VERSION ""

NS_ :

BS_:

BU_: BCM BMS_12V CMS_D CMS_P DSMU ECDO METER MID PBD PSB_D PSB_P PSCU RSCU2R RSCU3R SCCM SRVM VSP

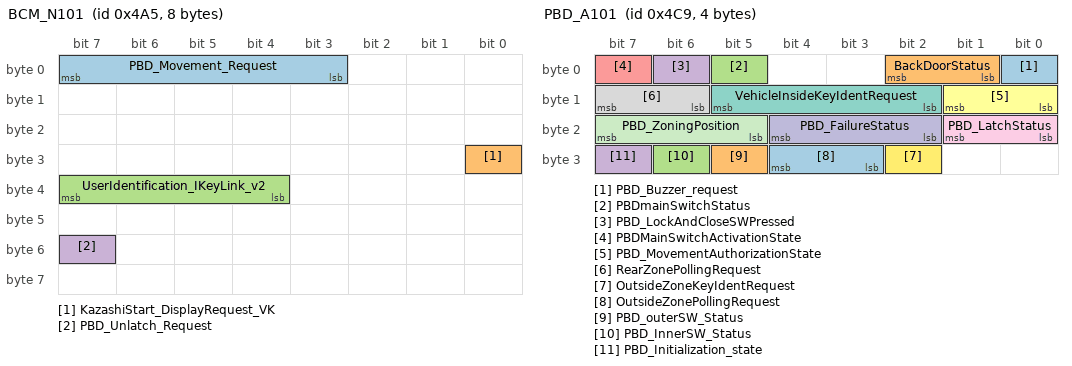
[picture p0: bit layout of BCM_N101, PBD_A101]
BO_ 1189 BCM_N101: 8 BCM
  SG_ PBD_Movement_Request : 7|5@0+ (1,0) [0|0] "" PBD
  SG_ KazashiStart_DisplayRequest_VK : 24|1@0+ (1,0) [0|0] "" METER
  SG_ UserIdentification_IKeyLink_v2 : 39|4@0+ (1,0) [0|0] "" CMS_D,CMS_P,DSMU,METER
  SG_ PBD_Unlatch_Request : 55|1@0+ (1,0) [0|0] "" PBD

BO_ 1191 VADA_R1: 1 BCM
  SG_ VADA_FailureDisplayRequest : 5|1@0+ (1,0) [0|0] "" METER

BO_ 1202 AVM_A102: 6 BCM
  SG_ APA_CancelReasonRER : 26|1@0+ (1,0) [0|0] "" METER
  SG_ APA_CancelReason : 28|2@0+ (1,0) [0|0] "" METER

BO_ 1203 FRCAMERA_A110: 5 BCM
  SG_ OSPSpeedLimit_Display : 7|8@0+ (1,5) [5|200] "Kmh/Mph" METER
  SG_ CruiseControlOSPDisplayRequest : 28|2@0+ (1,0) [0|0] "" METER
  SG_ OSPSpeedLimitZone2_Display : 39|8@0+ (1,5) [5|200] "s" METER

BO_ 1208 AirSUSP_A102: 4 BCM
  SG_ CRC_AirSUSP_A102 : 7|8@0+ (1,0) [0|255] "" METER
  SG_ AirSusp_CurrentHeightDisplay : 11|3@0+ (1,0) [0|0] "" METER
  SG_ Clock_AirSUSP_A102 : 15|4@0+ (1,0) [0|15] "" METER
  SG_ AirSusp_OperationStatusDisplay : 23|2@0+ (1,0) [0|0] "" METER

BO_ 1221 BSWL_A6: 2 BCM
  SG_ BSWrad_ActivationStateSlave : 15|1@0+ (1,0) [0|0] "" METER

BO_ 1225 PBD_A101: 4 PBD
  SG_ PBD_Buzzer_request : 0|1@0+ (1,0) [0|0] "" BCM
  SG_ BackDoorStatus : 2|2@0+ (1,0) [0|0] "" BCM
  SG_ PBDmainSwitchStatus : 5|1@0+ (1,0) [0|0] "" BCM
  SG_ PBD_LockAndCloseSWPressed : 6|1@0+ (1,0) [0|0] "" BCM
  SG_ PBDMainSwitchActivationState : 7|1@0+ (1,0) [0|0] "" METER
  SG_ PBD_MovementAuthorizationState : 9|2@0+ (1,0) [0|0] "" BCM
  SG_ VehicleInsideKeyIdentRequest : 13|4@0+ (1,0) [0|0] "" BCM
  SG_ RearZonePollingRequest : 15|2@0+ (1,0) [0|0] "" BCM
  SG_ PBD_LatchStatus : 17|2@0+ (1,0) [0|0] "" BCM
  SG_ PBD_FailureStatus : 20|3@0+ (1,0) [0|0] "" BCM
  SG_ PBD_ZoningPosition : 23|3@0+ (1,0) [0|0] "" BCM
  SG_ OutsideZoneKeyIdentRequest : 26|1@0+ (1,0) [0|0] "" BCM
  SG_ OutsideZonePollingRequest : 28|2@0+ (1,0) [0|0] "" BCM
  SG_ PBD_outerSW_Status : 29|1@0+ (1,0) [0|0] "" BCM
  SG_ PBD_InnerSW_Status : 30|1@0+ (1,0) [0|0] "" BCM
  SG_ PBD_Initialization_state : 31|1@0+ (1,0) [0|0] "" BCM

BO_ 1227 BCM_A124: 2 BCM
  SG_ AmbiLightADLINKTypeStatus : 0|2@0+ (1,0) [0|0] "" METER
  SG_ AmbiLightADColorStatus : 7|7@0+ (1,0) [0|0] "" METER

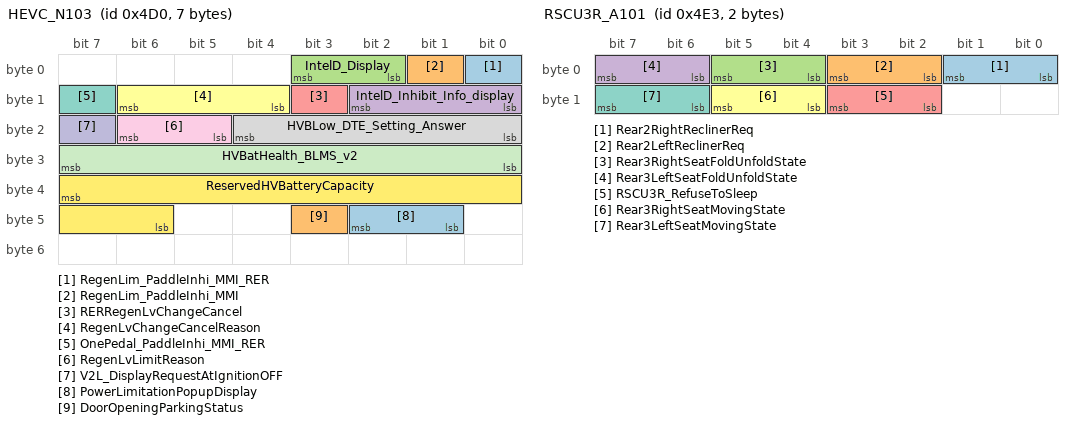
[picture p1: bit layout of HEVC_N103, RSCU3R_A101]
BO_ 1232 HEVC_N103: 7 BCM
  SG_ RegenLim_PaddleInhi_MMI_RER : 0|1@0+ (1,0) [0|0] "" METER
  SG_ RegenLim_PaddleInhi_MMI : 1|1@0+ (1,0) [0|0] "" METER
  SG_ IntelD_Display : 3|2@0+ (1,0) [0|0] "" METER
  SG_ IntelD_Inhibit_Info_display : 10|3@0+ (1,0) [0|0] "" METER
  SG_ RERRegenLvChangeCancel : 11|1@0+ (1,0) [0|0] "" METER
  SG_ RegenLvChangeCancelReason : 14|3@0+ (1,0) [0|0] "" METER
  SG_ OnePedal_PaddleInhi_MMI_RER : 15|1@0+ (1,0) [0|0] "" METER
  SG_ HVBLow_DTE_Setting_Answer : 20|5@0+ (1,0) [0|0] "" METER
  SG_ RegenLvLimitReason : 22|2@0+ (1,0) [0|0] "" METER
  SG_ V2L_DisplayRequestAtIgnitionOFF : 23|1@0+ (1,0) [0|0] "" METER
  SG_ HVBatHealth_BLMS_v2 : 31|8@0+ (0.4,0) [0|100] "%" METER
  SG_ ReservedHVBatteryCapacity : 39|10@0+ (0.1,0) [0|100] "kWh" METER
  SG_ PowerLimitationPopupDisplay : 42|2@0+ (1,0) [0|0] "" METER
  SG_ DoorOpeningParkingStatus : 43|1@0+ (1,0) [0|0] "" METER

BO_ 1237 METER_N102: 4 METER
  SG_ MIDLuminosity : 7|8@0+ (0.4,0) [0|100] "%" MID
  SG_ CIDLuminosity : 15|8@0+ (0.4,0) [0|100] "%" MID

BO_ 1239 ECM_R103: 7 BCM
  SG_ LPGFuelLevelPercentage_MMI : 39|8@0+ (0.5,0) [0|100] "%" METER

BO_ 1241 HFM_A9: 1 BCM
  SG_ CustomerIdentType : 7|1@0+ (1,0) [0|0] "" METER

BO_ 1251 RSCU3R_A101: 2 RSCU3R
  SG_ Rear2RightReclinerReq : 1|2@0+ (1,0) [0|0] "" RSCU2R
  SG_ Rear2LeftReclinerReq : 3|2@0+ (1,0) [0|0] "" RSCU2R
  SG_ Rear3RightSeatFoldUnfoldState : 5|2@0+ (1,0) [0|0] "" BCM
  SG_ Rear3LeftSeatFoldUnfoldState : 7|2@0+ (1,0) [0|0] "" BCM
  SG_ RSCU3R_RefuseToSleep : 11|2@0+ (1,0) [0|0] "" BCM
  SG_ Rear3RightSeatMovingState : 13|2@0+ (1,0) [0|0] "" BCM
  SG_ Rear3LeftSeatMovingState : 15|2@0+ (1,0) [0|0] "" BCM

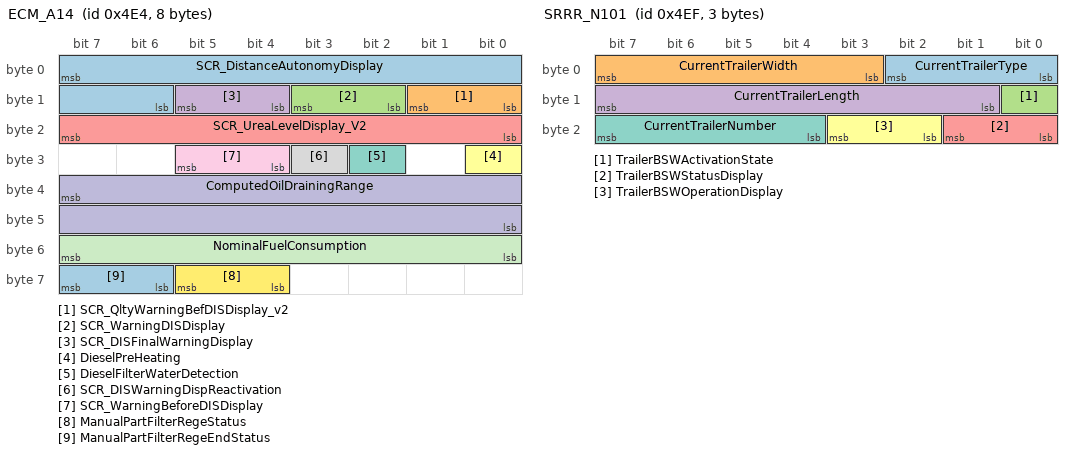
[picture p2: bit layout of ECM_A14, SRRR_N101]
BO_ 1252 ECM_A14: 8 BCM
  SG_ SCR_DistanceAutonomyDisplay : 7|10@0+ (1,0) [0|1022] "km" METER
  SG_ SCR_QltyWarningBefDISDisplay_v2 : 9|2@0+ (1,0) [0|0] "" METER
  SG_ SCR_WarningDISDisplay : 11|2@0+ (1,0) [0|0] "" METER
  SG_ SCR_DISFinalWarningDisplay : 13|2@0+ (1,0) [0|0] "" METER
  SG_ SCR_UreaLevelDisplay_V2 : 23|8@0+ (0.5,0) [0|100] "%" METER
  SG_ DieselPreHeating : 24|1@0+ (1,0) [0|0] "" METER
  SG_ DieselFilterWaterDetection : 26|1@0+ (1,0) [0|0] "" METER
  SG_ SCR_DISWarningDispReactivation : 27|1@0+ (1,0) [0|0] "" METER
  SG_ SCR_WarningBeforeDISDisplay : 29|2@0+ (1,0) [0|0] "" METER
  SG_ ComputedOilDrainingRange : 39|16@0+ (1,0) [0|65534] "km" METER
  SG_ NominalFuelConsumption : 55|8@0+ (80,0) [0|20400] "mm3" METER
  SG_ ManualPartFilterRegeStatus : 61|2@0+ (1,0) [0|0] "" METER
  SG_ ManualPartFilterRegeEndStatus : 63|2@0+ (1,0) [0|0] "" METER

BO_ 1263 SRRR_N101: 3 BCM
  SG_ CurrentTrailerType : 2|3@0+ (1,0) [0|0] "" METER
  SG_ CurrentTrailerWidth : 7|5@0+ (0.25,0) [0.25|7.25] "m" METER
  SG_ TrailerBSWActivationState : 8|1@0+ (1,0) [0|0] "" METER
  SG_ CurrentTrailerLength : 15|7@0+ (0.25,0) [0.25|31.25] "m" METER
  SG_ TrailerBSWStatusDisplay : 17|2@0+ (1,0) [0|0] "" METER
  SG_ TrailerBSWOperationDisplay : 19|2@0+ (1,0) [0|0] "" METER
  SG_ CurrentTrailerNumber : 23|4@0+ (1,0) [0|0] "" METER

BO_ 1271 HEVC_R134: 4 BCM
  SG_ H2_Consumption_kg100km : 7|10@0+ (0.01,0) [0|10] "Kg/100Km" METER
  SG_ CumulatedAutonomyDisplay : 13|11@0+ (1,0) [0|2047] "KM" METER
  SG_ H2AutonomyZEVdisplay : 18|10@0+ (1,0) [0|1022] "-" METER

BO_ 1273 PSD_A103: 1 BCM
  SG_ PSD_Right_BuzzerActivationStatus : 7|1@0+ (1,0) [0|0] "" METER

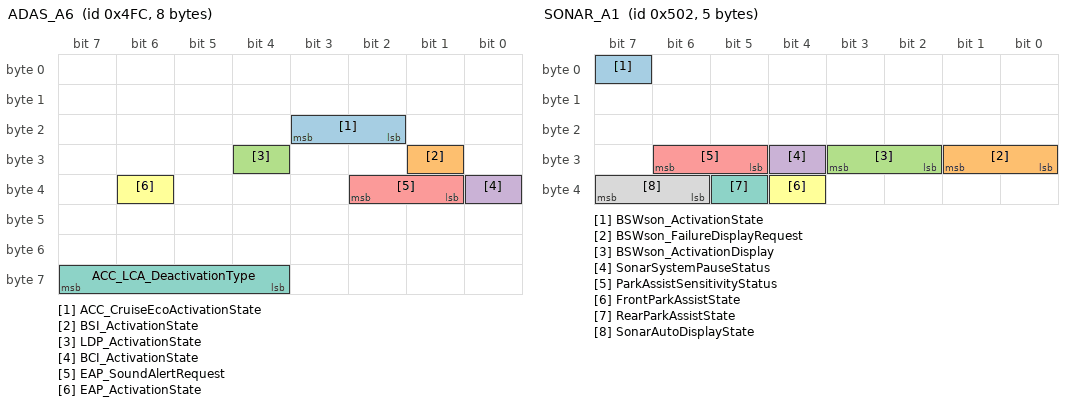
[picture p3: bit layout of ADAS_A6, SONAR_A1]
BO_ 1276 ADAS_A6: 8 BCM
  SG_ ACC_CruiseEcoActivationState : 19|2@0+ (1,0) [0|0] "" METER
  SG_ BSI_ActivationState : 25|1@0+ (1,0) [0|0] "" METER
  SG_ LDP_ActivationState : 28|1@0+ (1,0) [0|0] "" METER
  SG_ BCI_ActivationState : 32|1@0+ (1,0) [0|0] "" METER
  SG_ EAP_SoundAlertRequest : 34|2@0+ (1,0) [0|0] "" METER
  SG_ EAP_ActivationState : 38|1@0+ (1,0) [0|0] "" METER
  SG_ ACC_LCA_DeactivationType : 63|4@0+ (1,0) [0|0] "" METER

BO_ 1278 FrCamADAS_R101: 5 BCM
  SG_ ELKA_ChoiceState : 0|1@0+ (1,0) [0|0] "" METER
  SG_ BSWson_ChoiceState : 2|1@0+ (1,0) [0|0] "" METER
  SG_ BSWrad_ChoiceState : 3|1@0+ (1,0) [0|0] "" METER
  SG_ SpeedLimitNotification : 5|1@0+ (1,0) [0|0] "" METER
  SG_ OverSpeedWarningSoundRER : 6|1@0+ (1,0) [0|0] "" METER
  SG_ OSPOverSpeedDisplayRequestRER : 7|1@0+ (1,0) [0|0] "" METER
  SG_ ADASCarousel_Content : 10|3@0+ (1,0) [0|0] "" METER
  SG_ OverspeedAlertChoiceState : 11|1@0+ (1,0) [0|0] "" METER
  SG_ LDWLKA_ChoiceState : 12|1@0+ (1,0) [0|0] "" METER
  SG_ CustomShield_TransitionStateDisp : 15|3@0+ (1,0) [0|0] "" METER
  SG_ Distraction_ChoiceState : 17|1@0+ (1,0) [0|0] "" METER
  SG_ Fatigue_ChoiceState : 18|1@0+ (1,0) [0|0] "" METER
  SG_ WDA_ChoiceState : 19|1@0+ (1,0) [0|0] "" METER
  SG_ ADASCarousel_SelectedADAS : 22|3@0+ (1,0) [0|0] "" METER
  SG_ ADASCarousel_Display : 23|1@0+ (1,0) [0|0] "" METER
  SG_ LCA_WarningStatus : 26|3@0+ (1,0) [0|0] "" METER
  SG_ V2XEvent_Type : 31|5@0+ (1,0) [0|0] "" METER
  SG_ V2XUnitDistance : 34|2@0+ (1,0) [0|0] "" METER
  SG_ CASP_DisplayContextAdditional : 39|5@0+ (1,0) [0|0] "" METER

BO_ 1279 IVI_A132: 8 BCM
  SG_ DriverTiltMovingReq : 1|2@0+ (1,0) [0|0] "" DSMU
  SG_ DriverLifterMovingReq : 3|2@0+ (1,0) [0|0] "" DSMU
  SG_ DriverReclinerMovingReq : 5|2@0+ (1,0) [0|0] "" DSMU
  SG_ DriverSlideMovingReq : 7|2@0+ (1,0) [0|0] "" DSMU
  SG_ PsSlideMovingReq : 9|2@0+ (1,0) [0|0] "" PSCU
  SG_ DriverBacksidebolsterMovingReq : 11|2@0+ (1,0) [0|0] "" DSMU
  SG_ DriverLumbarMovingReq_Z_Axis : 13|2@0+ (1,0) [0|0] "" DSMU
  SG_ DriverLumbarMovingReq_X_Axis : 15|2@0+ (1,0) [0|0] "" DSMU
  SG_ PsLumbarMovingReq_X_Axis : 17|2@0+ (1,0) [0|0] "" PSCU
  SG_ PsTiltMovingReq : 19|2@0+ (1,0) [0|0] "" PSCU
  SG_ PsLifterMovingReq : 21|2@0+ (1,0) [0|0] "" PSCU
  SG_ PsReclinerMovingReq : 23|2@0+ (1,0) [0|0] "" PSCU
  SG_ Rear2RightSeatFoldUnfoldReq : 25|2@0+ (1,0) [0|0] "" RSCU2R,RSCU3R
  SG_ Rear2LeftSeatFoldUnfoldReq : 27|2@0+ (1,0) [0|0] "" PSCU,RSCU2R,RSCU3R
  SG_ PsBacksidebolsterMovingReq : 29|2@0+ (1,0) [0|0] "" PSCU
  SG_ PsLumbarMovingReq_Z_Axis : 31|2@0+ (1,0) [0|0] "" PSCU
  SG_ Rear2RightSeatWalkinReq : 33|2@0+ (1,0) [0|0] "" RSCU2R
  SG_ Rear2LeftSeatWalkinReq : 35|2@0+ (1,0) [0|0] "" RSCU2R
  SG_ Rear3RightSeatFoldUnfoldReq : 37|2@0+ (1,0) [0|0] "" RSCU2R,RSCU3R
  SG_ Rear3LeftSeatFoldUnfoldReq : 39|2@0+ (1,0) [0|0] "" RSCU2R,RSCU3R

BO_ 1282 SONAR_A1: 5 BCM
  SG_ BSWson_ActivationState : 7|1@0+ (1,0) [0|0] "" METER
  SG_ BSWson_FailureDisplayRequest : 25|2@0+ (1,0) [0|0] "" METER
  SG_ BSWson_ActivationDisplay : 27|2@0+ (1,0) [0|0] "" METER
  SG_ SonarSystemPauseStatus : 28|1@0+ (1,0) [0|0] "" METER
  SG_ ParkAssistSensitivityStatus : 30|2@0+ (1,0) [0|0] "" METER
  SG_ FrontParkAssistState : 36|1@0+ (1,0) [0|0] "" METER
  SG_ RearParkAssistState : 37|1@0+ (1,0) [0|0] "" METER
  SG_ SonarAutoDisplayState : 39|2@0+ (1,0) [0|0] "" METER

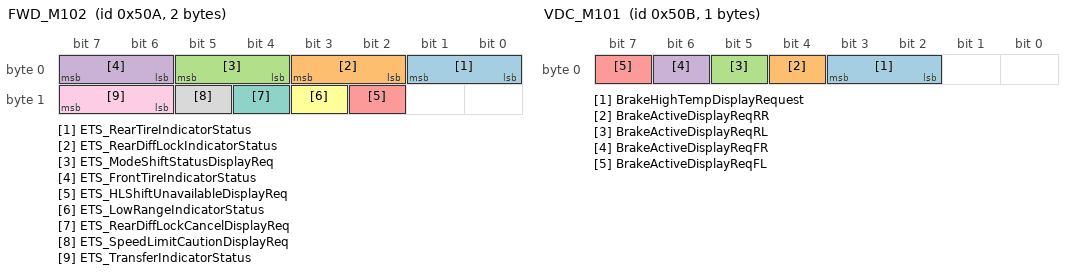
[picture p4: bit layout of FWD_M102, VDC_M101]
BO_ 1290 FWD_M102: 2 BCM
  SG_ ETS_RearTireIndicatorStatus : 1|2@0+ (1,0) [0|0] "" METER
  SG_ ETS_RearDiffLockIndicatorStatus : 3|2@0+ (1,0) [0|0] "" METER
  SG_ ETS_ModeShiftStatusDisplayReq : 5|2@0+ (1,0) [0|0] "" METER
  SG_ ETS_FrontTireIndicatorStatus : 7|2@0+ (1,0) [0|0] "" METER
  SG_ ETS_HLShiftUnavailableDisplayReq : 10|1@0+ (1,0) [0|0] "" METER
  SG_ ETS_LowRangeIndicatorStatus : 11|1@0+ (1,0) [0|0] "" METER
  SG_ ETS_RearDiffLockCancelDisplayReq : 12|1@0+ (1,0) [0|0] "" METER
  SG_ ETS_SpeedLimitCautionDisplayReq : 13|1@0+ (1,0) [0|0] "" METER
  SG_ ETS_TransferIndicatorStatus : 15|2@0+ (1,0) [0|0] "" METER

BO_ 1291 VDC_M101: 1 BCM
  SG_ BrakeHighTempDisplayRequest : 3|2@0+ (1,0) [0|0] "" METER
  SG_ BrakeActiveDisplayReqRR : 4|1@0+ (1,0) [0|0] "" METER
  SG_ BrakeActiveDisplayReqRL : 5|1@0+ (1,0) [0|0] "" METER
  SG_ BrakeActiveDisplayReqFR : 6|1@0+ (1,0) [0|0] "" METER
  SG_ BrakeActiveDisplayReqFL : 7|1@0+ (1,0) [0|0] "" METER

BO_ 1292 IVI_R106: 2 BCM
  SG_ MultimediaSWupdateDisplay : 3|3@0+ (1,0) [0|0] "" METER
  SG_ SafeScore_AdviceMessage : 15|4@0+ (1,0) [0|0] "" METER

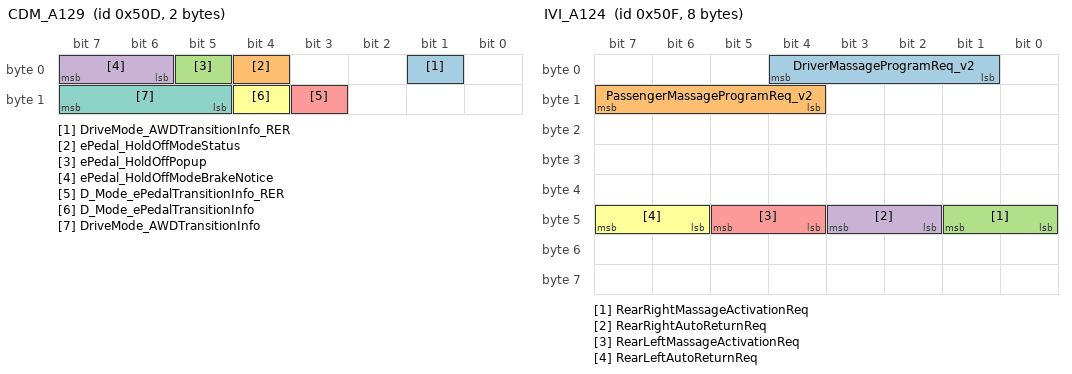
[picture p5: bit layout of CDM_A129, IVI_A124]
BO_ 1293 CDM_A129: 2 BCM
  SG_ DriveMode_AWDTransitionInfo_RER : 1|1@0+ (1,0) [0|0] "" METER
  SG_ ePedal_HoldOffModeStatus : 4|1@0+ (1,0) [0|0] "" METER
  SG_ ePedal_HoldOffPopup : 5|1@0+ (1,0) [0|0] "" METER
  SG_ ePedal_HoldOffModeBrakeNotice : 7|2@0+ (1,0) [0|0] "" METER
  SG_ D_Mode_ePedalTransitionInfo_RER : 11|1@0+ (1,0) [0|0] "" METER
  SG_ D_Mode_ePedalTransitionInfo : 12|1@0+ (1,0) [0|0] "" METER
  SG_ DriveMode_AWDTransitionInfo : 15|3@0+ (1,0) [0|0] "" METER

BO_ 1294 BLM_A102: 1 BCM
  SG_ PersonalDevice_LowBatteryDisplay : 5|1@0+ (1,0) [0|0] "" METER
  SG_ VirtualKeyMenuState : 7|2@0+ (1,0) [0|0] "" METER

BO_ 1295 IVI_A124: 8 BCM
  SG_ DriverMassageProgramReq_v2 : 4|4@0+ (1,0) [0|0] "" DSMU
  SG_ PassengerMassageProgramReq_v2 : 15|4@0+ (1,0) [0|0] "" PSCU
  SG_ RearRightMassageActivationReq : 41|2@0+ (1,0) [0|0] "" RSCU2R
  SG_ RearRightAutoReturnReq : 43|2@0+ (1,0) [0|0] "" RSCU2R
  SG_ RearLeftMassageActivationReq : 45|2@0+ (1,0) [0|0] "" RSCU2R
  SG_ RearLeftAutoReturnReq : 47|2@0+ (1,0) [0|0] "" RSCU2R

BO_ 1296 TCU_A103: 8 BCM
  SG_ Privacy_Display_Request : 43|3@0+ (1,0) [0|0] "" METER
  SG_ Privacy_Mode_State : 46|3@0+ (1,0) [0|0] "" METER

BO_ 1299 SONAR_A3: 5 BCM
  SG_ FKP_ObstacleZone_RF : 1|2@0+ (1,0) [0|0] "" METER
  SG_ FKP_ObstacleZone_LRC : 3|2@0+ (1,0) [0|0] "" METER
  SG_ FKP_ObstacleZone_LFC : 5|2@0+ (1,0) [0|0] "" METER
  SG_ FKP_ObstacleZone_LF : 7|2@0+ (1,0) [0|0] "" METER
  SG_ FKP_ObstacleZone_RRC : 9|2@0+ (1,0) [0|0] "" METER
  SG_ FKP_ObstacleZone_RR : 11|2@0+ (1,0) [0|0] "" METER
  SG_ FKP_ObstacleZone_RL : 13|2@0+ (1,0) [0|0] "" METER
  SG_ FKP_ObstacleZone_RFC : 15|2@0+ (1,0) [0|0] "" METER
  SG_ FKP_FrontMiddleL_Scan : 16|1@0+ (1,0) [0|0] "" METER
  SG_ FKP_FrontFrontR_Scan : 19|1@0+ (1,0) [0|0] "" METER
  SG_ FKP_FrontFrontL_Scan : 21|1@0+ (1,0) [0|0] "" METER
  SG_ FKP_ImageDisplayRequest : 22|1@0+ (1,0) [0|0] "" METER
  SG_ FKP_FrontMiddleR_Scan : 23|1@0+ (1,0) [0|0] "" METER
  SG_ FKP_RearRearR_Scan : 24|1@0+ (1,0) [0|0] "" METER
  SG_ FKP_RearRearL_Scan : 26|1@0+ (1,0) [0|0] "" METER
  SG_ FKP_RearMiddleR_Scan : 28|1@0+ (1,0) [0|0] "" METER
  SG_ FKP_RearMiddleL_Scan : 30|1@0+ (1,0) [0|0] "" METER
  SG_ FKP_ActivationStatus : 39|1@0+ (1,0) [0|0] "" METER

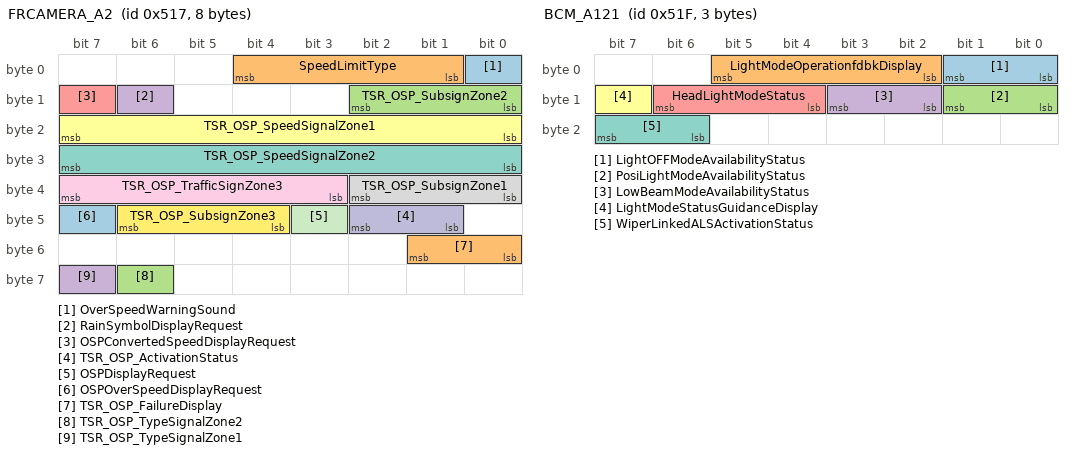
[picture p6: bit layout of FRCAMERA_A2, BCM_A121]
BO_ 1303 FRCAMERA_A2: 8 BCM
  SG_ OverSpeedWarningSound : 0|1@0+ (1,0) [0|0] "" METER
  SG_ SpeedLimitType : 4|4@0+ (1,0) [0|0] "" METER
  SG_ TSR_OSP_SubsignZone2 : 10|3@0+ (1,0) [0|0] "" METER
  SG_ RainSymbolDisplayRequest : 14|1@0+ (1,0) [0|0] "" METER
  SG_ OSPConvertedSpeedDisplayRequest : 15|1@0+ (1,0) [0|0] "" METER
  SG_ TSR_OSP_SpeedSignalZone1 : 23|8@0+ (1,0) [0|200] "wu" METER
  SG_ TSR_OSP_SpeedSignalZone2 : 31|8@0+ (1,0) [0|200] "wu" METER
  SG_ TSR_OSP_SubsignZone1 : 34|3@0+ (1,0) [0|0] "" METER
  SG_ TSR_OSP_TrafficSignZone3 : 39|5@0+ (1,0) [0|0] "" METER
  SG_ TSR_OSP_ActivationStatus : 42|2@0+ (1,0) [0|0] "" METER
  SG_ OSPDisplayRequest : 43|1@0+ (1,0) [0|0] "" METER
  SG_ TSR_OSP_SubsignZone3 : 46|3@0+ (1,0) [0|0] "" METER
  SG_ OSPOverSpeedDisplayRequest : 47|1@0+ (1,0) [0|0] "" METER
  SG_ TSR_OSP_FailureDisplay : 49|2@0+ (1,0) [0|0] "" METER
  SG_ TSR_OSP_TypeSignalZone2 : 62|1@0+ (1,0) [0|0] "" METER
  SG_ TSR_OSP_TypeSignalZone1 : 63|1@0+ (1,0) [0|0] "" METER

BO_ 1307 PBD_A1: 1 PBD
  SG_ PBD_RefuseToSleep : 7|2@0+ (1,0) [0|0] "" BCM

BO_ 1311 BCM_A121: 3 BCM
  SG_ LightOFFModeAvailabilityStatus : 1|2@0+ (1,0) [0|0] "" METER
  SG_ LightModeOperationfdbkDisplay : 5|4@0+ (1,0) [0|0] "" METER
  SG_ PosiLightModeAvailabilityStatus : 9|2@0+ (1,0) [0|0] "" METER
  SG_ LowBeamModeAvailabilityStatus : 11|2@0+ (1,0) [0|0] "" METER
  SG_ HeadLightModeStatus : 14|3@0+ (1,0) [0|0] "" METER
  SG_ LightModeStatusGuidanceDisplay : 15|1@0+ (1,0) [0|0] "" METER
  SG_ WiperLinkedALSActivationStatus : 23|2@0+ (1,0) [0|0] "" METER

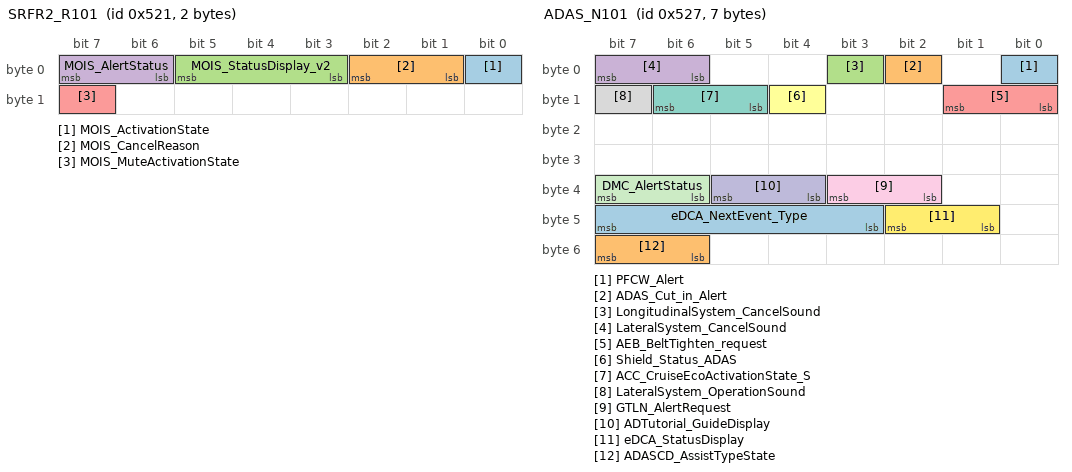
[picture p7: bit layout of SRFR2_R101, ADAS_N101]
BO_ 1313 SRFR2_R101: 2 BCM
  SG_ MOIS_ActivationState : 0|1@0+ (1,0) [0|0] "" METER
  SG_ MOIS_CancelReason : 2|2@0+ (1,0) [0|0] "" METER
  SG_ MOIS_StatusDisplay_v2 : 5|3@0+ (1,0) [0|0] "" METER
  SG_ MOIS_AlertStatus : 7|2@0+ (1,0) [0|0] "" METER
  SG_ MOIS_MuteActivationState : 15|1@0+ (1,0) [0|0] "" METER

BO_ 1315 BCM_A8: 3 BCM
  SG_ AbsoluteTimeSince1rstIgnition : 7|24@0+ (1,0) [0|1.677E7] "min" METER

BO_ 1318 IVI_A3: 6 BCM
  SG_ TripComputer_ResetRequest : 9|1@0+ (1,0) [0|0] "" METER
  SG_ LDW_SoundLevelState_v2 : 12|3@0+ (1,0) [0|0] "" METER

BO_ 1319 ADAS_N101: 7 BCM
  SG_ PFCW_Alert : 0|1@0+ (1,0) [0|0] "" METER
  SG_ ADAS_Cut_in_Alert : 2|1@0+ (1,0) [0|0] "" METER
  SG_ LongitudinalSystem_CancelSound : 3|1@0+ (1,0) [0|0] "" METER
  SG_ LateralSystem_CancelSound : 7|2@0+ (1,0) [0|0] "" METER
  SG_ AEB_BeltTighten_request : 9|2@0+ (1,0) [0|0] "" PSB_D,PSB_P
  SG_ Shield_Status_ADAS : 12|1@0+ (1,0) [0|0] "" METER
  SG_ ACC_CruiseEcoActivationState_S : 14|2@0+ (1,0) [0|0] "" METER
  SG_ LateralSystem_OperationSound : 15|1@0+ (1,0) [0|0] "" METER
  SG_ GTLN_AlertRequest : 35|2@0+ (1,0) [0|0] "" METER
  SG_ ADTutorial_GuideDisplay : 37|2@0+ (1,0) [0|0] "" METER
  SG_ DMC_AlertStatus : 39|2@0+ (1,0) [0|0] "" METER
  SG_ eDCA_StatusDisplay : 42|2@0+ (1,0) [0|0] "" METER
  SG_ eDCA_NextEvent_Type : 47|5@0+ (1,0) [0|0] "" METER
  SG_ ADASCD_AssistTypeState : 55|2@0+ (1,0) [0|0] "" METER

BO_ 1326 ACU_A103: 1 BCM
  SG_ SecondRowCtrRightPresenceState : 2|2@0+ (1,0) [0|0] "" METER
  SG_ SecondRowCtrRightSafetyBeltState : 4|2@0+ (1,0) [0|0] "" METER

BO_ 1328 HEVC_A167: 8 BCM
  SG_ VhMinAutonomyZEVdisplay : 33|10@0+ (1,0) [0|1022] "wu" METER

BO_ 1332 ACU_A101: 8 BCM
  SG_ CRC_ACU_A101 : 7|8@0+ (1,0) [0|255] "" METER
  SG_ AIRBAGMalfunction : 8|1@0+ (1,0) [0|0] "" METER
  SG_ ActiveHoodWarningLampCheck : 9|1@0+ (1,0) [0|0] "" METER
  SG_ ActiveHoodMalfunction : 11|2@0+ (1,0) [0|0] "" METER
  SG_ Clock_ACU_A101 : 15|4@0+ (1,0) [0|15] "" METER
  SG_ PassengerAlertState : 17|2@0+ (1,0) [0|0] "" METER
  SG_ CrashDetectionOutOfOrder_v2 : 20|2@0+ (1,0) [0|0] "" DSMU
  SG_ CrashDetected_v2 : 22|2@0+ (1,0) [0|0] "" BMS_12V,DSMU,PSCU
  SG_ AirbagWarningLampCheck : 23|1@0+ (1,0) [0|0] "" METER
  SG_ SecondRowCenterPresenceState : 26|2@0+ (1,0) [0|0] "" METER
  SG_ RolloverDetectionMalfunction : 27|1@0+ (1,0) [0|0] "" PSB_D,PSB_P
  SG_ PassengerSafetyBeltBuckleState : 29|2@0+ (1,0) [0|0] "" METER
  SG_ PassengerPresenceState : 31|2@0+ (1,0) [0|0] "" METER
  SG_ SecondRowRightPresenceState : 33|2@0+ (1,0) [0|0] "" METER
  SG_ SecondRowLeftSafetyBeltState : 35|2@0+ (1,0) [0|0] "" METER
  SG_ SecondRowLeftPresenceState : 37|2@0+ (1,0) [0|0] "" METER
  SG_ SecondRowCenterSafetyBeltState : 39|2@0+ (1,0) [0|0] "" METER
  SG_ ThirdRowLeftPresenceState : 41|2@0+ (1,0) [0|0] "" METER
  SG_ ThirdRowCenterSafetyBeltState : 43|2@0+ (1,0) [0|0] "" METER
  SG_ ThirdRowCenterPresenceState : 45|2@0+ (1,0) [0|0] "" METER
  SG_ SecondRowRightSafetyBeltState : 47|2@0+ (1,0) [0|0] "" METER
  SG_ FirstRowCenterPresenceState : 49|2@0+ (1,0) [0|0] "" METER
  SG_ ThirdRowRightSafetyBeltState : 51|2@0+ (1,0) [0|0] "" METER
  SG_ ThirdRowRightPresenceState : 53|2@0+ (1,0) [0|0] "" METER
  SG_ ThirdRowLeftSafetyBeltState : 55|2@0+ (1,0) [0|0] "" METER
  SG_ PassengerAIRBAG_Status_Display : 59|2@0+ (1,0) [0|0] "" METER
  SG_ FirstRowCenterSafetyBeltState : 63|2@0+ (1,0) [0|0] "" METER

BO_ 1341 SONAR_A4: 8 BCM
  SG_ UPA_SoundRecurrenceType : 0|1@0+ (1,0) [0|0] "" METER
  SG_ UPA_SoundRecurrencePeriod : 7|7@0+ (0.1,0) [0|12.6] "Hz" METER
  SG_ UPA_SystemState : 9|2@0+ (1,0) [0|0] "" METER
  SG_ UPA_Obstacle_Zone_Front_Right : 12|3@0+ (1,0) [0|0] "" METER
  SG_ UPA_Obstacle_Zone_Front_Left : 15|3@0+ (1,0) [0|0] "" METER
  SG_ UPA_Image_DisplayRequest : 17|2@0+ (1,0) [0|0] "" METER
  SG_ UPA_Obstacle_Zone_Rear_Right : 20|3@0+ (1,0) [0|0] "" METER
  SG_ UPA_Obstacle_Zone_Rear_Left : 23|3@0+ (1,0) [0|0] "" METER
  SG_ UPA_SoundActivationBeep : 24|1@0+ (1,0) [0|0] "" METER
  SG_ UPA_SoundErrorBeep : 25|1@0+ (1,0) [0|0] "" METER
  SG_ UPA_Obstacle_Zone_Rear_Center : 28|3@0+ (1,0) [0|0] "" METER
  SG_ UPA_Obstacle_Zone_Front_Center : 31|3@0+ (1,0) [0|0] "" METER
  SG_ SensorAvailabilityFrontLeft : 32|1@0+ (1,0) [0|0] "" METER
  SG_ SensorAvailabilityFrontCenter : 33|1@0+ (1,0) [0|0] "" METER
  SG_ UPA_SoundObstacleZone : 36|3@0+ (1,0) [0|0] "" METER
  SG_ UPAStatusDisplayRequest : 39|3@0+ (1,0) [0|0] "" METER
  SG_ SensorAvailabilityFrontRight : 40|1@0+ (1,0) [0|0] "" METER
  SG_ SonarObstacleDistanceDisplay : 44|4@0+ (1,0) [0|0] "" METER
  SG_ ParkAssistVolumeState : 47|3@0+ (1,0) [0|0] "" METER
  SG_ SensorAvailabilityRearRight : 53|1@0+ (1,0) [0|0] "" METER
  SG_ SensorAvailabilityRearLeft : 54|1@0+ (1,0) [0|0] "" METER
  SG_ SensorAvailabilityRearCenter : 55|1@0+ (1,0) [0|0] "" METER
  SG_ UPA_ClosingAuthorization : 58|1@0+ (1,0) [0|0] "" METER
  SG_ BSWson_FunctionnalStatus : 60|2@0+ (1,0) [0|0] "" METER

BO_ 1343 HEVC_A110: 4 BCM
  SG_ V2L_InstantPower : 23|7@0+ (0.1,0) [0|12] "kW" METER

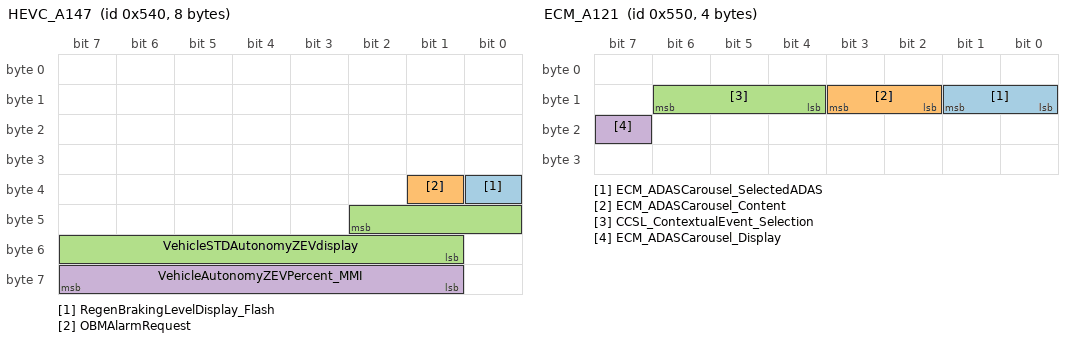
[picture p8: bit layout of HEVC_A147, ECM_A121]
BO_ 1344 HEVC_A147: 8 BCM
  SG_ RegenBrakingLevelDisplay_Flash : 32|1@0+ (1,0) [0|0] "" METER
  SG_ OBMAlarmRequest : 33|1@0+ (1,0) [0|0] "" METER
  SG_ VehicleSTDAutonomyZEVdisplay : 42|10@0+ (1,0) [0|1022] "wu" METER
  SG_ VehicleAutonomyZEVPercent_MMI : 63|7@0+ (1,0) [0|120] "%" METER

BO_ 1346 VSP_A102: 1 VSP
  SG_ VSPfailureDisplay : 7|1@0+ (1,0) [0|0] "" METER

BO_ 1347 ATCU_A113: 3 BCM
  SG_ CRC_ATCU_A113 : 7|8@0+ (1,0) [0|255] "" METER
  SG_ DynamicGridDisplayRequest : 11|1@0+ (1,0) [0|0] "" METER
  SG_ Clock_ATCU_A113 : 15|4@0+ (1,0) [0|15] "" METER
  SG_ ATCVT_RangeIndicationForDisplay : 23|6@0+ (1,0) [0|0] "" METER

BO_ 1355 RSCU2R_A101: 7 RSCU2R
  SG_ RearRightMassageProgramState : 3|4@0+ (1,0) [0|0] "" BCM
  SG_ RearRightMassageActivationState : 4|1@0+ (1,0) [0|0] "" BCM
  SG_ RearLeftMassageActivationState : 5|1@0+ (1,0) [0|0] "" BCM
  SG_ RearRightAutoReturnState : 6|1@0+ (1,0) [0|0] "" BCM
  SG_ RearLeftAutoReturnState : 7|1@0+ (1,0) [0|0] "" BCM
  SG_ Rear2RightSeatWalkinAlert : 9|2@0+ (1,0) [0|0] "" METER
  SG_ RearLeftMassageVelocityState : 12|3@0+ (1,0) [0|0] "" BCM
  SG_ RearRightMassageIntensityState : 15|3@0+ (1,0) [0|0] "" BCM
  SG_ Rear2LeftReclinerPosition : 16|1@0+ (1,0) [0|0] "" RSCU3R
  SG_ RearLeftMassageProgramState : 20|4@0+ (1,0) [0|0] "" BCM
  SG_ RearRightMassageVelocityState : 23|3@0+ (1,0) [0|0] "" BCM
  SG_ Rear2RightReclinerPosition : 24|1@0+ (1,0) [0|0] "" RSCU3R
  SG_ Rear2LeftSeatFoldUnfoldState : 26|2@0+ (1,0) [0|0] "" BCM
  SG_ Rear2RightSeatFoldUnfoldState : 28|2@0+ (1,0) [0|0] "" BCM
  SG_ RearLeftMassageIntensityState : 31|3@0+ (1,0) [0|0] "" BCM
  SG_ DriverReclinerRequest : 33|2@0+ (1,0) [0|0] "" DSMU
  SG_ PassengerReclinerRequest : 35|2@0+ (1,0) [0|0] "" PSCU
  SG_ Rear2LeftSeatWalkinState : 37|2@0+ (1,0) [0|0] "" BCM
  SG_ Rear2RightSeatWalkinState : 39|2@0+ (1,0) [0|0] "" BCM
  SG_ RSCU2R_RefuseToSleep : 41|2@0+ (1,0) [0|0] "" BCM
  SG_ Rear2RightSeatMovingState : 44|3@0+ (1,0) [0|0] "" BCM,PSCU,RSCU3R
  SG_ Rear2LeftSeatMovingState : 47|3@0+ (1,0) [0|0] "" BCM,DSMU,RSCU3R
  SG_ Rear2RightSeatBuzzerRequest : 51|2@0+ (1,0) [0|0] "" RSCU3R
  SG_ Rear2LeftSeatBuzzerRequest : 53|2@0+ (1,0) [0|0] "" RSCU3R
  SG_ Rear2LeftSeatWalkinAlert : 55|2@0+ (1,0) [0|0] "" METER

BO_ 1360 ECM_A121: 4 BCM
  SG_ ECM_ADASCarousel_SelectedADAS : 9|2@0+ (1,0) [0|0] "" METER
  SG_ ECM_ADASCarousel_Content : 11|2@0+ (1,0) [0|0] "" METER
  SG_ CCSL_ContextualEvent_Selection : 14|3@0+ (1,0) [0|0] "" METER
  SG_ ECM_ADASCarousel_Display : 23|1@0+ (1,0) [0|0] "" METER

BO_ 1361 ADAS_A162: 8 BCM
  SG_ CASP_Extended_Speed : 7|8@0+ (1,5) [5|200] "ClusterUnit" METER
  SG_ CASP_Extended_ConvertedSpeed : 15|8@0+ (1,5) [5|200] "ClusterUnit" METER
  SG_ PredictivSpeedLimitConverted : 23|8@0+ (1,0) [0|200] "wu" METER
  SG_ LCDN_ActivationState : 24|2@0+ (1,0) [0|0] "" METER
  SG_ SRad_AlertStatusForCMS : 27|3@0+ (1,0) [0|0] "" CMS_D,CMS_P
  SG_ ACC_TargetDistanceAlert_v2 : 30|3@0+ (1,0) [0|0] "" METER
  SG_ PredicSpeedConvertDisplayRequest : 31|1@0+ (1,0) [0|0] "" METER
  SG_ SET_OffsetValueLocal_State : 34|5@0+ (1,0) [0|0] "" METER
  SG_ LCDN_SensibilityState : 36|2@0+ (1,0) [0|0] "" METER
  SG_ LCDN_AlertRequest : 38|2@0+ (1,0) [0|0] "" METER
  SG_ AntiUndertake_TargetStatus : 43|4@0+ (1,0) [0|0] "" METER
  SG_ AntiUndertake_ActivationStatus : 45|2@0+ (1,0) [0|0] "" METER
  SG_ WDA_WarningDriverAttention_v2 : 51|2@0+ (1,0) [0|0] "" METER
  SG_ ELKA_OTOC_ActivationState : 52|1@0+ (1,0) [0|0] "" METER
  SG_ LKA_DL_ActivationState : 53|1@0+ (1,0) [0|0] "" METER
  SG_ ELKS_ActivationState : 54|1@0+ (1,0) [0|0] "" METER
  SG_ AntiUndertakeDisplayRequest : 55|1@0+ (1,0) [0|0] "" METER
  SG_ DMS_CancelReason : 63|4@0+ (1,0) [0|0] "" METER

BO_ 1364 HVAC_A112: 7 BCM
  SG_ ClimElecConsumptionLimitDisplay : 1|2@0+ (1,0) [0|0] "" METER

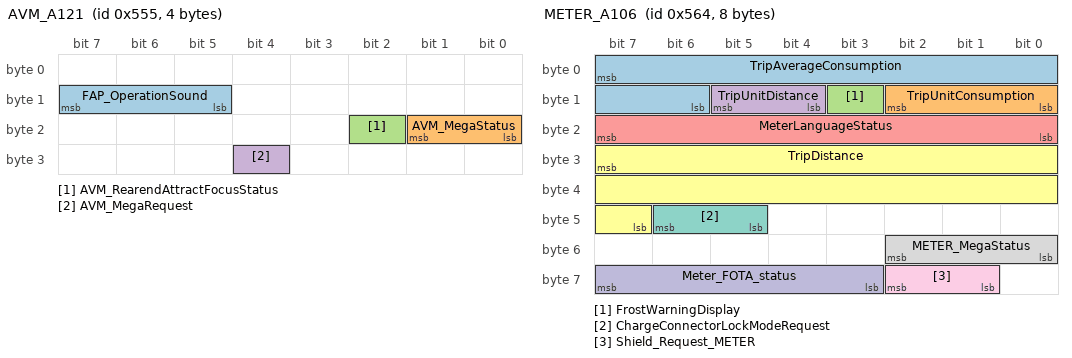
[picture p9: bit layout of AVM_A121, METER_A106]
BO_ 1365 AVM_A121: 4 BCM
  SG_ FAP_OperationSound : 15|3@0+ (1,0) [0|0] "" METER
  SG_ AVM_MegaStatus : 17|2@0+ (1,0) [0|0] "" METER
  SG_ AVM_RearendAttractFocusStatus : 18|1@0+ (1,0) [0|0] "" METER
  SG_ AVM_MegaRequest : 28|1@0+ (1,0) [0|0] "" METER

BO_ 1367 TCU_N105: 6 BCM
  SG_ V2X_ID8_CLW_ActivationState : 0|1@0+ (1,0) [0|0] "" METER
  SG_ V2X_Warning_VehicleType : 3|3@0+ (1,0) [0|0] "" METER
  SG_ V2X_LTA_WarningState : 4|1@0+ (1,0) [0|0] "" METER
  SG_ V2X_ICW_WarningState : 5|1@0+ (1,0) [0|0] "" METER
  SG_ V2X_CLW_WarningState : 6|1@0+ (1,0) [0|0] "" METER
  SG_ V2X_FCW_WarningState : 7|1@0+ (1,0) [0|0] "" METER
  SG_ V2X_ID12_VRUCW_ActivationState : 8|1@0+ (1,0) [0|0] "" METER
  SG_ V2X_ID11_RLVW_ActivationState : 9|1@0+ (1,0) [0|0] "" METER
  SG_ V2X_CLW_ControlLossType : 12|3@0+ (1,0) [0|0] "" METER
  SG_ V2X_RLVW_WarningState : 13|1@0+ (1,0) [0|0] "" METER
  SG_ V2X_VRUCW_WarningState : 14|1@0+ (1,0) [0|0] "" METER
  SG_ V2X_AVW_WarningState : 15|1@0+ (1,0) [0|0] "" METER
  SG_ V2X_MalfunctionState : 16|1@0+ (1,0) [0|0] "" METER
  SG_ V2X_ID16_GLOSA_ActivationState : 17|1@0+ (1,0) [0|0] "" METER
  SG_ V2X_ID7_AVW_ActivationState : 18|1@0+ (1,0) [0|0] "" METER
  SG_ V2X_ID3_LTA_ActivationState : 19|1@0+ (1,0) [0|0] "" METER
  SG_ V2X_ID2_ICW_ActivationState : 20|1@0+ (1,0) [0|0] "" METER
  SG_ V2X_ID1_FCW_ActivationState : 21|1@0+ (1,0) [0|0] "" METER
  SG_ V2X_VRUCW_UserType : 23|2@0+ (1,0) [0|0] "" METER
  SG_ V2X_SubFunctionSwitchState : 31|8@0+ (1,0) [0|0] "" METER
  SG_ V2X_GLOSA_LeftTurnLightColor : 39|3@0+ (1,0) [0|0] "" METER
  SG_ V2X_GLOSA_RightTurnLightColor : 42|3@0+ (1,0) [0|0] "" METER
  SG_ V2X_MainFunctionSwitchState : 43|1@0+ (1,0) [0|0] "" METER

BO_ 1369 ADAS_A125: 8 BCM
  SG_ NextEvent_DisplayRequest : 1|2@0+ (1,0) [0|0] "" METER
  SG_ LCA_TransitionStateDisplay : 4|3@0+ (1,0) [0|0] "" METER
  SG_ Contextual_ModeStatus : 7|3@0+ (1,0) [0|0] "" METER
  SG_ NextEvent_Speed : 15|8@0+ (1,0) [0|200] "wu" METER
  SG_ OSE_RearRightDoorAlert : 17|2@0+ (1,0) [0|0] "" METER
  SG_ OSE_RearLeftDoorAlert : 19|2@0+ (1,0) [0|0] "" METER
  SG_ OSE_FrontLeftDoorAlert : 21|2@0+ (1,0) [0|0] "" METER
  SG_ OSE_FronRightDoorAlert : 23|2@0+ (1,0) [0|0] "" METER
  SG_ ELKA_AlertLeftRequest : 24|3@0+ (1,0) [0|0] "" METER
  SG_ RoadEvent_Alert : 26|2@0+ (1,0) [0|0] "" METER
  SG_ NextEvent_Type : 31|5@0+ (1,0) [0|0] "" METER
  SG_ ContextualEvent_Selection : 34|3@0+ (1,0) [0|0] "" METER
  SG_ ELKA_AlertRightRequest : 37|3@0+ (1,0) [0|0] "" METER
  SG_ OSE_DoorAlertReminder : 49|2@0+ (1,0) [0|0] "" METER
  SG_ OSE_ActivationState : 50|1@0+ (1,0) [0|0] "" METER
  SG_ ELKA_ActivationState : 51|1@0+ (1,0) [0|0] "" METER
  SG_ EgoCarCenteringPosition : 53|2@0+ (1,0) [0|0] "" METER
  SG_ SET_ADL3_State : 61|2@0+ (1,0) [0|0] "" METER
  SG_ SET_ALCP2P_AlertLevel_State : 63|2@0+ (1,0) [0|0] "" METER

BO_ 1376 HEVC_A145: 5 BCM
  SG_ CRC_HEVC_A145 : 7|8@0+ (1,0) [0|255] "" METER
  SG_ Clock_HEVC_A145 : 15|4@0+ (1,0) [0|15] "" METER
  SG_ ChargeTimeDisplayAtEPrct : 20|12@0+ (1,0) [1|4094] "min" METER
  SG_ V2L_ACoutputPowerRemainingtime : 39|7@0+ (0.1,0) [0|10] "kW" METER

BO_ 1380 METER_A106: 8 METER
  SG_ TripAverageConsumption : 7|10@0+ (0.1,0) [0|102.3] "" BCM
  SG_ TripUnitConsumption : 10|3@0+ (1,0) [0|0] "" BCM
  SG_ FrostWarningDisplay : 11|1@0+ (1,0) [0|0] "" BCM
  SG_ TripUnitDistance : 13|2@0+ (1,0) [0|0] "" BCM
  SG_ MeterLanguageStatus : 23|8@0+ (1,0) [0|0] "" BCM
  SG_ TripDistance : 31|17@0+ (0.1,0) [0|13107.1] "" BCM
  SG_ ChargeConnectorLockModeRequest : 46|2@0+ (1,0) [0|0] "" BCM
  SG_ METER_MegaStatus : 50|3@0+ (1,0) [0|0] "" BCM
  SG_ Shield_Request_METER : 58|2@0+ (1,0) [0|0] "" BCM
  SG_ Meter_FOTA_status : 63|5@0+ (1,0) [0|0] "" BCM

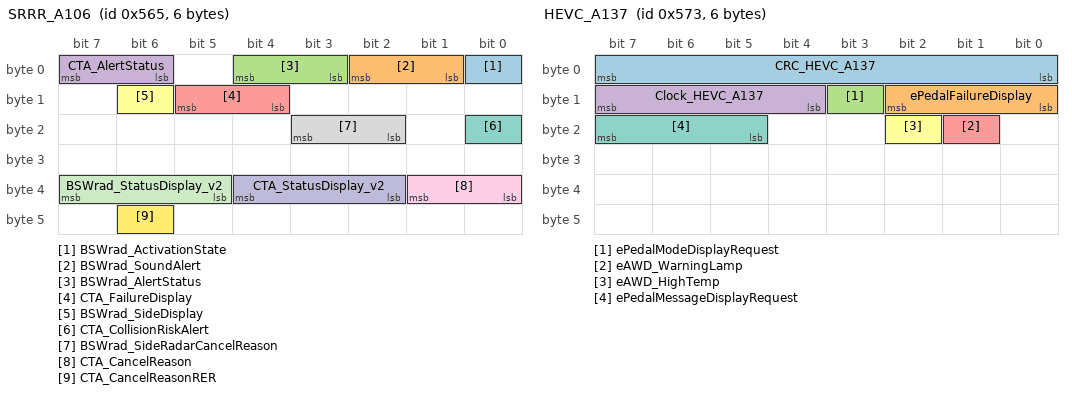
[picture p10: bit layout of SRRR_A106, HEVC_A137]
BO_ 1381 SRRR_A106: 6 BCM
  SG_ BSWrad_ActivationState : 0|1@0+ (1,0) [0|0] "" METER
  SG_ BSWrad_SoundAlert : 2|2@0+ (1,0) [0|0] "" METER
  SG_ BSWrad_AlertStatus : 4|2@0+ (1,0) [0|0] "" CMS_D,CMS_P,METER
  SG_ CTA_AlertStatus : 7|2@0+ (1,0) [0|0] "" METER
  SG_ CTA_FailureDisplay : 13|2@0+ (1,0) [0|0] "" METER
  SG_ BSWrad_SideDisplay : 14|1@0+ (1,0) [0|0] "" METER
  SG_ CTA_CollisionRiskAlert : 16|1@0+ (1,0) [0|0] "" METER
  SG_ BSWrad_SideRadarCancelReason : 19|2@0+ (1,0) [0|0] "" METER
  SG_ CTA_CancelReason : 33|2@0+ (1,0) [0|0] "" METER
  SG_ CTA_StatusDisplay_v2 : 36|3@0+ (1,0) [0|0] "" METER
  SG_ BSWrad_StatusDisplay_v2 : 39|3@0+ (1,0) [0|0] "" METER
  SG_ CTA_CancelReasonRER : 46|1@0+ (1,0) [0|0] "" METER

BO_ 1384 IVI_A123: 8 BCM
  SG_ MexModeState_v3 : 3|4@0+ (1,0) [0|0] "" METER
  SG_ MexAutoState : 4|1@0+ (1,0) [0|0] "" METER

BO_ 1392 IVI_A119: 8 BCM
  SG_ VSPsoundChoiceActivationRequest2 : 4|3@0+ (1,0) [0|0] "" VSP
  SG_ VSPSoundActivationRequest2 : 11|2@0+ (1,0) [0|0] "" VSP

BO_ 1395 HEVC_A137: 6 BCM
  SG_ CRC_HEVC_A137 : 7|8@0+ (1,0) [0|255] "" METER
  SG_ ePedalFailureDisplay : 10|3@0+ (1,0) [0|0] "" METER
  SG_ ePedalModeDisplayRequest : 11|1@0+ (1,0) [0|0] "" METER
  SG_ Clock_HEVC_A137 : 15|4@0+ (1,0) [0|15] "" METER
  SG_ eAWD_WarningLamp : 17|1@0+ (1,0) [0|0] "" METER
  SG_ eAWD_HighTemp : 18|1@0+ (1,0) [0|0] "" METER
  SG_ ePedalMessageDisplayRequest : 23|3@0+ (1,0) [0|0] "" METER

BO_ 1402 ADAS_A103: 8 BCM
  SG_ CASP_ExtendedDisplayContext : 5|3@0+ (1,0) [0|0] "" METER
  SG_ CASP_DisplayRequest : 7|2@0+ (1,0) [0|0] "" METER
  SG_ LDW_LKA_TransitionStateDisplay : 10|3@0+ (1,0) [0|0] "" METER
  SG_ CASP_DisplayContext : 15|4@0+ (1,0) [0|0] "" METER
  SG_ RAB_SideRadarCancelReason : 17|2@0+ (1,0) [0|0] "" METER
  SG_ BCI_StatusDisplay : 21|2@0+ (1,0) [0|0] "" METER
  SG_ LDW_SensibilityState : 29|2@0+ (1,0) [0|0] "" METER
  SG_ LDW_ActivationState_v3 : 31|2@0+ (1,0) [0|0] "" METER
  SG_ LDW_LaneDisplay : 33|2@0+ (1,0) [0|0] "" METER
  SG_ ProPILOTtransitionRequest : 37|1@0+ (1,0) [0|0] "" METER
  SG_ LDW_SoundAlert : 39|2@0+ (1,0) [0|0] "" METER
  SG_ LKA_StatusDisplay_v2 : 40|3@0+ (1,0) [0|0] "" METER
  SG_ EAP_StatusDisplay : 42|2@0+ (1,0) [0|0] "" METER
  SG_ LDW_StatusDisplay_v2 : 45|3@0+ (1,0) [0|0] "" METER
  SG_ AssistanceFunctionStatusDisplay : 47|1@0+ (1,0) [0|0] "" METER
  SG_ LCA_StatusDisplay_v2 : 50|3@0+ (1,0) [0|0] "" METER
  SG_ ELKA_StatusDisplay_v2 : 53|3@0+ (1,0) [0|0] "" METER
  SG_ WDA_StatusDisplay : 57|2@0+ (1,0) [0|0] "" METER
  SG_ DCA_StatusDisplay : 59|2@0+ (1,0) [0|0] "" METER
  SG_ DCA_FailureDisplay : 61|2@0+ (1,0) [0|0] "" METER
  SG_ WDA_FailureDisplay : 63|2@0+ (1,0) [0|0] "" METER

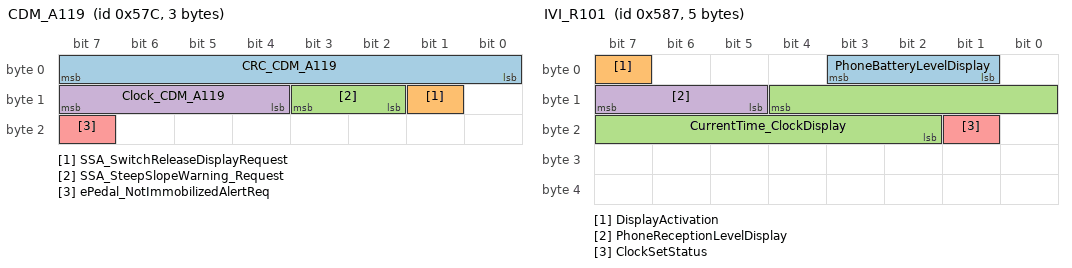
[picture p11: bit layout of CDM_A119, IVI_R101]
BO_ 1404 CDM_A119: 3 BCM
  SG_ CRC_CDM_A119 : 7|8@0+ (1,0) [0|255] "" METER
  SG_ SSA_SwitchReleaseDisplayRequest : 9|1@0+ (1,0) [0|0] "" METER
  SG_ SSA_SteepSlopeWarning_Request : 11|2@0+ (1,0) [0|0] "" METER
  SG_ Clock_CDM_A119 : 15|4@0+ (1,0) [0|15] "" METER
  SG_ ePedal_NotImmobilizedAlertReq : 23|1@0+ (1,0) [0|0] "" METER

BO_ 1406 HEVC_M102: 2 BCM
  SG_ RefuelingDisplay2_v2 : 2|5@0+ (1,0) [0|0] "" METER

BO_ 1412 HVAC_A108: 5 BCM
  SG_ ClimHVpowerLimitationDisplay : 7|2@0+ (1,0) [0|0] "" METER

BO_ 1415 IVI_R101: 5 BCM
  SG_ PhoneBatteryLevelDisplay : 3|3@0+ (1,0) [0|0] "" METER
  SG_ DisplayActivation : 7|1@0+ (1,0) [0|0] "" METER
  SG_ CurrentTime_ClockDisplay : 12|11@0+ (1,0) [0|1440] "min" METER
  SG_ PhoneReceptionLevelDisplay : 15|3@0+ (1,0) [0|0] "" METER
  SG_ ClockSetStatus : 17|1@0+ (1,0) [0|0] "" METER

BO_ 1421 SCCM_A102: 2 SCCM
  SG_ MC_SCCM_Position : 3|4@0+ (1,0) [0|0] "" DSMU
  SG_ SCCM_TelescopicMovDisplayReq : 5|2@0+ (1,0) [0|0] "" BCM
  SG_ SCCM_TiltMovDisplayReq : 7|2@0+ (1,0) [0|0] "" BCM
  SG_ LOBM_SCCM_PositionStatus : 15|3@0+ (1,0) [0|0] "" DSMU

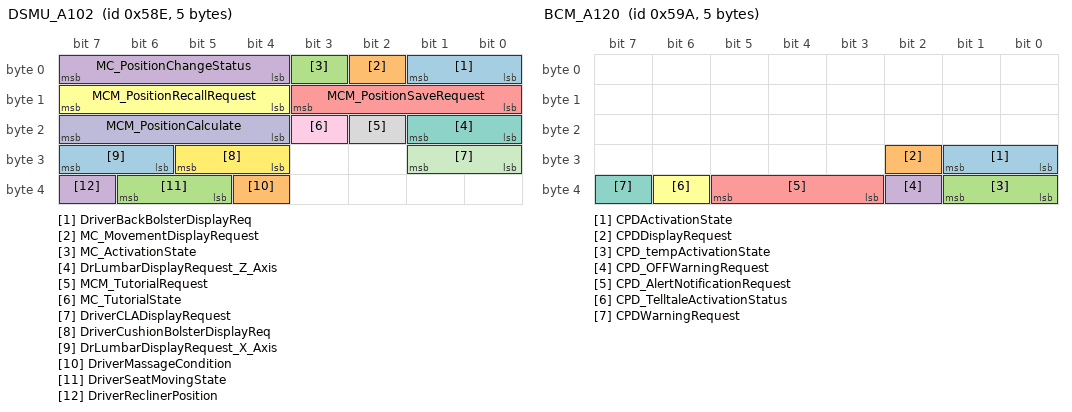
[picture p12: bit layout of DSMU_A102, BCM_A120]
BO_ 1422 DSMU_A102: 5 DSMU
  SG_ DriverBackBolsterDisplayReq : 1|2@0+ (1,0) [0|0] "" BCM
  SG_ MC_MovementDisplayRequest : 2|1@0+ (1,0) [0|0] "" BCM
  SG_ MC_ActivationState : 3|1@0+ (1,0) [0|0] "" BCM
  SG_ MC_PositionChangeStatus : 7|4@0+ (1,0) [0|0] "" BCM
  SG_ MCM_PositionSaveRequest : 11|4@0+ (1,0) [0|0] "" BCM,SCCM
  SG_ MCM_PositionRecallRequest : 15|4@0+ (1,0) [0|0] "" BCM,SCCM
  SG_ DrLumbarDisplayRequest_Z_Axis : 17|2@0+ (1,0) [0|0] "" BCM
  SG_ MCM_TutorialRequest : 18|1@0+ (1,0) [0|0] "" SCCM
  SG_ MC_TutorialState : 19|1@0+ (1,0) [0|0] "" BCM
  SG_ MCM_PositionCalculate : 23|4@0+ (1,0) [0|0] "" BCM,SCCM
  SG_ DriverCLADisplayRequest : 25|2@0+ (1,0) [0|0] "" BCM
  SG_ DriverCushionBolsterDisplayReq : 29|2@0+ (1,0) [0|0] "" BCM
  SG_ DrLumbarDisplayRequest_X_Axis : 31|2@0+ (1,0) [0|0] "" BCM
  SG_ DriverMassageCondition : 36|1@0+ (1,0) [0|0] "" BCM
  SG_ DriverSeatMovingState : 38|2@0+ (1,0) [0|0] "" RSCU2R
  SG_ DriverReclinerPosition : 39|1@0+ (1,0) [0|0] "" RSCU2R

BO_ 1432 ECM_A122: 4 BCM
  SG_ UreaMaxRefill : 7|8@0+ (0.25,0) [0|51] "L" METER
  SG_ UreaMinRefill : 15|8@0+ (0.25,0) [0|51] "L" METER
  SG_ AutoEngShutOffMenuDispReq : 20|2@0+ (1,0) [0|0] "" METER
  SG_ AutoEngShutOffTimeCount : 31|6@0+ (1,0) [0|63] "Second" METER

BO_ 1434 BCM_A120: 5 BCM
  SG_ CPDActivationState : 25|2@0+ (1,0) [0|0] "" METER
  SG_ CPDDisplayRequest : 26|1@0+ (1,0) [0|0] "" METER
  SG_ CPD_tempActivationState : 33|2@0+ (1,0) [0|0] "" METER
  SG_ CPD_OFFWarningRequest : 34|1@0+ (1,0) [0|0] "" METER
  SG_ CPD_AlertNotificationRequest : 37|3@0+ (1,0) [0|0] "" METER
  SG_ CPD_TelltaleActivationStatus : 38|1@0+ (1,0) [0|0] "" METER
  SG_ CPDWarningRequest : 39|1@0+ (1,0) [0|0] "" METER

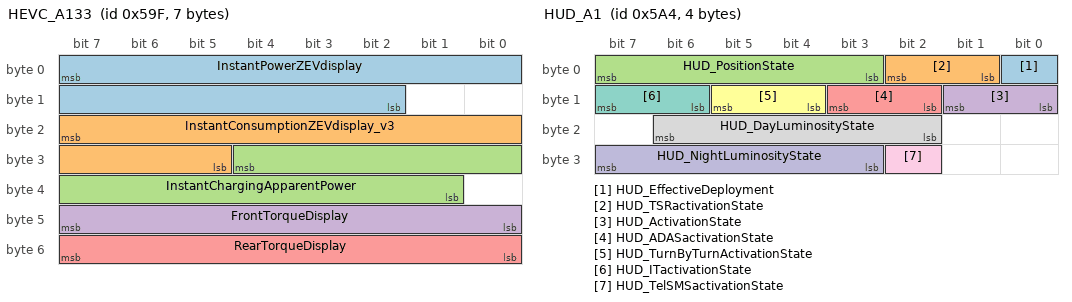
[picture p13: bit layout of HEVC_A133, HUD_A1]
BO_ 1439 HEVC_A133: 7 BCM
  SG_ InstantPowerZEVdisplay : 7|14@0+ (0.1,-500) [-500|500] "kW" METER
  SG_ InstantConsumptionZEVdisplay_v3 : 23|11@0+ (0.1,-102.2) [-102.2|102.2] "" METER
  SG_ InstantChargingApparentPower : 28|12@0+ (0.1,0) [0|400] "kW" METER
  SG_ FrontTorqueDisplay : 47|8@0+ (1,-100) [-100|100] "%" METER
  SG_ RearTorqueDisplay : 55|8@0+ (1,-100) [-100|100] "%" METER

BO_ 1443 HEVC_R104: 8 BCM
  SG_ AverageConsumptionZEV_LastTrip : 11|10@0+ (0.1,0) [0|102.2] "" METER
  SG_ VehicleAutonomyZEVdisplay : 17|10@0+ (1,0) [0|1022] "wu" METER
  SG_ VehicleAutonomyHEVdisplay : 49|10@0+ (1,0) [0|1022] "" METER

BO_ 1444 HUD_A1: 4 BCM
  SG_ HUD_EffectiveDeployment : 0|1@0+ (1,0) [0|0] "" METER
  SG_ HUD_TSRactivationState : 2|2@0+ (1,0) [0|0] "" METER
  SG_ HUD_PositionState : 7|5@0+ (1,0) [0|0] "" METER
  SG_ HUD_ActivationState : 9|2@0+ (1,0) [0|0] "" METER
  SG_ HUD_ADASactivationState : 11|2@0+ (1,0) [0|0] "" METER
  SG_ HUD_TurnByTurnActivationState : 13|2@0+ (1,0) [0|0] "" METER
  SG_ HUD_ITactivationState : 15|2@0+ (1,0) [0|0] "" METER
  SG_ HUD_DayLuminosityState : 22|5@0+ (1,0) [0|0] "" METER
  SG_ HUD_TelSMSactivationState : 26|1@0+ (1,0) [0|0] "" METER
  SG_ HUD_NightLuminosityState : 31|5@0+ (1,0) [0|0] "" METER

BO_ 1454 USM_A104: 4 BCM
  SG_ AFS_FailureDisplay : 0|1@0+ (1,0) [0|0] "" METER
  SG_ LevellingLimitAlert : 12|1@0+ (1,0) [0|0] "" METER
  SG_ ManualLevellingPosition : 15|3@0+ (1,0) [0|0] "" METER

BO_ 1455 VKM_N111: 5 BCM
  SG_ VirtualKey_LowBatteryDisplay : 9|1@0+ (1,0) [0|0] "" METER

BO_ 1456 HEVC_A126: 8 BCM
  SG_ VhPersonalizedAutonomyZEVdisplay : 51|10@0+ (1,0) [0|1022] "wu" METER
  SG_ VehicleZEVAutonomyERPDisplayed : 57|1@0+ (1,0) [0|0] "" METER

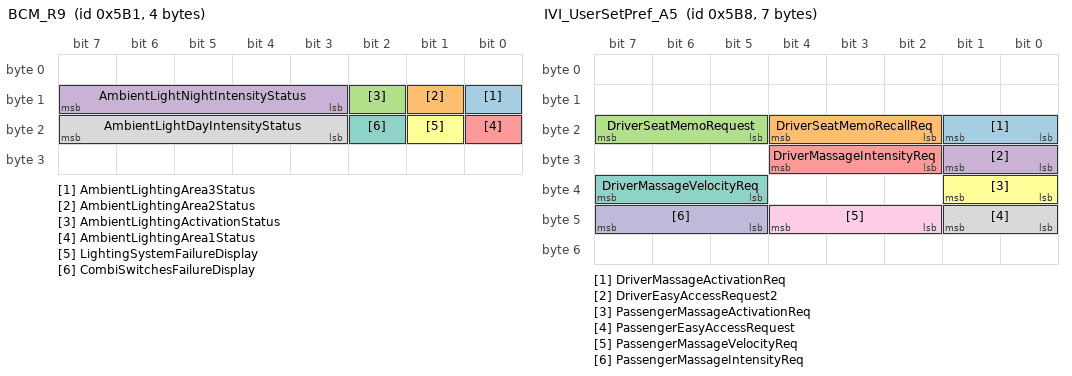
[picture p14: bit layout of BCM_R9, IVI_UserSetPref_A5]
BO_ 1457 BCM_R9: 4 BCM
  SG_ AmbientLightingArea3Status : 8|1@0+ (1,0) [0|0] "" METER
  SG_ AmbientLightingArea2Status : 9|1@0+ (1,0) [0|0] "" METER
  SG_ AmbientLightingActivationStatus : 10|1@0+ (1,0) [0|0] "" METER
  SG_ AmbientLightNightIntensityStatus : 15|5@0+ (5,0) [0|100] "%" METER
  SG_ AmbientLightingArea1Status : 16|1@0+ (1,0) [0|0] "" METER
  SG_ LightingSystemFailureDisplay : 17|1@0+ (1,0) [0|0] "" METER
  SG_ CombiSwitchesFailureDisplay : 18|1@0+ (1,0) [0|0] "" METER
  SG_ AmbientLightDayIntensityStatus : 23|5@0+ (5,0) [0|100] "%" METER

BO_ 1458 HEVC_R112: 8 BCM
  SG_ EcoModePWTcancelReq : 27|2@0+ (1,0) [0|0] "" METER
  SG_ RST_Boost_Launch_Ctrl_Alert_MMI : 53|4@0+ (1,0) [0|0] "" METER

BO_ 1459 AVM_A1: 4 BCM
  SG_ MOD_ActivationState : 3|1@0+ (1,0) [0|0] "" METER
  SG_ MOD_SoundAlertRequest_METER : 14|1@0+ (1,0) [0|0] "" METER

BO_ 1464 IVI_UserSetPref_A5: 7 BCM
  SG_ DriverMassageActivationReq : 17|2@0+ (1,0) [0|0] "" DSMU
  SG_ DriverSeatMemoRecallReq : 20|3@0+ (1,0) [0|0] "" DSMU
  SG_ DriverSeatMemoRequest : 23|3@0+ (1,0) [0|0] "" DSMU
  SG_ DriverEasyAccessRequest2 : 25|2@0+ (1,0) [0|0] "" DSMU
  SG_ DriverMassageIntensityReq : 28|3@0+ (1,0) [0|0] "" DSMU
  SG_ PassengerMassageActivationReq : 33|2@0+ (1,0) [0|0] "" PSCU
  SG_ DriverMassageVelocityReq : 39|3@0+ (1,0) [0|0] "" DSMU
  SG_ PassengerEasyAccessRequest : 41|2@0+ (1,0) [0|0] "" PSCU
  SG_ PassengerMassageVelocityReq : 44|3@0+ (1,0) [0|0] "" PSCU
  SG_ PassengerMassageIntensityReq : 47|3@0+ (1,0) [0|0] "" PSCU

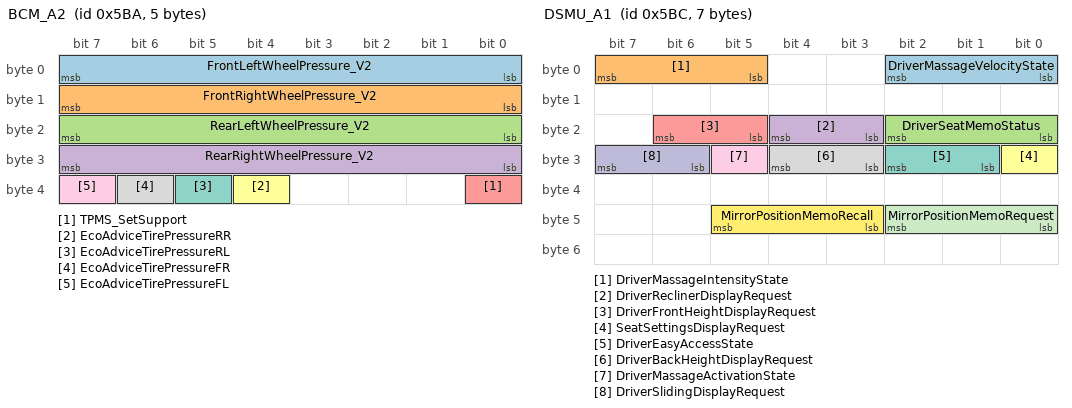
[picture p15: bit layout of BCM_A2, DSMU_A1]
BO_ 1466 BCM_A2: 5 BCM
  SG_ FrontLeftWheelPressure_V2 : 7|8@0+ (30,0) [0|7620] "mbar" METER
  SG_ FrontRightWheelPressure_V2 : 15|8@0+ (30,0) [0|7620] "mbar" METER
  SG_ RearLeftWheelPressure_V2 : 23|8@0+ (30,0) [0|7620] "mbar" METER
  SG_ RearRightWheelPressure_V2 : 31|8@0+ (30,0) [0|7620] "mbar" METER
  SG_ TPMS_SetSupport : 32|1@0+ (1,0) [0|0] "" METER
  SG_ EcoAdviceTirePressureRR : 36|1@0+ (1,0) [0|0] "" METER
  SG_ EcoAdviceTirePressureRL : 37|1@0+ (1,0) [0|0] "" METER
  SG_ EcoAdviceTirePressureFR : 38|1@0+ (1,0) [0|0] "" METER
  SG_ EcoAdviceTirePressureFL : 39|1@0+ (1,0) [0|0] "" METER

BO_ 1468 DSMU_A1: 7 DSMU
  SG_ DriverMassageVelocityState : 2|3@0+ (1,0) [0|0] "" BCM
  SG_ DriverMassageIntensityState : 7|3@0+ (1,0) [0|0] "" BCM
  SG_ DriverSeatMemoStatus : 18|3@0+ (1,0) [0|0] "" BCM
  SG_ DriverReclinerDisplayRequest : 20|2@0+ (1,0) [0|0] "" BCM
  SG_ DriverFrontHeightDisplayRequest : 22|2@0+ (1,0) [0|0] "" BCM
  SG_ SeatSettingsDisplayRequest : 24|1@0+ (1,0) [0|0] "" BCM
  SG_ DriverEasyAccessState : 26|2@0+ (1,0) [0|0] "" BCM,METER
  SG_ DriverBackHeightDisplayRequest : 28|2@0+ (1,0) [0|0] "" BCM
  SG_ DriverMassageActivationState : 29|1@0+ (1,0) [0|0] "" BCM
  SG_ DriverSlidingDisplayRequest : 31|2@0+ (1,0) [0|0] "" BCM
  SG_ MirrorPositionMemoRequest : 42|3@0+ (1,0) [0|0] "" BCM
  SG_ MirrorPositionMemoRecall : 45|3@0+ (1,0) [0|0] "" BCM

BO_ 1469 IVI_UserSetPref_A4: 8 BCM
  SG_ MeterVolumeRequest : 10|3@0+ (1,0) [0|0] "" METER
  SG_ UnitDistanceDisplayRequest : 34|2@0+ (1,0) [0|0] "" METER
  SG_ DimmingReq : 39|5@0+ (1,0) [0|0] "" METER
  SG_ CockpitLanguageRequest : 47|8@0+ (1,0) [0|0] "" METER

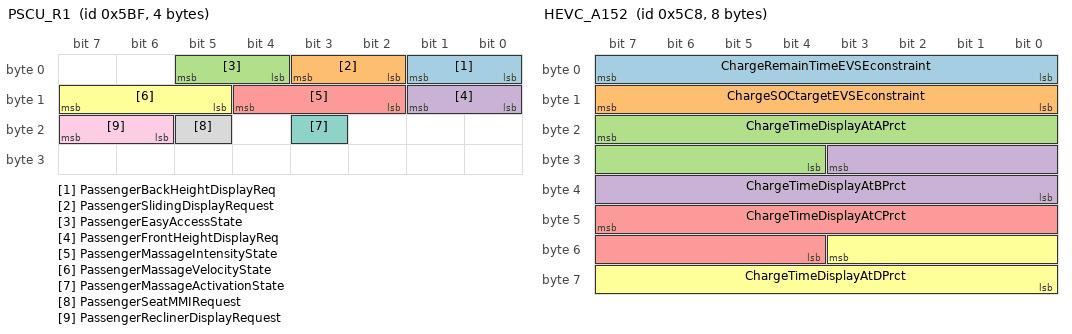
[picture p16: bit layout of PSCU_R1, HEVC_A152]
BO_ 1471 PSCU_R1: 4 PSCU
  SG_ PassengerBackHeightDisplayReq : 1|2@0+ (1,0) [0|0] "" BCM
  SG_ PassengerSlidingDisplayRequest : 3|2@0+ (1,0) [0|0] "" BCM
  SG_ PassengerEasyAccessState : 5|2@0+ (1,0) [0|0] "" BCM,METER
  SG_ PassengerFrontHeightDisplayReq : 9|2@0+ (1,0) [0|0] "" BCM
  SG_ PassengerMassageIntensityState : 12|3@0+ (1,0) [0|0] "" BCM
  SG_ PassengerMassageVelocityState : 15|3@0+ (1,0) [0|0] "" BCM
  SG_ PassengerMassageActivationState : 19|1@0+ (1,0) [0|0] "" BCM
  SG_ PassengerSeatMMIRequest : 21|1@0+ (1,0) [0|0] "" BCM
  SG_ PassengerReclinerDisplayRequest : 23|2@0+ (1,0) [0|0] "" BCM

BO_ 1479 IVI_R102: 6 BCM
  SG_ MC_TutorialRequest_V2 : 4|2@0+ (1,0) [0|0] "" DSMU

BO_ 1480 HEVC_A152: 8 BCM
  SG_ ChargeRemainTimeEVSEconstraint : 7|8@0+ (1,0) [1|254] "min" METER
  SG_ ChargeSOCtargetEVSEconstraint : 15|8@0+ (1,1) [1|254] "" METER
  SG_ ChargeTimeDisplayAtAPrct : 23|12@0+ (1,0) [1|4094] "min" METER
  SG_ ChargeTimeDisplayAtBPrct : 27|12@0+ (1,0) [1|4094] "min" METER
  SG_ ChargeTimeDisplayAtCPrct : 47|12@0+ (1,0) [1|4094] "min" METER
  SG_ ChargeTimeDisplayAtDPrct : 51|12@0+ (1,0) [1|4094] "min" METER

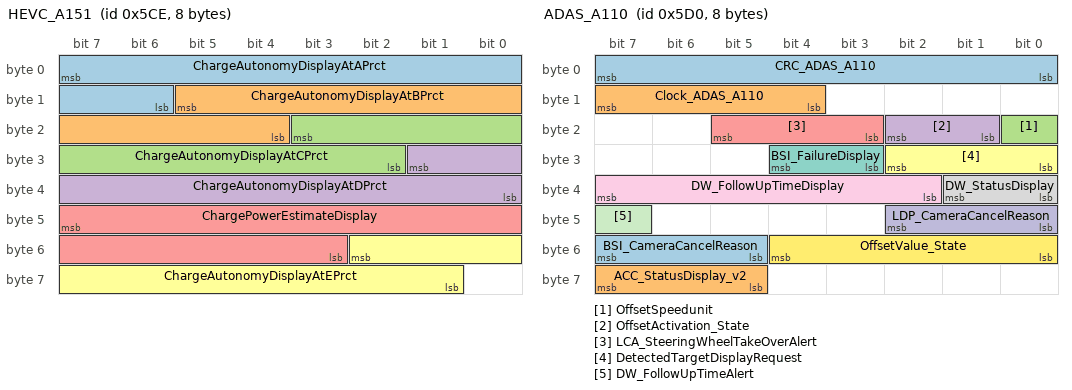
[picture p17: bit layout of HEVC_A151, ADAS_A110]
BO_ 1486 HEVC_A151: 8 BCM
  SG_ ChargeAutonomyDisplayAtAPrct : 7|10@0+ (1,0) [1|1022] "km" METER
  SG_ ChargeAutonomyDisplayAtBPrct : 13|10@0+ (1,0) [1|1022] "km" METER
  SG_ ChargeAutonomyDisplayAtCPrct : 19|10@0+ (1,0) [1|1022] "km" METER
  SG_ ChargeAutonomyDisplayAtDPrct : 25|10@0+ (1,0) [1|1022] "km" METER
  SG_ ChargePowerEstimateDisplay : 47|13@0+ (0.1,0) [0.1|500] "kW" METER
  SG_ ChargeAutonomyDisplayAtEPrct : 50|10@0+ (1,0) [1|1022] "km" METER

BO_ 1488 ADAS_A110: 8 BCM
  SG_ CRC_ADAS_A110 : 7|8@0+ (1,0) [0|255] "" METER
  SG_ Clock_ADAS_A110 : 15|4@0+ (1,0) [0|15] "" METER
  SG_ OffsetSpeedunit : 16|1@0+ (1,0) [0|0] "" METER
  SG_ OffsetActivation_State : 18|2@0+ (1,0) [0|0] "" METER
  SG_ LCA_SteeringWheelTakeOverAlert : 21|3@0+ (1,0) [0|0] "" METER
  SG_ DetectedTargetDisplayRequest : 26|3@0+ (1,0) [0|0] "" METER
  SG_ BSI_FailureDisplay : 28|2@0+ (1,0) [0|0] "" METER
  SG_ DW_StatusDisplay : 33|2@0+ (1,0) [0|0] "" METER
  SG_ DW_FollowUpTimeDisplay : 39|6@0+ (0.1,0) [0|5] "s" METER
  SG_ LDP_CameraCancelReason : 42|3@0+ (1,0) [0|0] "" METER
  SG_ DW_FollowUpTimeAlert : 47|1@0+ (1,0) [0|0] "" METER
  SG_ OffsetValue_State : 52|5@0+ (1,0) [0|0] "" METER
  SG_ BSI_CameraCancelReason : 55|3@0+ (1,0) [0|0] "" METER
  SG_ ACC_StatusDisplay_v2 : 63|3@0+ (1,0) [0|0] "" METER

BO_ 1489 ADAS_A118: 4 BCM
  SG_ AntiUndertake_TargetVehicle_v2 : 31|8@0+ (1,0) [0|0] "" METER

BO_ 1490 HUD_A101: 3 BCM
  SG_ HUD_RotationPositionState : 7|5@0+ (1,0) [0|0] "" METER
  SG_ HUD_SonaractivationState : 10|2@0+ (1,0) [0|0] "" METER
  SG_ HUD_SSAActivationState : 21|2@0+ (1,0) [0|0] "" METER
  SG_ HUD_ShiftActivationState : 23|2@0+ (1,0) [0|0] "" METER

BO_ 1491 METER_UserSetPref_A1: 8 METER
  SG_ AutoFrontWiperActivationRequest : 1|2@0+ (1,0) [0|0] "" BCM
  SG_ AHL_ActivationRequest : 3|2@0+ (1,0) [0|0] "" BCM
  SG_ ParkAssistVolumeRequest : 7|3@0+ (1,0) [0|0] "" BCM
  SG_ IKeyAccessActivationRequest : 9|2@0+ (1,0) [0|0] "" BCM
  SG_ FrontRearWiperDropRequest : 11|2@0+ (1,0) [0|0] "" BCM
  SG_ FrontParkAssistActivationReq : 13|2@0+ (1,0) [0|0] "" BCM
  SG_ AutoRearWiperActivationRequest : 15|2@0+ (1,0) [0|0] "" BCM
  SG_ WGSactivationRequest : 16|2@0+ (1,0) [0|0] "" BCM
  SG_ SingleDoorOpeningActivationReq : 18|2@0+ (1,0) [0|0] "" BCM
  SG_ RearParkAssistActivationReq : 20|2@0+ (1,0) [0|0] "" BCM
  SG_ AutoLightSensitivityRequest : 23|3@0+ (1,0) [0|0] "" BCM
  SG_ AutoReLockActivationReq : 25|2@0+ (1,0) [0|0] "" BCM
  SG_ MotorwayFlashersNumberRequest : 28|3@0+ (1,0) [0|0] "" BCM
  SG_ AutoFMHactivationRequest : 30|2@0+ (1,0) [0|0] "" BCM
  SG_ SilentModeActivationRequest : 33|2@0+ (1,0) [0|0] "" BCM
  SG_ AutoLockActivationReq : 36|3@0+ (1,0) [0|0] "" BCM
  SG_ AutoUnLockActivationReq : 39|3@0+ (1,0) [0|0] "" BCM
  SG_ ParkAssistSensitivityRequest : 44|3@0+ (1,0) [0|0] "" BCM
  SG_ AutoFoldingActivationRequest : 47|3@0+ (1,0) [0|0] "" BCM
  SG_ PredictiveShiftActivationRequest : 49|2@0+ (1,0) [0|0] "" BCM
  SG_ AirCondEcoActivationRequest : 51|2@0+ (1,0) [0|0] "" BCM
  SG_ CruiseEcoActivationRequest : 55|2@0+ (1,0) [0|0] "" BCM
  SG_ AutoFMHdurationRequest : 59|4@0+ (1,0) [0|0] "" BCM
  SG_ ISS_EcoActivationRequest : 63|2@0+ (1,0) [0|0] "" BCM

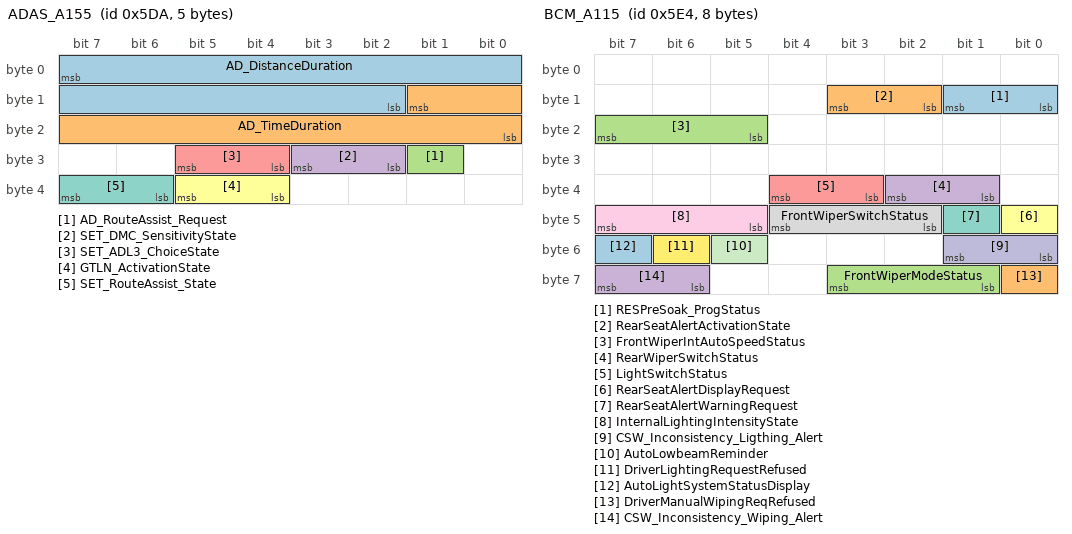
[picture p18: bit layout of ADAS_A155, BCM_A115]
BO_ 1498 ADAS_A155: 5 BCM
  SG_ AD_DistanceDuration : 7|14@0+ (0.1,-0.1) [0|1638] "km" METER
  SG_ AD_TimeDuration : 9|10@0+ (1,-1) [0|1022] "min" METER
  SG_ AD_RouteAssist_Request : 25|1@0+ (1,0) [0|0] "" METER
  SG_ SET_DMC_SensitivityState : 27|2@0+ (1,0) [0|0] "" METER
  SG_ SET_ADL3_ChoiceState : 29|2@0+ (1,0) [0|0] "" METER
  SG_ GTLN_ActivationState : 37|2@0+ (1,0) [0|0] "" METER
  SG_ SET_RouteAssist_State : 39|2@0+ (1,0) [0|0] "" METER

BO_ 1501 FRCAMERA_A109: 5 BCM
  SG_ TSR_OSP_SubsignAdditional_Zone3 : 9|2@0+ (1,0) [0|0] "" METER
  SG_ TSR_OSP_SubsignAdditional_Zone2 : 11|2@0+ (1,0) [0|0] "" METER
  SG_ TSR_OSP_SubsignAdditional_Zone1 : 13|2@0+ (1,0) [0|0] "" METER
  SG_ OverspeedAlertStatusDisplay : 38|2@0+ (1,0) [0|0] "" METER

BO_ 1503 PSCU_A101: 6 PSCU
  SG_ PassengerBackBolsterDisplayReq : 1|2@0+ (1,0) [0|0] "" BCM
  SG_ PSCU_RefuseToSleep : 3|2@0+ (1,0) [0|0] "" BCM
  SG_ PassengerSeatMemoAlertRequest : 4|1@0+ (1,0) [0|0] "" METER
  SG_ PassengerSeatMemoState : 7|3@0+ (1,0) [0|0] "" BCM
  SG_ PassengerSwitchMassageRequest : 9|1@0+ (1,0) [0|0] "" BCM
  SG_ PsgerCushionBolsterDisplayReq : 11|2@0+ (1,0) [0|0] "" BCM
  SG_ PsLumbarDisplayRequest_Z_Axis : 13|2@0+ (1,0) [0|0] "" BCM
  SG_ PsLumbarDisplayRequest_X_Axis : 15|2@0+ (1,0) [0|0] "" BCM
  SG_ PassengerReclinerPosition : 16|1@0+ (1,0) [0|0] "" RSCU2R
  SG_ PassengerCLADisplayRequest : 23|2@0+ (1,0) [0|0] "" BCM
  SG_ PassengerOttomanMotorErrorState : 24|1@0+ (1,0) [0|0] "" BCM
  SG_ PsMassagePopUpActivationState : 25|1@0+ (1,0) [0|0] "" BCM
  SG_ PsMassageExecuteState : 28|3@0+ (1,0) [0|0] "" BCM
  SG_ PassengerMassageCondition : 29|1@0+ (1,0) [0|0] "" BCM
  SG_ PassengerSeatMovingState : 31|2@0+ (1,0) [0|0] "" RSCU2R
  SG_ PassengerLifterMotorErrorState : 32|1@0+ (1,0) [0|0] "" BCM
  SG_ PassengerReclinerMotorErrorState : 34|2@0+ (1,0) [0|0] "" BCM
  SG_ PassengerMemoryPopUpReq : 35|1@0+ (1,0) [0|0] "" BCM
  SG_ PassengerMemorySetState : 36|1@0+ (1,0) [0|0] "" BCM
  SG_ PassengerMemoryRecallState : 39|3@0+ (1,0) [0|0] "" BCM
  SG_ PassengerSlideMotorErrorState : 47|2@0+ (1,0) [0|0] "" BCM

BO_ 1506 BCM_A101: 8 BCM
  SG_ RES_Switcher_Position_Status : 59|2@0+ (1,0) [0|0] "" METER

BO_ 1508 BCM_A115: 8 BCM
  SG_ RESPreSoak_ProgStatus : 9|2@0+ (1,0) [0|0] "" METER
  SG_ RearSeatAlertActivationState : 11|2@0+ (1,0) [0|0] "" METER
  SG_ FrontWiperIntAutoSpeedStatus : 23|3@0+ (1,0) [0|0] "" METER
  SG_ RearWiperSwitchStatus : 34|2@0+ (1,0) [0|0] "" METER
  SG_ LightSwitchStatus : 36|2@0+ (1,0) [0|0] "" METER
  SG_ RearSeatAlertDisplayRequest : 40|1@0+ (1,0) [0|0] "" METER
  SG_ RearSeatAlertWarningRequest : 41|1@0+ (1,0) [0|0] "" METER
  SG_ FrontWiperSwitchStatus : 44|3@0+ (1,0) [0|0] "" METER
  SG_ InternalLightingIntensityState : 47|3@0+ (1,0) [0|0] "" METER
  SG_ CSW_Inconsistency_Ligthing_Alert : 49|2@0+ (1,0) [0|0] "" METER
  SG_ AutoLowbeamReminder : 53|1@0+ (1,0) [0|0] "" METER
  SG_ DriverLightingRequestRefused : 54|1@0+ (1,0) [0|0] "" METER
  SG_ AutoLightSystemStatusDisplay : 55|1@0+ (1,0) [0|0] "" METER
  SG_ DriverManualWipingReqRefused : 56|1@0+ (1,0) [0|0] "" METER
  SG_ FrontWiperModeStatus : 59|3@0+ (1,0) [0|0] "" METER
  SG_ CSW_Inconsistency_Wiping_Alert : 63|2@0+ (1,0) [0|0] "" METER

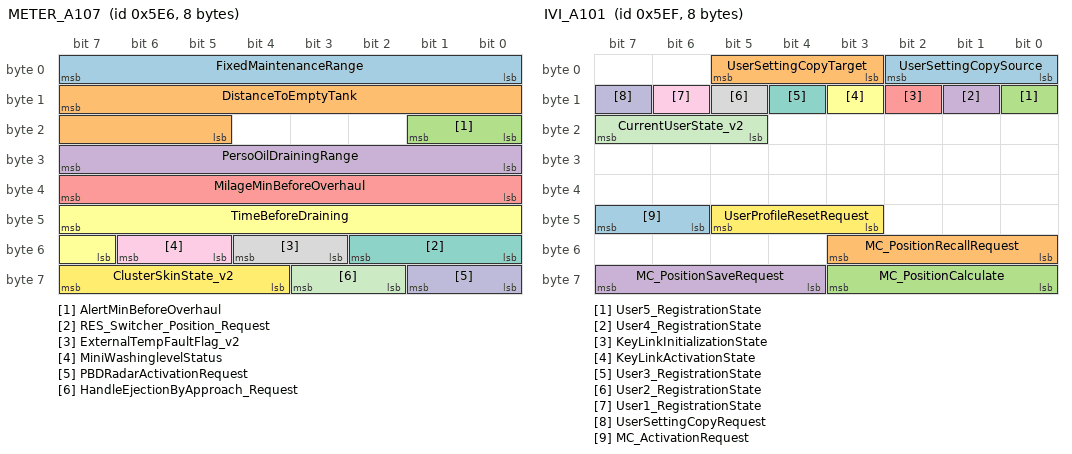
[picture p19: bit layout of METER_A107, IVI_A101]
BO_ 1510 METER_A107: 8 METER
  SG_ FixedMaintenanceRange : 7|8@0+ (250,0) [0|63250] "km" BCM
  SG_ DistanceToEmptyTank : 15|11@0+ (1,0) [0|2046] "km" BCM
  SG_ AlertMinBeforeOverhaul : 17|2@0+ (1,0) [0|0] "" BCM
  SG_ PersoOilDrainingRange : 31|8@0+ (250,0) [0|63500] "km" BCM
  SG_ MilageMinBeforeOverhaul : 39|8@0+ (250,0) [0|63500] "km" BCM
  SG_ TimeBeforeDraining : 47|9@0+ (1,0) [0|511] "day" BCM
  SG_ RES_Switcher_Position_Request : 50|3@0+ (1,0) [0|0] "" BCM
  SG_ ExternalTempFaultFlag_v2 : 52|2@0+ (1,0) [0|0] "" BCM
  SG_ MiniWashinglevelStatus : 54|2@0+ (1,0) [0|0] "" BCM
  SG_ PBDRadarActivationRequest : 57|2@0+ (1,0) [0|0] "" PBD
  SG_ HandleEjectionByApproach_Request : 59|2@0+ (1,0) [0|0] "" BCM
  SG_ ClusterSkinState_v2 : 63|4@0+ (1,0) [0|0] "" BCM

BO_ 1511 BCM_A116: 7 BCM
  SG_ CRC_BCM_A116 : 7|8@0+ (1,0) [0|255] "" METER
  SG_ ShippingModeFR : 8|1@0+ (1,0) [0|0] "" METER
  SG_ ShippingModeFL : 9|1@0+ (1,0) [0|0] "" METER
  SG_ Clock_BCM_A116 : 15|4@0+ (1,0) [0|15] "" METER
  SG_ ShippingModeRR : 16|1@0+ (1,0) [0|0] "" METER
  SG_ ShippingModeRL : 17|1@0+ (1,0) [0|0] "" METER
  SG_ TPMS_PressureFrontAxleState : 23|6@0+ (10,150) [150|760] "kPa" METER
  SG_ TPMS_ActivationMode : 25|2@0+ (1,0) [0|0] "" METER
  SG_ TPMS_PressureRearAxleState : 31|6@0+ (10,150) [150|760] "kPa" METER
  SG_ TPMS_LearningDone : 33|2@0+ (1,0) [0|0] "" METER
  SG_ WheelStateRL : 36|3@0+ (1,0) [0|0] "" METER
  SG_ WheelStateRR : 39|3@0+ (1,0) [0|0] "" METER
  SG_ TPMS_AckResetDriver : 41|2@0+ (1,0) [0|0] "" METER
  SG_ WheelStateFL : 44|3@0+ (1,0) [0|0] "" METER
  SG_ WheelStateFR : 47|3@0+ (1,0) [0|0] "" METER
  SG_ OldPressureFL : 50|1@0+ (1,0) [0|0] "" METER
  SG_ OldPressureFR : 51|1@0+ (1,0) [0|0] "" METER
  SG_ OldPressureRL : 52|1@0+ (1,0) [0|0] "" METER
  SG_ OldPressureRR : 53|1@0+ (1,0) [0|0] "" METER
  SG_ TPMS_AutoLocStatus : 55|2@0+ (1,0) [0|0] "" METER

BO_ 1516 METER_UserSetPref_A2: 8 METER
  SG_ TSR_OSPActivationRequest : 1|2@0+ (1,0) [0|0] "" BCM
  SG_ TPMS_PressureFrontAxleRequest : 7|6@0+ (10,140) [150|760] "kPa" BCM
  SG_ TPMS_PressureRearAxleRequest : 15|6@0+ (10,140) [150|760] "kPa" BCM
  SG_ LDW_ActivationRequest : 17|2@0+ (1,0) [0|0] "" BCM
  SG_ LDW_VibrationIntensityReq : 20|3@0+ (1,0) [0|0] "" BCM
  SG_ LDW_SoundLevelRequest_v2 : 23|3@0+ (1,0) [0|0] "" BCM
  SG_ SailingStopActivationRequest : 25|2@0+ (1,0) [0|0] "" BCM
  SG_ AEB_FCWactivationRequest : 28|3@0+ (1,0) [0|0] "" BCM
  SG_ LDW_SensibilityRequest : 31|3@0+ (1,0) [0|0] "" BCM
  SG_ FKP_ActivationRequest : 33|2@0+ (1,0) [0|0] "" BCM
  SG_ MOD_ActivationRequest : 35|2@0+ (1,0) [0|0] "" BCM
  SG_ SonarAutoDisplayRequest : 37|2@0+ (1,0) [0|0] "" BCM
  SG_ DW_ActivationRequest : 39|2@0+ (1,0) [0|0] "" BCM
  SG_ BSWrad_ActivationRequest : 41|2@0+ (1,0) [0|0] "" BCM
  SG_ HFP_DefaultManeuverTypeRequest : 47|3@0+ (1,0) [0|0] "" BCM
  SG_ LDP_ActivationRequest : 49|2@0+ (1,0) [0|0] "" BCM
  SG_ LKA_ActivationRequest : 51|2@0+ (1,0) [0|0] "" BCM
  SG_ SailingIdleActivationReq : 53|2@0+ (1,0) [0|0] "" BCM
  SG_ UTA_AlertActivationRequest : 55|2@0+ (1,0) [0|0] "" BCM
  SG_ BSI_ActivationRequest : 57|2@0+ (1,0) [0|0] "" BCM
  SG_ CTA_ActivationRequest : 59|2@0+ (1,0) [0|0] "" BCM
  SG_ AFS_ActivationRequest : 61|2@0+ (1,0) [0|0] "" BCM
  SG_ LCA_ActivationRequest : 63|2@0+ (1,0) [0|0] "" BCM

BO_ 1519 IVI_A101: 8 BCM
  SG_ UserSettingCopySource : 2|3@0+ (1,0) [0|0] "" CMS_D,CMS_P,DSMU,METER
  SG_ UserSettingCopyTarget : 5|3@0+ (1,0) [0|0] "" CMS_D,CMS_P,DSMU,METER
  SG_ User5_RegistrationState : 8|1@0+ (1,0) [0|0] "" CMS_D,CMS_P,DSMU,METER
  SG_ User4_RegistrationState : 9|1@0+ (1,0) [0|0] "" CMS_D,CMS_P,DSMU,METER
  SG_ KeyLinkInitializationState : 10|1@0+ (1,0) [0|0] "" CMS_D,CMS_P,DSMU,METER
  SG_ KeyLinkActivationState : 11|1@0+ (1,0) [0|0] "" CMS_D,CMS_P,DSMU,METER
  SG_ User3_RegistrationState : 12|1@0+ (1,0) [0|0] "" CMS_D,CMS_P,DSMU,METER
  SG_ User2_RegistrationState : 13|1@0+ (1,0) [0|0] "" CMS_D,CMS_P,DSMU,METER
  SG_ User1_RegistrationState : 14|1@0+ (1,0) [0|0] "" CMS_D,CMS_P,DSMU,METER
  SG_ UserSettingCopyRequest : 15|1@0+ (1,0) [0|0] "" CMS_D,CMS_P,DSMU,METER
  SG_ CurrentUserState_v2 : 23|3@0+ (1,0) [0|0] "" CMS_D,CMS_P,DSMU,METER,SCCM
  SG_ UserProfileResetRequest : 45|3@0+ (1,0) [0|0] "" DSMU
  SG_ MC_ActivationRequest : 47|2@0+ (1,0) [0|0] "" DSMU
  SG_ MC_PositionRecallRequest : 51|4@0+ (1,0) [0|0] "" DSMU
  SG_ MC_PositionCalculate : 59|4@0+ (1,0) [0|0] "" DSMU
  SG_ MC_PositionSaveRequest : 63|4@0+ (1,0) [0|0] "" DSMU

BO_ 1523 HEVC_R107: 3 BCM
  SG_ HVchargeDisplay : 20|1@0+ (1,0) [0|0] "" METER

VAL_ 1189 PBD_Movement_Request 0 "No request" 1 "Request Close 0%" 2 "Request Open 5%" 3 "Request Open 10%" 4 "Request Open 15%" 5 "Request Open 20%" 6 "Request Open 25%" 7 "Request Open 30%" 8 "Request Open 35%" 9 "Request Open 40%" 10 "Request Open 45%" 11 "Request Open 50%" 12 "Request Open 55%" 13 "Request Open 60%" 14 "Request Open 65%" 15 "Request Open 70%" 16 "Request Open 75%" 17 "Request Open 80%" 18 "Request Open 85%" 19 "Request Open 90%" 20 "Request Open 95%" 21 "Request Open 100%" 22 "Not used" 23 "Not used" 24 "Not used" 25 "Not used" 26 "Not used" 27 "Not used" 28 "Not used" 29 "Not used" 30 "Not used" 31 "Stop";
VAL_ 1189 KazashiStart_DisplayRequest_VK 0 "No Request" 1 "Display Request";
VAL_ 1189 UserIdentification_IKeyLink_v2 0 "No request" 1 "Key No. 1" 2 "Key No. 2" 3 "Key No. 3" 4 "Key No. 4" 5 "Owner Key" 6 "Friend Key ID 1" 7 "Friend Key ID 2" 8 "Friend Key ID 3" 9 "Friend Key ID 4" 10 "Friend Key ID 5" 11 "Not used" 12 "Not used" 13 "Not used" 14 "Not used" 15 "Unavailable";
VAL_ 1189 PBD_Unlatch_Request 0 "No Request" 1 "Unlatch Request";
VAL_ 1191 VADA_FailureDisplayRequest 0 "No VADA failure display request" 1 "VADA failure display request";
VAL_ 1202 APA_CancelReasonRER 0 "no request" 1 "reemission request";
VAL_ 1202 APA_CancelReason 0 "no display" 1 "APA Permanent Failure" 2 "Parking Sensor Permanent Failure" 3 "Not Used";
VAL_ 1203 CruiseControlOSPDisplayRequest 0 "No request" 1 "Set C display request" 2 "Re emission Request" 3 "Not Used";
VAL_ 1208 AirSusp_CurrentHeightDisplay 0 "Not Request" 1 "Access height" 2 "Aero height" 3 "Standard height" 4 "High height" 5 "Reserve" 6 "Reserve" 7 "Reserve";
VAL_ 1208 AirSusp_OperationStatusDisplay 0 "Not Request" 1 "Lowering" 2 "Raising" 3 "Reserve";
VAL_ 1221 BSWrad_ActivationStateSlave 0 "Deactivated" 1 "Activated";
VAL_ 1225 PBD_Buzzer_request 0 "No request" 1 "PBD Buzzer request";
VAL_ 1225 BackDoorStatus 0 "No Activation" 1 "Opening Activation" 2 "Closing Activation" 3 "Lock&Close Activation";
VAL_ 1225 PBDmainSwitchStatus 0 "Power Backdoor Authorized" 1 "Power Backdoor Inhibited";
VAL_ 1225 PBD_LockAndCloseSWPressed 0 "Not Pressed" 1 "Pressed";
VAL_ 1225 PBDMainSwitchActivationState 0 "Power Backdoor Authorized" 1 "Power Backdoor Inhibited";
VAL_ 1225 PBD_MovementAuthorizationState 0 "Unavailable" 1 "All movement authorize" 2 "Close Authorize" 3 "Inhibit";
VAL_ 1225 VehicleInsideKeyIdentRequest 0 "No Request" 1 "ID1 Ident Request" 2 "ID2 Ident Request" 3 "ID3 Ident Request" 4 "ID4 Ident Request" 5 "VK_ID1 Ident Request" 6 "VK_ID2 Ident Request" 7 "VK_ID3 Ident Request" 8 "VK_ID4 Ident Request" 9 "VK_ID5 Ident Request" 10 "VK_ID6 Ident Request" 11 "Not used" 12 "Not used" 13 "Not used" 14 "Not used" 15 "Not used";
VAL_ 1225 RearZonePollingRequest 0 "No Request" 1 "Start Polling" 2 "Stop Polling" 3 "Not Used";
VAL_ 1225 PBD_LatchStatus 0 "Unavailable" 1 "Unlatched" 2 "Latched" 3 "Half Latched";
VAL_ 1225 PBD_FailureStatus 0 "No Failure" 1 "Motor Failure" 2 "Motor Overheating" 3 "Position Failure" 4 "Touch Sens Failure" 5 "ECU Failure" 6 "Supply Failure" 7 "Not Used";
VAL_ 1225 PBD_ZoningPosition 0 "Unavailable" 1 "Full Close" 2 "Mechanical Close" 3 "Middle" 4 "Soft Full Open" 5 "Mechanical Full Open" 6 "Not Used" 7 "Not Used";
VAL_ 1225 OutsideZoneKeyIdentRequest 0 "No Request" 1 "Request";
VAL_ 1225 OutsideZonePollingRequest 0 "No Request" 1 "Start Polling" 2 "Stop Polling" 3 "Not Used";
VAL_ 1225 PBD_outerSW_Status 0 "Not Pressed" 1 "Pressed";
VAL_ 1225 PBD_InnerSW_Status 0 "Not Pressed" 1 "Pressed";
VAL_ 1225 PBD_Initialization_state 0 "Not Initialized" 1 "Initialized";
VAL_ 1227 AmbiLightADLINKTypeStatus 0 "Unavailable" 1 "Type1" 2 "Type2" 3 "Type3";
VAL_ 1227 AmbiLightADColorStatus 0 "Color 1" 1 "Color 2" 2 "Color 3" 3 "Color 4" 4 "Color 5" 5 "Color 6" 6 "Color 7" 7 "Color 8" 8 "Color 9" 9 "Color 10" 10 "Color 11" 11 "Color 12" 12 "Color 13" 13 "Color 14" 14 "Color 15" 15 "Color 16" 16 "Color 17" 17 "Color 18" 18 "Color 19" 19 "Color 20" 20 "Color 21" 21 "Color 22" 22 "Color 23" 23 "Color 24" 24 "Color 25" 25 "Color 26" 26 "Color 27" 27 "Color 28" 28 "Color 29" 29 "Color 30" 30 "Color 31" 31 "Color 32" 32 "Color 33" 33 "Color 34" 34 "Color 35" 35 "Color 36" 36 "Color 37" 37 "Color 38" 38 "Color 39" 39 "Color 40" 40 "Color 41" 41 "Color 42" 42 "Color 43" 43 "Color 44" 44 "Color 45" 45 "Color 46" 46 "Color 47" 47 "Color 48" 48 "Color 49" 49 "Color 50" 50 "Color 51" 51 "Color 52" 52 "Color 53" 53 "Color 54" 54 "Color 55" 55 "Color 56" 56 "Color 57" 57 "Color 58" 58 "Color 59" 59 "Color 60" 60 "Color 61" 61 "Color 62" 62 "Color 63" 63 "Color 64" 64 "Color 65" 65 "Color 66" 66 "Color 67" 67 "Color 68" 68 "Color 69" 69 "Color 70" 70 "Color 71" 71 "Color 72" 72 "Color 73" 73 "Color 74" 74 "Color 75" 75 "Color 76" 76 "Color 77" 77 "Color 78" 78 "Color 79" 79 "Color 80" 80 "Color 81" 81 "Color 82" 82 "Color 83" 83 "Color 84" 84 "Color 85" 85 "Color 86" 86 "Color 87" 87 "Color 88" 88 "Color 89" 89 "Color 90" 90 "Color 91" 91 "Color 92" 92 "Color 93" 93 "Color 94" 94 "Color 95" 95 "Color 96" 96 "Color 97" 97 "Color 98" 98 "Color 99" 99 "Color 100" 100 "Color 101" 101 "Color 102" 102 "Color 103" 103 "Color 104" 104 "Color 105" 105 "Color 106" 106 "Color 107" 107 "Color 108" 108 "Color 109" 109 "Color 110" 110 "Color 111" 111 "Color 112" 112 "Color 113" 113 "Color 114" 114 "Color 115" 115 "Color 116" 116 "Color 117" 117 "Color 118" 118 "Color 119" 119 "Color 120" 120 "Color 121" 121 "Color 122" 122 "Color 123" 123 "Color 124" 124 "Color 125" 125 "Color 126" 126 "Color 127" 127 "Color 128";
VAL_ 1232 RegenLim_PaddleInhi_MMI_RER 0 "no request" 1 "Reemission request";
VAL_ 1232 RegenLim_PaddleInhi_MMI 0 "no request" 1 "Regeneration limited - paddles inhibited";
VAL_ 1232 IntelD_Display 0 "No display" 1 "Intel-D_Active State" 2 "Intel-D_Actibe State_with_leading-car" 3 "Not used";
VAL_ 1232 IntelD_Inhibit_Info_display 0 "No display" 1 "Inhibited by paddle" 2 "Inhibited by shift" 3 "Inhibited by drive mode" 4 "Inhibited by ePedal" 5 "Inhibited by battery" 6 "Not used" 7 "Not used";
VAL_ 1232 RERRegenLvChangeCancel 0 "No request" 1 "Reemission request";
VAL_ 1232 RegenLvChangeCancelReason 0 "No request" 1 "by ePedal on" 2 "by cruise control on" 3 "by Intelligent cruise control on" 4 "by AD on" 5 "by SOC too high" 6 "by EV power reduced" 7 "not used";
VAL_ 1232 OnePedal_PaddleInhi_MMI_RER 0 "no request" 1 "Reemission request";
VAL_ 1232 HVBLow_DTE_Setting_Answer 0 "No request" 1 "10" 2 "15" 3 "20" 4 "25" 5 "30" 6 "35" 7 "40" 8 "45" 9 "50" 10 "55" 11 "60" 12 "65" 13 "70" 14 "75" 15 "80" 16 "85" 17 "90" 18 "95" 19 "100" 20 "105" 21 "110" 22 "115" 23 "120" 24 "125" 25 "130" 26 "135" 27 "140" 28 "145" 29 "150" 30 "OFF" 31 "Reset request";
VAL_ 1232 RegenLvLimitReason 0 "No request" 1 "by SOC too high" 2 "by EV Power reduced" 3 "not used";
VAL_ 1232 V2L_DisplayRequestAtIgnitionOFF 0 "No display" 1 "Display request";
VAL_ 1232 PowerLimitationPopupDisplay 0 "No display" 1 "P3 Popup status Lv.1" 2 "P3 Popup status Lv.2" 3 "P3 Popup status Lv.3";
VAL_ 1232 DoorOpeningParkingStatus 0 "No_DoorOpeningParkingStatus" 1 "DoorOpeningParkingStatus";
VAL_ 1241 CustomerIdentType 0 "Card" 1 "Personal Device";
VAL_ 1251 Rear2RightReclinerReq 0 "no request" 1 "standard position request" 2 "return request" 3 "stop request";
VAL_ 1251 Rear2LeftReclinerReq 0 "no request" 1 "standard position request" 2 "return request" 3 "stop request";
VAL_ 1251 Rear3RightSeatFoldUnfoldState 0 "fixed position" 1 "on going" 2 "not used" 3 "unavailable";
VAL_ 1251 Rear3LeftSeatFoldUnfoldState 0 "fixed position" 1 "on going" 2 "not used" 3 "unavailable";
VAL_ 1251 RSCU3R_RefuseToSleep 0 "Reserved" 1 "Refuse to sleep" 2 "Ready to sleep" 3 "Reserved";
VAL_ 1251 Rear3RightSeatMovingState 0 "Not moving" 1 "During folding" 2 "During unfolding" 3 "Not used";
VAL_ 1251 Rear3LeftSeatMovingState 0 "Not moving" 1 "During folding" 2 "During unfolding" 3 "Not used";
VAL_ 1252 SCR_QltyWarningBefDISDisplay_v2 0 "No Display" 1 "System warning before DIS" 2 "Urea quality warning before DIS" 3 "Urea consumption warning before DIS";
VAL_ 1252 SCR_WarningDISDisplay 0 "NO Warning in DIS" 1 "Warning Level in DIS" 2 "Warning Quality in DIS" 3 "Unavailable";
VAL_ 1252 SCR_DISFinalWarningDisplay 0 "NO Final Warning " 1 "Final Warning Level" 2 "Final Warning Quality" 3 "Unavailable";
VAL_ 1252 DieselPreHeating 0 "No diesel preheating warning" 1 "Diesel preheating warning";
VAL_ 1252 DieselFilterWaterDetection 0 "no water detected in diesel" 1 "water detected in diesel";
VAL_ 1252 SCR_DISWarningDispReactivation 0 "No DIS Warning Display Reactivation" 1 "DIS Warning Display Reactivation";
VAL_ 1252 SCR_WarningBeforeDISDisplay 0 "No Warning before DIS" 1 "Warning Level 1 before DIS" 2 "Warning Level 2 before DIS" 3 "Unavailable";
VAL_ 1252 ManualPartFilterRegeStatus 0 "No DPF rege request" 1 "Rege needed speed condition" 2 "Rege needed" 3 "Rege ongoing";
VAL_ 1252 ManualPartFilterRegeEndStatus 0 "No DPF manual rege" 1 "Manual DPF rege finished and successful" 2 "Manual DPF rege aborted or failed" 3 "Not used";
VAL_ 1263 CurrentTrailerType 0 "No select" 1 "Conventional" 2 "Fifth wheel" 3 "Gooseneck" 4 "Reserve" 5 "Not Used" 6 "Not Used" 7 "Not Used";
VAL_ 1263 TrailerBSWActivationState 0 "Activated" 1 "Deactivated";
VAL_ 1263 TrailerBSWStatusDisplay 0 "No display" 1 "Not operational" 2 "Operational" 3 "Not used";
VAL_ 1263 TrailerBSWOperationDisplay 0 "No display" 1 "Trailer BSW disabled" 2 "Trailer info saved" 3 "Reserve";
VAL_ 1263 CurrentTrailerNumber 0 "No select" 1 "No.1" 2 "No.2" 3 "No.3" 4 "No.4" 5 "No.5" 6 "No.6" 7 "No.7" 8 "No.8" 9 "No.9" 10 "No.10" 11 "Reserve" 12 "Not used" 13 "Not used" 14 "Not used" 15 "Not used";
VAL_ 1273 PSD_Right_BuzzerActivationStatus 0 "Power Slide Door Buzzer Inhibited" 1 "Power Slide Door Buzzer Authorized";
VAL_ 1276 ACC_CruiseEcoActivationState 0 "Unavailable" 1 "ECO activated" 2 "ECO deactivated" 3 "Not used";
VAL_ 1276 BSI_ActivationState 0 "Activated" 1 "Deactivated";
VAL_ 1276 LDP_ActivationState 0 "Activated" 1 "Deactivated";
VAL_ 1276 BCI_ActivationState 0 "Activated" 1 "Deactivated";
VAL_ 1276 EAP_SoundAlertRequest 0 "No Alert" 1 "Alert for accel limitation" 2 "Alert for Braking" 3 "Not used";
VAL_ 1276 EAP_ActivationState 0 "Activated" 1 "Deactivated";
VAL_ 1276 ACC_LCA_DeactivationType 0 "No display" 1 "ACC Deactivation level 1" 2 "ACC Deactivation level 2" 3 "ACC Disconnected level 1" 4 "ACC Disconnected level 2" 5 "LCA  Deactivation level 1" 6 "LCA  Disconnected level 1" 7 "Not used" 8 "Not used" 9 "Not used" 10 "Not used" 11 "Not used" 12 "Not used" 13 "Not used" 14 "Not used" 15 "Not used";
VAL_ 1278 ELKA_ChoiceState 0 "Selected" 1 "Not selected";
VAL_ 1278 BSWson_ChoiceState 0 "Selected" 1 "Not selected";
VAL_ 1278 BSWrad_ChoiceState 0 "Selected" 1 "Not selected";
VAL_ 1278 SpeedLimitNotification 0 "No request" 1 "Notification requested";
VAL_ 1278 OverSpeedWarningSoundRER 0 "No request" 1 "Re emission request";
VAL_ 1278 OSPOverSpeedDisplayRequestRER 0 "No request" 1 "Re emission request";
VAL_ 1278 ADASCarousel_Content 0 "OFF / SL" 1 "OFF / CC / SL" 2 "OFF / ACC / SL" 3 "OFF / AD1 / ACC / SL" 4 "OFF / AD2 / ACC / SL" 5 "Not Used" 6 "Not Used" 7 "Unavailable";
VAL_ 1278 OverspeedAlertChoiceState 0 "Selected" 1 "Not selected";
VAL_ 1278 LDWLKA_ChoiceState 0 "Selected" 1 "Not selected";
VAL_ 1278 CustomShield_TransitionStateDisp 0 "No display" 1 "Custom shield proposal" 2 "Custom shield activated" 3 "Full ADAS shield activated" 4 "Bad configuration" 5 "Not Used" 6 "Not Used" 7 "Not Used";
VAL_ 1278 Distraction_ChoiceState 0 "Selected" 1 "Not selected";
VAL_ 1278 Fatigue_ChoiceState 0 "Selected" 1 "Not selected";
VAL_ 1278 WDA_ChoiceState 0 "Selected" 1 "Not selected";
VAL_ 1278 ADASCarousel_SelectedADAS 0 "OFF" 1 "SL" 2 "CC" 3 "ACC" 4 "AD1" 5 "AD2" 6 "Not Used" 7 "Not Used";
VAL_ 1278 ADASCarousel_Display 0 "No display" 1 "ADAS carousel display";
VAL_ 1278 LCA_WarningStatus 0 "No Display" 1 "Warning only" 2 "Right alert" 3 "Left alert" 4 "Right and left alert" 5 "Not used" 6 "Not used" 7 "Not used";
VAL_ 1278 V2XEvent_Type 0 "No display" 1 "Slippery Road Level 1" 2 "Slippery Road Level 2" 3 "End Of Queue 1" 4 "End Of Queue 2" 5 "Stationary Vehicle Level 1" 6 "Stationary Vehicle Level 2" 7 "Traffic jam Level 1" 8 "Traffic jam Level 2" 9 "Road work Level 1" 10 "Road work Level 2" 11 "Broken down Vehicle Level 1" 12 "Broken down Vehicle Level 2" 13 "Accident Vehicle Level 1" 14 "Accident Vehicle Level 2" 15 "Unknown Obstacle Level 1" 16 "Unknown Obstacle Level 2" 17 "Fog Level 1" 18 "Fog Level 2" 19 "Heavy Rain Level 1" 20 "Heavy Rain Level 2" 21 "Not used" 22 "Not used" 23 "Not used" 24 "Not used" 25 "Not used" 26 "Not used" 27 "Not used" 28 "Not used" 29 "Not used" 30 "Not used" 31 "Unavailable";
VAL_ 1278 V2XUnitDistance 0 "Meter" 1 "Kilometer" 2 "Yard" 3 "Mile";
VAL_ 1278 CASP_DisplayContextAdditional 0 "No request" 1 "Slippery Road" 2 "End Of Queue" 3 "Stationary Vehicle" 4 "Broken down Vehicle" 5 "Accident Vehicle" 6 "Unknown Obstacle" 7 "Fog" 8 "Heavy Rain" 9 "Bump" 10 "T intersection" 11 "Not used" 12 "Not used" 13 "Not used" 14 "Not used" 15 "Not used" 16 "Not used" 17 "Not used" 18 "Not used" 19 "Not used" 20 "Not used" 21 "Not used" 22 "Not used" 23 "Not used" 24 "Not used" 25 "Not used" 26 "Not used" 27 "Not used" 28 "Not used" 29 "Not used" 30 "Not used" 31 "Not available";
VAL_ 1279 DriverTiltMovingReq 0 "no request" 1 "upward moving request" 2 "downward moving request" 3 "not used";
VAL_ 1279 DriverLifterMovingReq 0 "no request" 1 "upward moving request" 2 "downward moving request" 3 "not used";
VAL_ 1279 DriverReclinerMovingReq 0 "no request" 1 "forward moving request" 2 "backward moving request" 3 "not used";
VAL_ 1279 DriverSlideMovingReq 0 "no request" 1 "forward moving request" 2 "backward moving request" 3 "not used";
VAL_ 1279 PsSlideMovingReq 0 "no request" 1 "forward moving request" 2 "backward moving request" 3 "not used";
VAL_ 1279 DriverBacksidebolsterMovingReq 0 "no request" 1 "inflate request" 2 "deflate request" 3 "not used";
VAL_ 1279 DriverLumbarMovingReq_Z_Axis 0 "no request" 1 "upward moving request" 2 "downward moving request" 3 "not used";
VAL_ 1279 DriverLumbarMovingReq_X_Axis 0 "no request" 1 "forward moving request" 2 "backward moving request" 3 "not used";
VAL_ 1279 PsLumbarMovingReq_X_Axis 0 "no request" 1 "forward moving request" 2 "backward moving request" 3 "not used";
VAL_ 1279 PsTiltMovingReq 0 "no request" 1 "upward moving request" 2 "downward moving request" 3 "not used";
VAL_ 1279 PsLifterMovingReq 0 "no request" 1 "upward moving request" 2 "downward moving request" 3 "not used";
VAL_ 1279 PsReclinerMovingReq 0 "no request" 1 "forward moving request" 2 "backward moving request" 3 "not used";
VAL_ 1279 Rear2RightSeatFoldUnfoldReq 0 "No request" 1 "Fold request" 2 "Unfold request" 3 "Stop request";
VAL_ 1279 Rear2LeftSeatFoldUnfoldReq 0 "No request" 1 "Fold request" 2 "Unfold request" 3 "Stop request";
VAL_ 1279 PsBacksidebolsterMovingReq 0 "no request" 1 "inflate request" 2 "deflate request" 3 "not used";
VAL_ 1279 PsLumbarMovingReq_Z_Axis 0 "no request" 1 "upward moving request" 2 "downward moving request" 3 "not used";
VAL_ 1279 Rear2RightSeatWalkinReq 0 "No request" 1 "Walkin request" 2 "Return request" 3 "Stop request";
VAL_ 1279 Rear2LeftSeatWalkinReq 0 "No request" 1 "Walkin request" 2 "Return request" 3 "Stop request";
VAL_ 1279 Rear3RightSeatFoldUnfoldReq 0 "No request" 1 "Fold request" 2 "Unfold request" 3 "Stop request";
VAL_ 1279 Rear3LeftSeatFoldUnfoldReq 0 "No request" 1 "Fold request" 2 "Unfold request" 3 "Stop request";
VAL_ 1282 BSWson_ActivationState 0 "BSW not activated" 1 "BSW activated";
VAL_ 1282 BSWson_FailureDisplayRequest 0 "Unavailable" 1 "No Failure display request" 2 "Failure display request" 3 "Blocked sensor display request";
VAL_ 1282 BSWson_ActivationDisplay 0 "Unavailable" 1 "BSW Deactivation" 2 "BSW Activation" 3 "Not Used";
VAL_ 1282 SonarSystemPauseStatus 0 "System Pause Off" 1 "System Pause On";
VAL_ 1282 ParkAssistSensitivityStatus 0 "Unavailable" 1 "Far Range Detection" 2 "Middle Range Detection " 3 "Near Range Detection";
VAL_ 1282 FrontParkAssistState 0 "Front park assistance de-activated" 1 "Front park assistance activated";
VAL_ 1282 RearParkAssistState 0 "Rear park assistance de-activated" 1 "Rear park assistance activated";
VAL_ 1282 SonarAutoDisplayState 0 "Unavailable" 1 "Auto Display Activation" 2 "Auto Display Deactivation" 3 "Not used";
VAL_ 1290 ETS_RearTireIndicatorStatus 0 "Not active" 1 "Active" 2 "In progress" 3 "not used";
VAL_ 1290 ETS_RearDiffLockIndicatorStatus 0 "Not active" 1 "Active" 2 "In progress" 3 "not used";
VAL_ 1290 ETS_ModeShiftStatusDisplayReq 0 "No request" 1 "Interruption request" 2 "Re-interruption request" 3 "Not Used";
VAL_ 1290 ETS_FrontTireIndicatorStatus 0 "Not active" 1 "Active" 2 "In progress" 3 "not used";
VAL_ 1290 ETS_HLShiftUnavailableDisplayReq 0 "No Display" 1 "Display request";
VAL_ 1290 ETS_LowRangeIndicatorStatus 0 "No Display" 1 "Low Range Active";
VAL_ 1290 ETS_RearDiffLockCancelDisplayReq 0 "No Display" 1 "Display request";
VAL_ 1290 ETS_SpeedLimitCautionDisplayReq 0 "No Display" 1 "Display request";
VAL_ 1290 ETS_TransferIndicatorStatus 0 "Not active" 1 "Active" 2 "In progress" 3 "not used";
VAL_ 1291 BrakeHighTempDisplayRequest 0 "No request" 1 "VDC pre high temp display" 2 "VDC high temp display" 3 "Not used";
VAL_ 1291 BrakeActiveDisplayReqRR 0 "No request" 1 "Request";
VAL_ 1291 BrakeActiveDisplayReqRL 0 "No request" 1 "Request";
VAL_ 1291 BrakeActiveDisplayReqFR 0 "No request" 1 "Request";
VAL_ 1291 BrakeActiveDisplayReqFL 0 "No request" 1 "Request";
VAL_ 1292 MultimediaSWupdateDisplay 0 "No display" 1 "Update on going 0%" 2 "Update on going 25%" 3 "Update on going 50%" 4 "Update on going 75%" 5 "Update on going 100%" 6 "Not Used" 7 "Not Used";
VAL_ 1292 SafeScore_AdviceMessage 0 "No Message" 1 "Message 1" 2 "Message 2" 3 "Message 3" 4 "Message 4" 5 "Message 5" 6 "Message 6" 7 "Message 7" 8 "Message 8" 9 "Message 9" 10 "Message 10" 11 "Not used" 12 "Not used" 13 "Not used" 14 "Not used" 15 "Unavailable";
VAL_ 1293 DriveMode_AWDTransitionInfo_RER 0 "No request" 1 "Reemission request";
VAL_ 1293 ePedal_HoldOffModeStatus 0 "Hold ON mode" 1 "Hold OFF mode";
VAL_ 1293 ePedal_HoldOffPopup 0 "No display" 1 "Pupup request";
VAL_ 1293 ePedal_HoldOffModeBrakeNotice 0 "No display" 1 "Limit Reason 1" 2 "Not used" 3 "Not used";
VAL_ 1293 D_Mode_ePedalTransitionInfo_RER 0 "No request" 1 "Reemission request";
VAL_ 1293 D_Mode_ePedalTransitionInfo 0 "No Display" 1 "Display Drive Mode cancel message";
VAL_ 1293 DriveMode_AWDTransitionInfo 0 "No display" 1 "Transition info 1" 2 "Transition info 2" 3 "Transition info 3" 4 "Transition info 4" 5 "Transition info 5" 6 "Transition info 6" 7 "Unavailable";
VAL_ 1294 PersonalDevice_LowBatteryDisplay 0 "No Alert" 1 "Personal Device Low Battery Display Requested";
VAL_ 1294 VirtualKeyMenuState 0 "Not used" 1 "Activate Menu" 2 "Deactivate Menu" 3 "Not used";
VAL_ 1295 DriverMassageProgramReq_v2 0 "No request" 1 "Program 1 requested" 2 "Program 2 requested" 3 "Program 3 requested" 4 "Program 4 requested" 5 "Program 5 requested" 6 "Program 6 requested" 7 "Program 7 requested" 8 "Program 8 requested" 9 "Program 9 requested" 10 "Program 10 requested" 11 "Program 11 requested" 12 "Program 12 requested" 13 "Program 13 requested" 14 "Program 14 requested" 15 "Reset request";
VAL_ 1295 PassengerMassageProgramReq_v2 0 "No request" 1 "Program 1 requested" 2 "Program 2 requested" 3 "Program 3 requested" 4 "Program 4 requested" 5 "Program 5 requested" 6 "Program 6 requested" 7 "Program 7 requested" 8 "Program 8 requested" 9 "Program 9 requested" 10 "Program 10 requested" 11 "Program 11 requested" 12 "Program 12 requested" 13 "Program 13 requested" 14 "Program 14 requested" 15 "Reset request";
VAL_ 1295 RearRightMassageActivationReq 0 "No request" 1 "Activation request" 2 "Deactivation request" 3 "Reset Request";
VAL_ 1295 RearRightAutoReturnReq 0 "No request" 1 "Activation request" 2 "Deactivation request" 3 "Not Used";
VAL_ 1295 RearLeftMassageActivationReq 0 "No request" 1 "Activation request" 2 "Deactivation request" 3 "Reset Request";
VAL_ 1295 RearLeftAutoReturnReq 0 "No request" 1 "Activation request" 2 "Deactivation request" 3 "Not Used";
VAL_ 1296 Privacy_Display_Request 0 "No display" 1 "Data sharing forbidden" 2 "Data sharing allowed" 3 "Geolocation sharing forbidden" 4 "Reserved" 5 "Reserved" 6 "Reserved" 7 "Unavailable";
VAL_ 1296 Privacy_Mode_State 0 "Data Sharing forbidden" 1 "Data Sharing allowed" 2 "Geolocation Sharing forbidden" 3 "Reserved" 4 "Reserved" 5 "Reserved" 6 "Reserved" 7 "Unavailable";
VAL_ 1299 FKP_ObstacleZone_RF 0 "No detection" 1 "Detect level 1" 2 "Detect level 2" 3 "Detect level 3";
VAL_ 1299 FKP_ObstacleZone_LRC 0 "No detection" 1 "Detect level 1" 2 "Detect level 2" 3 "Detect level 3";
VAL_ 1299 FKP_ObstacleZone_LFC 0 "No detection" 1 "Detect level 1" 2 "Detect level 2" 3 "Detect level 3";
VAL_ 1299 FKP_ObstacleZone_LF 0 "No detection" 1 "Detect level 1" 2 "Detect level 2" 3 "Detect level 3";
VAL_ 1299 FKP_ObstacleZone_RRC 0 "No detection" 1 "Detect level 1" 2 "Detect level 2" 3 "Detect level 3";
VAL_ 1299 FKP_ObstacleZone_RR 0 "No detection" 1 "Detect level 1" 2 "Detect level 2" 3 "Detect level 3";
VAL_ 1299 FKP_ObstacleZone_RL 0 "No detection" 1 "Detect level 1" 2 "Detect level 2" 3 "Detect level 3";
VAL_ 1299 FKP_ObstacleZone_RFC 0 "No detection" 1 "Detect level 1" 2 "Detect level 2" 3 "Detect level 3";
VAL_ 1299 FKP_FrontMiddleL_Scan 0 "Area Not Scanned" 1 "Area Scanned";
VAL_ 1299 FKP_FrontFrontR_Scan 0 "Area Not Scanned" 1 "Area Scanned";
VAL_ 1299 FKP_FrontFrontL_Scan 0 "Area Not Scanned" 1 "Area Scanned";
VAL_ 1299 FKP_ImageDisplayRequest 0 "Display NOT requested" 1 "Display requested";
VAL_ 1299 FKP_FrontMiddleR_Scan 0 "Area Not Scanned" 1 "Area Scanned";
VAL_ 1299 FKP_RearRearR_Scan 0 "Area Not Scanned" 1 "Area Scanned";
VAL_ 1299 FKP_RearRearL_Scan 0 "Area Not Scanned" 1 "Area Scanned";
VAL_ 1299 FKP_RearMiddleR_Scan 0 "Area Not Scanned" 1 "Area Scanned";
VAL_ 1299 FKP_RearMiddleL_Scan 0 "Area Not Scanned" 1 "Area Scanned";
VAL_ 1299 FKP_ActivationStatus 0 "Flank Protection NOT activated" 1 "Flank Protection activated";
VAL_ 1303 OverSpeedWarningSound 0 "Not requested" 1 "Requested";
VAL_ 1303 SpeedLimitType 0 "EUR" 1 "USA white(speed limit)" 2 "CANADA white(speed limit)" 3 "USA yellow(speed limit caution)" 4 "CANADA yellow(speed limit caution)" 5 "JAPAN" 6 "CHINA" 7 "AUSTRALIA" 8 "KOREA" 9 "SOUTH AFRICA" 10 "GULF" 11 "Not used" 12 "Not used" 13 "Not used" 14 "Not used" 15 "Unavailable";
VAL_ 1303 TSR_OSP_SubsignZone2 0 "No Display Request" 1 "Generic SubSign Display Request" 2 "Snow Subsign Display Request" 3 "Towing Subsign Display Request" 4 "Arrow Left subsign Display Request" 5 "Arrow Right subsign Display Request" 6 "Truck" 7 "Refer to TSR_OSP_SubsignAdditional_Zone2";
VAL_ 1303 RainSymbolDisplayRequest 0 "No Rain Symbol Display Request" 1 "Rain Symbol Display Request";
VAL_ 1303 OSPConvertedSpeedDisplayRequest 0 "No Display Request" 1 "Converted Speed Display Request";
VAL_ 1303 TSR_OSP_SpeedSignalZone1 254 "Free speed' Symbol" 255 "No Speed available show ---";
VAL_ 1303 TSR_OSP_SpeedSignalZone2 254 "Free speed' Symbol" 255 "No Speed available show ---";
VAL_ 1303 TSR_OSP_SubsignZone1 0 "No Display Request" 1 "Generic SubSign Display Request" 2 "Snow Subsign Display Request" 3 "Towing Subsign Display Request" 4 "Arrow Left subsign Display Request" 5 "Arrow Right subsign Display Request" 6 "Truck" 7 "Refer to TSR_OSP_SubsignAdditional_Zone1";
VAL_ 1303 TSR_OSP_TrafficSignZone3 0 "No display" 1 "No Overtaking Sign" 2 "End Of No Overtaking Sign" 3 "Contextual Traffic Sign 1" 4 "Contextual Traffic Sign 2" 5 "Contextual Traffic Sign 3" 6 "Contextual Traffic Sign 4" 7 "Contextual Traffic Sign 5" 8 "Contextual Traffic Sign 6" 9 "Contextual Traffic Sign 7" 10 "Contextual Traffic Sign 8" 11 "Contextual Traffic Sign 9" 12 "Contextual Traffic Sign 10" 13 "Contextual Traffic Sign 11" 14 "Contextual Traffic Sign 12" 15 "Contextual Traffic Sign 13" 16 "Contextual Traffic Sign 14" 17 "Contextual Traffic Sign 15" 18 "Contextual Traffic Sign 16" 19 "Contextual Traffic Sign 17" 20 "Contextual Traffic Sign 18" 21 "Contextual Traffic Sign 19" 22 "Contextual Traffic Sign 20" 23 "Contextual Traffic Sign 21" 24 "Contextual Traffic Sign 22" 25 "Contextual Traffic Sign 23" 26 "Contextual Traffic Sign 24" 27 "Contextual Traffic Sign 25" 28 "Contextual Traffic Sign 26" 29 "Contextual Traffic Sign 27" 30 "Contextual Traffic Sign 28" 31 "Contextual Traffic Sign 29";
VAL_ 1303 TSR_OSP_ActivationStatus 0 "Unavailable" 1 "TSR/OSP Activated" 2 "TSR/OSP Not Activated" 3 "Not used";
VAL_ 1303 OSPDisplayRequest 0 "No Display Request" 1 "OSP Display Requested";
VAL_ 1303 TSR_OSP_SubsignZone3 0 "No Display Request" 1 "Generic SubSign Display Request" 2 "Snow Subsign Display Request" 3 "Towing Subsign Display Request" 4 "Arrow Left subsign Display Request" 5 "Arrow Right subsign Display Request" 6 "Truck" 7 "Refer to TSR_OSP_SubsignAdditional_Zone3";
VAL_ 1303 OSPOverSpeedDisplayRequest 0 "No Overspeed alert" 1 "OverSpeedAlert";
VAL_ 1303 TSR_OSP_FailureDisplay 0 "No display" 1 "Temporary failure display" 2 "Permanent failure display" 3 "Not used";
VAL_ 1303 TSR_OSP_TypeSignalZone2 0 "Normal type" 1 "End of limitation type";
VAL_ 1303 TSR_OSP_TypeSignalZone1 0 "Normal type" 1 "End of limitation type";
VAL_ 1307 PBD_RefuseToSleep 0 "reserved" 1 "PBD refuse to sleep" 2 "PBD ready to sleep" 3 "reserved";
VAL_ 1311 LightOFFModeAvailabilityStatus 0 "No display" 1 "Off mode not available" 2 "Off mode available" 3 "Not used";
VAL_ 1311 LightModeOperationfdbkDisplay 0 "No Display" 1 "Long push operation guidance" 2 "OFF mode refused by no parking or speed" 3 "Posi mode refused by speed" 4 "Operation refused by AD" 5 "Reserved" 6 "Reserved" 7 "Reserved" 8 "Reserved" 9 "Reserved" 10 "Reserved" 11 "Reserved" 12 "Reserved" 13 "Reserved" 14 "Not used" 15 "Not used";
VAL_ 1311 PosiLightModeAvailabilityStatus 0 "No display" 1 "Posi mode not available" 2 "Posi mode available" 3 "Not used";
VAL_ 1311 LowBeamModeAvailabilityStatus 0 "No display" 1 "Low beam mode not available" 2 "Low beam mode available" 3 "Not used";
VAL_ 1311 HeadLightModeStatus 0 "No display" 1 "Auto mode" 2 "Lo beam mode" 3 "Position lamp mode" 4 "Off mode" 5 "Reserved" 6 "Reserved" 7 "Reserved";
VAL_ 1311 LightModeStatusGuidanceDisplay 0 "No Display" 1 "Light mode status guidance display";
VAL_ 1311 WiperLinkedALSActivationStatus 0 "Unavailable" 1 "Activated" 2 "Deactivated" 3 "Not used";
VAL_ 1313 MOIS_ActivationState 0 "Activated" 1 "Deactivated";
VAL_ 1313 MOIS_CancelReason 0 "No display" 1 "SideRadar blocked" 2 "Trailer presence" 3 "SideRadar permanent failure";
VAL_ 1313 MOIS_StatusDisplay_v2 0 "No display" 1 "Not operational" 2 "Operational" 3 "Temporary failure" 4 "Permanent failure" 5 "Not Used" 6 "Not Used" 7 "Not Used";
VAL_ 1313 MOIS_AlertStatus 0 "No alert" 1 "Information alert" 2 "Warning alert" 3 "Warning mute alert";
VAL_ 1313 MOIS_MuteActivationState 0 "Mute" 1 "Unmute";
VAL_ 1318 TripComputer_ResetRequest 0 "Reset OnBoardComputer not requested" 1 "Reset OnBoardComputer requested";
VAL_ 1318 LDW_SoundLevelState_v2 0 "Level 0" 1 "Level 1" 2 "Level 2" 3 "Level 3" 4 "Level 4" 5 "Level 5" 6 "Not Used" 7 "Not Used";
VAL_ 1319 PFCW_Alert 0 "No Alert" 1 "Alert";
VAL_ 1319 ADAS_Cut_in_Alert 0 "No alert" 1 "Alert";
VAL_ 1319 LongitudinalSystem_CancelSound 0 "Not requested" 1 "Requested";
VAL_ 1319 LateralSystem_CancelSound 0 "Not requested" 1 "Type1 requested" 2 "Type2 requested" 3 "Not Used";
VAL_ 1319 AEB_BeltTighten_request 0 "No request" 1 "Request" 2 "not used" 3 "unavailable";
VAL_ 1319 Shield_Status_ADAS 0 "FullShield" 1 "Not Full Shield";
VAL_ 1319 ACC_CruiseEcoActivationState_S 0 "Not Used" 1 "Eco activated" 2 "Eco deactivated" 3 "Unavailable";
VAL_ 1319 LateralSystem_OperationSound 0 "Not requested" 1 "Requested";
VAL_ 1319 GTLN_AlertRequest 0 "No alert" 1 "GTLN level1 alert" 2 "GTLN level2 alert" 3 "GTLN with Distraction";
VAL_ 1319 ADTutorial_GuideDisplay 0 "No display" 1 "Recommend using AD (2steps)" 2 "Recommend using AD (1step)" 3 "Not Used";
VAL_ 1319 DMC_AlertStatus 0 "No display" 1 "Blink(working)" 2 "Steady(failure)" 3 "Reserved";
VAL_ 1319 eDCA_StatusDisplay 0 "No request" 1 "Standby Status" 2 "Active Status" 3 "Unavailable";
VAL_ 1319 eDCA_NextEvent_Type 0 "No display" 1 "Right curve" 2 "Speed limit" 3 "Road exit right" 4 "Intersection" 5 "Roundabout" 6 "Stop" 7 "Tollbooth" 8 "Yield sign" 9 "Traffic light" 10 "Traffic jam" 11 "Road work" 12 "Left curve" 13 "Multicurve right-left" 14 "Multicurve left-right" 15 "Bump" 16 "T intersection" 17 "Road exit left" 18 "Slippery Road" 19 "End Of Queue" 20 "Stationary Vehicle" 21 "Broken down Vehicle" 22 "Accident Vehicle" 23 "Unknown Obstacle" 24 "Fog" 25 "Heavy Rain" 26 "Traffic light red" 27 "Traffic light green" 28 "Vehicle" 29 "Not used" 30 "Not used" 31 "Unavailable";
VAL_ 1319 ADASCD_AssistTypeState 0 "Unavailable" 1 "ProPILOT Assist" 2 "Cruise Control" 3 "Not used";
VAL_ 1326 SecondRowCtrRightPresenceState 0 "Not Monitored" 1 "Present" 2 "Absent" 3 "Unknown";
VAL_ 1326 SecondRowCtrRightSafetyBeltState 0 "SB not monitored" 1 "SB unfastened" 2 "SB fastened" 3 "Unavailable";
VAL_ 1332 AIRBAGMalfunction 0 "no AIRBAG system malfunction" 1 "AIRBAG system malfunction";
VAL_ 1332 ActiveHoodWarningLampCheck 0 "Lamp check not activated" 1 "Lamp check activated";
VAL_ 1332 ActiveHoodMalfunction 0 "Not used" 1 "No active hood system malfunction" 2 "Active hood system malfunction" 3 "unavailable";
VAL_ 1332 PassengerAlertState 0 "SB not monitored" 1 "SB unfastened" 2 "SB fastened or passenger absent" 3 "Unavailable";
VAL_ 1332 CrashDetectionOutOfOrder_v2 0 "Detection functional" 1 "Malfunction for rear crash" 2 "Malfunction for side or front crash" 3 "Malfunction for crash detection";
VAL_ 1332 CrashDetected_v2 0 "Reserved for safety" 1 "No crash detected" 2 "Crash detected" 3 "Reserved for safety";
VAL_ 1332 AirbagWarningLampCheck 0 "Lamp check not activated" 1 "Lamp check activated";
VAL_ 1332 SecondRowCenterPresenceState 0 "Not monitored" 1 "Present" 2 "Absent" 3 "Unknown";
VAL_ 1332 RolloverDetectionMalfunction 0 "Normal rollover detection functional " 1 "Malfunction for rollover detection";
VAL_ 1332 PassengerSafetyBeltBuckleState 0 "SB Not monitored" 1 "SB unfastened" 2 "SB fastened" 3 "Unavailable";
VAL_ 1332 PassengerPresenceState 0 "Not monitored" 1 "Present" 2 "Absent" 3 "Unknown";
VAL_ 1332 SecondRowRightPresenceState 0 "Not monitored" 1 "Present" 2 "Absent" 3 "Unknown";
VAL_ 1332 SecondRowLeftSafetyBeltState 0 "SB not monitored" 1 "SB unfastened" 2 "SB fastened" 3 "Unavailable";
VAL_ 1332 SecondRowLeftPresenceState 0 "Not monitored" 1 "Present" 2 "Absent" 3 "Unknown";
VAL_ 1332 SecondRowCenterSafetyBeltState 0 "SB not monitored" 1 "SB unfastened" 2 "SB fastened" 3 "Unavailable";
VAL_ 1332 ThirdRowLeftPresenceState 0 "Not monitored" 1 "Present" 2 "Absent" 3 "Unknown";
VAL_ 1332 ThirdRowCenterSafetyBeltState 0 "SB not monitored" 1 "SB unfastened" 2 "SB fastened" 3 "Unavailable";
VAL_ 1332 ThirdRowCenterPresenceState 0 "Not monitored" 1 "Present" 2 "Absent" 3 "Unknown";
VAL_ 1332 SecondRowRightSafetyBeltState 0 "SB not monitored" 1 "SB unfastened" 2 "SB fastened" 3 "Unavailable";
VAL_ 1332 FirstRowCenterPresenceState 0 "Not monitored" 1 "Present" 2 "Absent" 3 "Unknown";
VAL_ 1332 ThirdRowRightSafetyBeltState 0 "SB not monitored" 1 "SB unfastened" 2 "SB fastened" 3 "Unavailable";
VAL_ 1332 ThirdRowRightPresenceState 0 "Not monitored" 1 "Present" 2 "Absent" 3 "Unknown";
VAL_ 1332 ThirdRowLeftSafetyBeltState 0 "SB not monitored" 1 "SB unfastened" 2 "SB fastened" 3 "Unavailable";
VAL_ 1332 PassengerAIRBAG_Status_Display 0 "No display" 1 "Passenger Airbag not inhibited" 2 "Passenger Airbag inhibited" 3 "Not Used";
VAL_ 1332 FirstRowCenterSafetyBeltState 0 "SB Not monitored" 1 "SB unfastened" 2 "SB fastened" 3 "Unavailable";
VAL_ 1341 UPA_SoundRecurrenceType 0 "Discontinuous sound" 1 "Continuous sound";
VAL_ 1341 UPA_SystemState 0 "Manoeuvring Mode" 1 "Normal Mode" 2 "Standby Mode" 3 "Error Mode";
VAL_ 1341 UPA_Obstacle_Zone_Front_Right 0 "No detection" 1 "Reserve" 2 "Detect level 2 (70~50cm)" 3 "Detect level 3 (50~30cm)" 4 "Detect level 4 (30~cm)" 5 "Detect level 5" 6 "Reserve" 7 "Unavailable";
VAL_ 1341 UPA_Obstacle_Zone_Front_Left 0 "No detection" 1 "Reserve" 2 "Detect level 2 (70~50cm)" 3 "Detect level 3 (50~30cm)" 4 "Detect level 4 (30~cm)" 5 "Detect level 5" 6 "Reserve" 7 "Unavailable";
VAL_ 1341 UPA_Image_DisplayRequest 0 "No display request" 1 "Rear Detection ON" 2 "Front Detection ON" 3 "Front and Rear Detection ON";
VAL_ 1341 UPA_Obstacle_Zone_Rear_Right 0 "No detection" 1 "Detect level 1 (~70cm)" 2 "Detect level 2 (70~50cm)" 3 "Detect level 3 (50~30cm)" 4 "Detect level 4 (30~cm)" 5 "Detect level 5" 6 "Reserve" 7 "Unavailable";
VAL_ 1341 UPA_Obstacle_Zone_Rear_Left 0 "No detection" 1 "Detect level 1 (~70cm)" 2 "Detect level 2 (70~50cm)" 3 "Detect level 3 (50~30cm)" 4 "Detect level 4 (30~cm)" 5 "Detect level 5" 6 "Reserve" 7 "Unavailable";
VAL_ 1341 UPA_SoundActivationBeep 0 "No Request" 1 "Request";
VAL_ 1341 UPA_SoundErrorBeep 0 "No error sound" 1 "Error sound";
VAL_ 1341 UPA_Obstacle_Zone_Rear_Center 0 "No detection" 1 "Detect level 1 (   ~70cm)" 2 "Detect level 2 (70~50cm)" 3 "Detect level 3 (50~30cm)" 4 "Detect level 4 (30~cm)" 5 "Detect level 5" 6 "Reserve" 7 "Unavailable";
VAL_ 1341 UPA_Obstacle_Zone_Front_Center 0 "No detection" 1 "Detect level 1 (   ~70cm)" 2 "Detect level 2 (70~50cm)" 3 "Detect level 3 (50~30cm)" 4 "Detect level 4 (30~cm)" 5 "Detect level 5" 6 "Reserve" 7 "Unavailable";
VAL_ 1341 SensorAvailabilityFrontLeft 0 "Sensor not available" 1 "Sensor available";
VAL_ 1341 SensorAvailabilityFrontCenter 0 "Sensor not available" 1 "Sensor available";
VAL_ 1341 UPA_SoundObstacleZone 0 "No Sound" 1 "Sound front left" 2 "Sound front center" 3 "Sound front right" 4 "Sound rear left" 5 "Sound rear center" 6 "Sound rear right" 7 "reserved";
VAL_ 1341 UPAStatusDisplayRequest 0 "no upa status display request" 1 "Rear and front UPA de-activated" 2 "Rear UPA de-activated and front UPA activated" 3 "Not used" 4 "Rear UPA activated and front UPA de-activated" 5 "Sonar temporarily unavailable" 6 "Rear and front UPA activated" 7 "System Error";
VAL_ 1341 SensorAvailabilityFrontRight 0 "Sensor not available" 1 "Sensor available";
VAL_ 1341 SonarObstacleDistanceDisplay 0 "No detect / No display" 1 "Distance 1" 2 "Distance 2" 3 "Distance 3" 4 "Distance 4" 5 "Distance 5" 6 "Distance 6" 7 "Distance 7" 8 "Distance 8" 9 "Distance 9" 10 "Distance 10" 11 "Distance 11" 12 "Distance 12" 13 "Reserved" 14 "Reserved" 15 "Reserved";
VAL_ 1341 ParkAssistVolumeState 0 "Level 0 (off)" 1 "Level 1" 2 "Level 2" 3 "Level 3" 4 "Level 4" 5 "Level 5" 6 "Not used" 7 "Not used";
VAL_ 1341 SensorAvailabilityRearRight 0 "Sensor not available" 1 "Sensor available";
VAL_ 1341 SensorAvailabilityRearLeft 0 "Sensor not available" 1 "Sensor available";
VAL_ 1341 SensorAvailabilityRearCenter 0 "Sensor not available" 1 "Sensor available";
VAL_ 1341 UPA_ClosingAuthorization 0 "Not authorized" 1 "Authorized";
VAL_ 1341 BSWson_FunctionnalStatus 0 "Not used" 1 "Not available (function)" 2 "Available (function)" 3 "Unavailable";
VAL_ 1344 RegenBrakingLevelDisplay_Flash 0 "No request" 1 "Flashing requested";
VAL_ 1344 OBMAlarmRequest 0 "Alarm off" 1 "Alarm on";
VAL_ 1346 VSPfailureDisplay 0 "No display" 1 "Failure display";
VAL_ 1347 DynamicGridDisplayRequest 0 "No display" 1 "Grid display request";
VAL_ 1347 ATCVT_RangeIndicationForDisplay 0 "OFF" 1 "P range" 2 "R range" 3 "N range" 4 "D range" 5 "S range" 6 "L range" 7 "B range" 8 "1st range" 9 "2nd range" 10 "3rd range" 11 "4th range" 12 "5th range" 13 "6th range" 14 "7th range" 15 "8th range" 16 "9th range" 17 "10th range" 18 "Not used" 19 "Not used" 20 "M1st" 21 "M2nd" 22 "M3rd" 23 "M4th" 24 "M5th" 25 "M6th" 26 "M7th" 27 "M8th" 28 "M9th" 29 "M10th" 30 "Not used" 31 "Not used" 32 "Auto 1st" 33 "Auto 2nd" 34 "Auto 3rd" 35 "Auto 4th" 36 "Auto 5th" 37 "Auto 6th" 38 "Auto 7th" 39 "Auto 8th" 40 "Auto 9th" 41 "Auto 10th" 42 "Not used" 43 "Not used" 44 "Not used" 45 "Not used" 46 "Not used" 47 "Not used" 48 "Not used" 49 "Not used" 50 "Not used" 51 "Not used" 52 "Not used" 53 "Not used" 54 "Not used" 55 "Not used" 56 "Not used" 57 "Not used" 58 "Not used" 59 "Not used" 60 "Not used" 61 "Not used" 62 "Not used" 63 "Not used";
VAL_ 1355 RearRightMassageProgramState 0 "Massage not Running" 1 "Program 1 running" 2 "Program 2 running" 3 "Program 3 running" 4 "Program 4 running" 5 "Program 5 running" 6 "Program 6 running" 7 "Program 7 running" 8 "Program 8 running" 9 "Program 9 running" 10 "Program 10 running" 11 "Program 11 running" 12 "Program 12 running" 13 "Program 13 running" 14 "Program 14 running" 15 "Not used";
VAL_ 1355 RearRightMassageActivationState 0 "Massage OFF" 1 "Massage ON";
VAL_ 1355 RearLeftMassageActivationState 0 "Massage OFF" 1 "Massage ON";
VAL_ 1355 RearRightAutoReturnState 0 "AutoReturn OFF" 1 "AutoReturn ON";
VAL_ 1355 RearLeftAutoReturnState 0 "AutoReturn OFF" 1 "AutoReturn ON";
VAL_ 1355 Rear2RightSeatWalkinAlert 0 "No alert" 1 "Unlock status information" 2 "Lock request" 3 "Lock request during vehicle running";
VAL_ 1355 RearLeftMassageVelocityState 0 "No velocity" 1 "velocity 1" 2 "velocity 2" 3 "velocity 3" 4 "velocity 4" 5 "velocity 5" 6 "Not Used" 7 "Not Used";
VAL_ 1355 RearRightMassageIntensityState 0 "No intensity" 1 "Intensity 1" 2 "Intensity 2" 3 "Intensity 3" 4 "Intensity 4" 5 "Intensity 5" 6 "Not Used" 7 "Not Used";
VAL_ 1355 Rear2LeftReclinerPosition 0 "Standard position" 1 "Not standard position";
VAL_ 1355 RearLeftMassageProgramState 0 "Massage not Running" 1 "Program 1 running" 2 "Program 2 running" 3 "Program 3 running" 4 "Program 4 running" 5 "Program 5 running" 6 "Program 6 running" 7 "Program 7 running" 8 "Program 8 running" 9 "Program 9 running" 10 "Program 10 running" 11 "Program 11 running" 12 "Program 12 running" 13 "Program 13 running" 14 "Program 14 running" 15 "Not used";
VAL_ 1355 RearRightMassageVelocityState 0 "No velocity" 1 "velocity 1" 2 "velocity 2" 3 "velocity 3" 4 "velocity 4" 5 "velocity 5" 6 "Not Used" 7 "Not Used";
VAL_ 1355 Rear2RightReclinerPosition 0 "Standard position" 1 "Not standard position";
VAL_ 1355 Rear2LeftSeatFoldUnfoldState 0 "fixed position" 1 "on going" 2 "not used" 3 "unavailable";
VAL_ 1355 Rear2RightSeatFoldUnfoldState 0 "fixed position" 1 "on going" 2 "not used" 3 "unavailable";
VAL_ 1355 RearLeftMassageIntensityState 0 "No intensity" 1 "Intensity 1" 2 "Intensity 2" 3 "Intensity 3" 4 "Intensity 4" 5 "Intensity 5" 6 "Not Used" 7 "Not Used";
VAL_ 1355 DriverReclinerRequest 0 "no request" 1 "standard position request" 2 "return request" 3 "stop request";
VAL_ 1355 PassengerReclinerRequest 0 "no request" 1 "standard position request" 2 "return request" 3 "stop request";
VAL_ 1355 Rear2LeftSeatWalkinState 0 "fixed position" 1 "on going" 2 "not used" 3 "unavailable";
VAL_ 1355 Rear2RightSeatWalkinState 0 "fixed position" 1 "on going" 2 "not used" 3 "unavailable";
VAL_ 1355 RSCU2R_RefuseToSleep 0 "Reserved" 1 "Refuse to sleep" 2 "Ready to sleep" 3 "Reserved";
VAL_ 1355 Rear2RightSeatMovingState 0 "Not moving" 1 "Seat manual moving" 2 "Anti pinch detection" 3 "Walkin lock open" 4 "During walkin forward" 5 "During walkin backward" 6 "During folding" 7 "During unfolding";
VAL_ 1355 Rear2LeftSeatMovingState 0 "Not moving" 1 "Seat manual moving" 2 "Anti pinch detection" 3 "Walkin lock open" 4 "During walkin forward" 5 "During walkin backward" 6 "During folding" 7 "During unfolding";
VAL_ 1355 Rear2RightSeatBuzzerRequest 0 "No request" 1 "Start buzzer request" 2 "Completion buzzer request" 3 "Abnormal buzzer request";
VAL_ 1355 Rear2LeftSeatBuzzerRequest 0 "No request" 1 "Start buzzer request" 2 "Completion buzzer request" 3 "Abnormal buzzer request";
VAL_ 1355 Rear2LeftSeatWalkinAlert 0 "No alert" 1 "Unlock status information" 2 "Lock request" 3 "Lock request during vehicle running";
VAL_ 1360 ECM_ADASCarousel_SelectedADAS 0 "OFF" 1 "SL" 2 "CC" 3 "Not used";
VAL_ 1360 ECM_ADASCarousel_Content 0 "OFF / SL" 1 "OFF / CC / SL" 2 "Not used" 3 "Unavailable";
VAL_ 1360 CCSL_ContextualEvent_Selection 0 "No display" 1 "Proposal for current event" 2 "Validated for current event" 3 "Proposal for next event" 4 "Validated for next event" 5 "Proposal up for current event" 6 "Proposal down for current event" 7 "Unavailable";
VAL_ 1360 ECM_ADASCarousel_Display 0 "No display" 1 "ADAS carousel display";
VAL_ 1361 LCDN_ActivationState 0 "Unavailable" 1 "Activated" 2 "Deactivated" 3 "Not used";
VAL_ 1361 SRad_AlertStatusForCMS 0 "No alert" 1 "LeftSide LED_ON" 2 "RightSide LED_ON" 3 "LeftSide LED_ON and RightSide LED_ON" 4 "LeftSide Flash_ON" 5 "RightSide Flash_ON" 6 "LeftSide Flash_ON and RightSide Flash_ON" 7 "Not used";
VAL_ 1361 ACC_TargetDistanceAlert_v2 0 "No ACC warning" 1 "ACC approach warning" 2 "ACC collision warning" 3 "ACC cancel warning" 4 "ACC alert reminder" 5 "Not used" 6 "Not used" 7 "Not used";
VAL_ 1361 PredicSpeedConvertDisplayRequest 0 "No Display Request" 1 "Display Request";
VAL_ 1361 SET_OffsetValueLocal_State 0 "Unavailable" 1 "-10" 2 "-9" 3 "-8" 4 "-7" 5 "-6" 6 "-5" 7 "-4" 8 "-3" 9 "-2" 10 "-1" 11 "0" 12 "1" 13 "2" 14 "3" 15 "4" 16 "5" 17 "6" 18 "7" 19 "8" 20 "9" 21 "10" 22 "Not used" 23 "Not used" 24 "Not used" 25 "Not used" 26 "Not used" 27 "Not used" 28 "Not used" 29 "Not used" 30 "Not used" 31 "Not used";
VAL_ 1361 LCDN_SensibilityState 0 "Unavailable" 1 "Low sensibility" 2 "Middle sensibility" 3 "High sensibility";
VAL_ 1361 LCDN_AlertRequest 0 "No alert" 1 "LCDN level1 alert" 2 "LCDN level2 alert" 3 "LCDN with Distraction";
VAL_ 1361 AntiUndertake_TargetStatus 0 "No Display" 1 "Right Lane Motor bike" 2 "Left Lane Motor bike" 3 "Right Lane Truck" 4 "Left Lane Truck" 5 "Right Lane Car" 6 "Left Lane Car" 7 "Right Lane Unknown vehicle" 8 "Left Lane Unknown vehicle" 9 "Not used" 10 "Not used" 11 "Not used" 12 "Not used" 13 "Not used" 14 "Not used" 15 "Unavailable";
VAL_ 1361 AntiUndertake_ActivationStatus 0 "Deactivated" 1 "Activated" 2 "Not used" 3 "Unavailable";
VAL_ 1361 WDA_WarningDriverAttention_v2 0 "No display" 1 "Warning display" 2 "Reemission display" 3 "Not used";
VAL_ 1361 ELKA_OTOC_ActivationState 0 "Activated" 1 "Deactivated";
VAL_ 1361 LKA_DL_ActivationState 0 "Activated" 1 "Deactivated";
VAL_ 1361 ELKS_ActivationState 0 "Activated" 1 "Deactivated";
VAL_ 1361 AntiUndertakeDisplayRequest 0 "No Request" 1 "Request";
VAL_ 1361 DMS_CancelReason 0 "No display" 1 "HornPad Detected" 2 "Dust Detected" 3 "Number of People Detected" 4 "Obstacle Detected" 5 "Saturation Detected" 6 "Out of normal face area" 7 "Face Undetected" 8 "Eye Undetected" 9 "Out of range" 10 "EEPROM Failure Detected" 11 "Unexecuted Config Detected" 12 "Temporary Failure Detected" 13 "Permanent Failure Detected" 14 "Not used" 15 "Not used";
VAL_ 1364 ClimElecConsumptionLimitDisplay 0 "No display" 1 "Electrical Consumption Limitation ON" 2 "Electrical Consumption Limitation OFF" 3 "Unavailable";
VAL_ 1365 FAP_OperationSound 0 "Not requested" 1 "Type1 requested" 2 "Type2 requested" 3 "Type3 requested" 4 "Type4 requested" 5 "Type5 requested" 6 "Not Used" 7 "Not Used";
VAL_ 1365 AVM_MegaStatus 0 "Not support" 1 "OFF" 2 "ON" 3 "Reserved";
VAL_ 1365 AVM_RearendAttractFocusStatus 0 "SurroundLevel0FocusStatus" 1 "SurroundLevel1FocusStatus";
VAL_ 1365 AVM_MegaRequest 0 "Not requested" 1 "Requested";
VAL_ 1367 V2X_ID8_CLW_ActivationState 0 "Unactivated" 1 "Activated";
VAL_ 1367 V2X_Warning_VehicleType 0 "Invalid" 1 "Bus" 2 "Truck" 3 "Patrol Wagon" 4 "Ambulance" 5 "Fire Truck" 6 "Other Emergency Vehicle" 7 "CommonVehicle";
VAL_ 1367 V2X_LTA_WarningState 0 "Invalid" 1 "Warning Trigger";
VAL_ 1367 V2X_ICW_WarningState 0 "Invalid" 1 "Warning Trigger";
VAL_ 1367 V2X_CLW_WarningState 0 "Invalid" 1 "Warning Trigger";
VAL_ 1367 V2X_FCW_WarningState 0 "Invalid" 1 "Warning Trigger";
VAL_ 1367 V2X_ID12_VRUCW_ActivationState 0 "Unactivated" 1 "Activated";
VAL_ 1367 V2X_ID11_RLVW_ActivationState 0 "Unactivated" 1 "Activated";
VAL_ 1367 V2X_CLW_ControlLossType 0 "Invalid" 1 "ABS Loss Control" 2 "ESP Loss Control" 3 "TCS Loss Control" 4 "LDW Loss Control" 5 "Not used" 6 "Not used" 7 "Not used";
VAL_ 1367 V2X_RLVW_WarningState 0 "Invalid" 1 "Warning Trigger";
VAL_ 1367 V2X_VRUCW_WarningState 0 "Invalid" 1 "Warning Trigger";
VAL_ 1367 V2X_AVW_WarningState 0 "Invalid" 1 "Warning Trigger";
VAL_ 1367 V2X_MalfunctionState 0 "No Malfunction" 1 "Malfunction";
VAL_ 1367 V2X_ID16_GLOSA_ActivationState 0 "Unactivated" 1 "Activated";
VAL_ 1367 V2X_ID7_AVW_ActivationState 0 "Unactivated" 1 "Activated";
VAL_ 1367 V2X_ID3_LTA_ActivationState 0 "Unactivated" 1 "Activated";
VAL_ 1367 V2X_ID2_ICW_ActivationState 0 "Unactivated" 1 "Activated";
VAL_ 1367 V2X_ID1_FCW_ActivationState 0 "Unactivated" 1 "Activated";
VAL_ 1367 V2X_VRUCW_UserType 0 "Invalid" 1 "Pedestrian" 2 "Bike" 3 "Motorbike";
VAL_ 1367 V2X_SubFunctionSwitchState 0 "Table Value221794";
VAL_ 1367 V2X_GLOSA_LeftTurnLightColor 0 "Invalid" 1 "Red Light" 2 "Green Light" 3 "Yellow Light" 4 "Yellow Light Flash" 5 "Not used" 6 "Not used" 7 "Not used";
VAL_ 1367 V2X_GLOSA_RightTurnLightColor 0 "Invalid" 1 "Red Light" 2 "Green Light" 3 "Yellow Light" 4 "Yellow Light Flash" 5 "Not used" 6 "Not used" 7 "Not used";
VAL_ 1367 V2X_MainFunctionSwitchState 0 "V2X Main SwitchState OFF" 1 "V2X Main SwitchState ON";
VAL_ 1369 NextEvent_DisplayRequest 0 "No display" 1 "Next Event Speed Display" 2 "Next Event Type Display" 3 "Next Event Speed and Type Display";
VAL_ 1369 LCA_TransitionStateDisplay 0 "No display" 1 "LCA Activated Operational (activation Condition OK)" 2 "LCA Activated  - Safety Disclaimer" 3 "LCA Activated Not Operational (operation condition NOK)" 4 "LCA Deactivation Level1" 5 "LCA Disconnected Level 1" 6 "LCA Activated Not Operational (ACC OFF)" 7 "Not Used";
VAL_ 1369 Contextual_ModeStatus 0 "No Display" 1 "Prompt mode" 2 "Allow up" 3 "Allow down" 4 "Auto mode" 5 "Set speed changed by Auto TSR link" 6 "Set speed changed by Manual TSR link" 7 "Not Used";
VAL_ 1369 NextEvent_Speed 254 "Free Speed symbol";
VAL_ 1369 OSE_RearRightDoorAlert 0 "No alert" 1 "Level1" 2 "Level2" 3 "Not Used";
VAL_ 1369 OSE_RearLeftDoorAlert 0 "No alert" 1 "Level1" 2 "Level2" 3 "Not Used";
VAL_ 1369 OSE_FrontLeftDoorAlert 0 "No alert" 1 "Level1" 2 "Level2" 3 "Not Used";
VAL_ 1369 OSE_FronRightDoorAlert 0 "No alert" 1 "Level1" 2 "Level2" 3 "Not Used";
VAL_ 1369 ELKA_AlertLeftRequest 0 "No Alert" 1 "Oncoming Alert level 1" 2 "Oncoming Alert level 2" 3 "Overtaking Alert level 1" 4 "Overtaking Alert level 2" 5 "Roadedge Alert level 1" 6 "Roadedge Alert level 2" 7 "Alert reminder";
VAL_ 1369 RoadEvent_Alert 0 "No Request" 1 "Information" 2 "Warning" 3 "Not Used";
VAL_ 1369 NextEvent_Type 0 "No display" 1 "Right curve" 2 "Speed limit" 3 "Road exit right" 4 "Intersection" 5 "Roundabout" 6 "Stop" 7 "Tollbooth" 8 "Yield sign" 9 "Traffic light" 10 "Traffic jam" 11 "Road work" 12 "Left curve" 13 "Multicurve right-left" 14 "Multicurve left-right" 15 "Bump" 16 "T intersection" 17 "Road exit left" 18 "Slippery Road" 19 "End Of Queue" 20 "Stationary Vehicle" 21 "Broken down Vehicle" 22 "Accident Vehicle" 23 "Unknown Obstacle" 24 "Fog" 25 "Heavy Rain" 26 "Traffic light red" 27 "Traffic light green" 28 "Not used" 29 "Not used" 30 "Not used" 31 "Unavailable";
VAL_ 1369 ContextualEvent_Selection 0 "No display" 1 "Proposal for current event" 2 "Validated for current event" 3 "Proposal for next event" 4 "Validated for next event" 5 "Proposal up for current event" 6 "Proposal down for current event" 7 "Not Used";
VAL_ 1369 ELKA_AlertRightRequest 0 "No Alert" 1 "Oncoming Alert level 1" 2 "Oncoming Alert level 2" 3 "Overtaking Alert level 1" 4 "Overtaking Alert level 2" 5 "Roadedge Alert level 1" 6 "Roadedge Alert level 2" 7 "Alert reminder";
VAL_ 1369 OSE_DoorAlertReminder 0 "No Request" 1 "Left Reminder" 2 "Right Reminder" 3 "Left&Right Reminder";
VAL_ 1369 OSE_ActivationState 0 "Activated" 1 "Deactivated";
VAL_ 1369 ELKA_ActivationState 0 "Activated" 1 "Deactivated";
VAL_ 1369 EgoCarCenteringPosition 0 "Not Operative" 1 "Operative Left" 2 "Operative Center" 3 "Operative Right";
VAL_ 1369 SET_ADL3_State 0 "Invalid" 1 "OFF" 2 "ON" 3 "Not used";
VAL_ 1369 SET_ALCP2P_AlertLevel_State 0 "Invalid" 1 "Lv1" 2 "Lv2" 3 "Lv3";
VAL_ 1376 ChargeTimeDisplayAtEPrct 0 "No Display";
VAL_ 1380 TripUnitConsumption 0 "L / 100 km and kWh/100km" 1 "Km / L and km/kWh" 2 "MPGus and M/kWh (MPGe)" 3 "MPGuk and M/kWh (MPGe)" 4 "KWh / 100 Km" 5 "KWh / 100 miles" 6 "MPGe (US)" 7 "MPGe (UK)";
VAL_ 1380 FrostWarningDisplay 0 "No alert" 1 "Frost warning Alert";
VAL_ 1380 TripUnitDistance 0 "Km" 1 "Miles" 2 "not used" 3 "not used";
VAL_ 1380 MeterLanguageStatus 0 "Unavailable value" 1 "Language 1 à 253" 255 "Not used";
VAL_ 1380 ChargeConnectorLockModeRequest 0 "No request" 1 "Unlock Charging connector request" 2 "Lock Charging connector request" 3 "Auto lock Charging connector request";
VAL_ 1380 METER_MegaStatus 0 "Not support" 1 "System deactivated" 2 "Customer deactivated" 3 "Operational" 4 "Reserved" 5 "Reserved" 6 "Reserved" 7 "Unavailable";
VAL_ 1380 Shield_Request_METER 0 "No request" 1 "CustomShield request" 2 "Full shield request" 3 "Not used";
VAL_ 1380 Meter_FOTA_status 0 "Idle" 1 "Installation in progress" 2 "Copying in progress" 3 "Vehicle Condition check in progress" 4 "Ready for activation" 5 "Switch in progress" 6 "Reboot in progress" 7 "Component version check in progress" 8 "Configuration install in progress" 9 "Activation complete" 10 "Cancel in progress" 11 "Error detected" 12 "Update Error detected" 13 "Rollback in progress" 14 "Rollback complete" 15 "Ready for Slave Distribution" 16 "Slave Distribution in progress" 17 "Slave Integrity check in progress" 18 "Slave Distribution complete" 19 "Slave Installation in progress" 20 "Slave Copying in progress" 21 "Slave Installation complete" 22 "Not used" 23 "Not used" 24 "Not used" 25 "Not used" 26 "Not used" 27 "Not used" 28 "Not used" 29 "Not used" 30 "Not used" 31 "invalid";
VAL_ 1381 BSWrad_ActivationState 0 "Activated" 1 "Deactivated";
VAL_ 1381 BSWrad_SoundAlert 0 "No alert" 1 "Right alert" 2 "Left alert" 3 "Right and left alert";
VAL_ 1381 BSWrad_AlertStatus 0 "No alert" 1 "Right alert" 2 "Left alert" 3 "Right and left alert";
VAL_ 1381 CTA_AlertStatus 0 "No alert" 1 "Right alert" 2 "Left alert" 3 "Right and Left alert";
VAL_ 1381 CTA_FailureDisplay 0 "No display" 1 "Temporary failure display" 2 "Permanent failure display" 3 "Not used";
VAL_ 1381 BSWrad_SideDisplay 0 "No monitoring" 1 "Left and right side monitoring";
VAL_ 1381 CTA_CollisionRiskAlert 0 "Low collision risk" 1 "High collision risk";
VAL_ 1381 BSWrad_SideRadarCancelReason 0 "No display" 1 "Side radar Blocked" 2 "Reserved" 3 "Side radar permanent failure";
VAL_ 1381 CTA_CancelReason 0 "No display" 1 "SideRadar blocked" 2 "Trailer presence" 3 "SideRadar permanent failure";
VAL_ 1381 CTA_StatusDisplay_v2 0 "No display" 1 "Not operational" 2 "Operational" 3 "Temporary failure" 4 "Permanent failure" 5 "Obscuration caused by sliding door" 6 "Not Used" 7 "Not Used";
VAL_ 1381 BSWrad_StatusDisplay_v2 0 "No display" 1 "Not operational" 2 "Operational" 3 "Temporary failure" 4 "Permanent failure" 5 "Not Used" 6 "Not Used" 7 "Not Used";
VAL_ 1381 CTA_CancelReasonRER 0 "No request" 1 "Reemission request";
VAL_ 1384 MexModeState_v3 0 "Unavailable" 1 "MEX MODE ECO" 2 "MEX MODE MUD" 3 "MEX MODE MY SENSE" 4 "MEX MODE SPORT" 5 "Reserved" 6 "MEX MODE ECOPLUS" 7 "MEX MODE SNOW" 8 "MEX MODE OFFROAD" 9 "MEX MODE ALLROADS" 10 "MEX MODE PERSO" 11 "MEX MODE SAND" 12 "MEX MODE RACE" 13 "MEX MODE NORMAL" 14 "MEX MODE EXTREM" 15 "MEX MODE PERFO";
VAL_ 1384 MexAutoState 0 "Auto-adaptive function not active" 1 "Auto-adaptive function active";
VAL_ 1392 VSPsoundChoiceActivationRequest2 0 "No VSP Choice request" 1 "VSP Choice 1" 2 "VSP Choice 2" 3 "VSP Choice 3" 4 "VSP Choice 4" 5 "VSP Choice 5" 6 "Reset" 7 "Not used";
VAL_ 1392 VSPSoundActivationRequest2 0 "No VSP request" 1 "VSP activated" 2 "VSP no activated" 3 "Reset request";
VAL_ 1395 ePedalFailureDisplay 0 "No display" 1 "Failure 1 display" 2 "Not used" 3 "Not used" 4 "Not used" 5 "Not used" 6 "Not used" 7 "Not used";
VAL_ 1395 ePedalModeDisplayRequest 0 "No display" 1 "ePedal Mode Active ON";
VAL_ 1395 eAWD_WarningLamp 0 "No Alert" 1 "Alert";
VAL_ 1395 eAWD_HighTemp 0 "No Alert" 1 "Alert";
VAL_ 1395 ePedalMessageDisplayRequest 0 "No display" 1 "Limit Reason 1" 2 "Not used" 3 "Not used" 4 "Not used" 5 "Not used" 6 "Not used" 7 "Not used";
VAL_ 1402 CASP_ExtendedDisplayContext 0 "No direction" 1 "Right" 2 "Left" 3 "Uphill" 4 "Downhill" 5 "Kph" 6 "Mph" 7 "Not used";
VAL_ 1402 CASP_DisplayRequest 0 "No request" 1 "Advice" 2 "Reminder" 3 "Reserved";
VAL_ 1402 LDW_LKA_TransitionStateDisplay 0 "No display" 1 "LDW activated transition" 2 "LDW desactivated transition" 3 "LDW LKA Activation transition" 4 "LDW On LKA Off" 5 "LDW LKA Desactivation Transition" 6 "Switch Action unavailable" 7 "Not used";
VAL_ 1402 CASP_DisplayContext 0 "No request" 1 "Curve" 2 "Multicurves" 3 "Roundabout" 4 "Tolbooth" 5 "Stop sign" 6 "Give way" 7 "Mainroad exit" 8 "Intersection" 9 "Road work area" 10 "Traffic jam" 11 "Slope" 12 "Legal Speed" 13 "Traffic Light Recognition" 14 "reserved" 15 "--";
VAL_ 1402 RAB_SideRadarCancelReason 0 "No display" 1 "Side radar blocked" 2 "Reserved" 3 "Side radar permanent failure";
VAL_ 1402 BCI_StatusDisplay 0 "No display" 1 "Not operational" 2 "Operational" 3 "Not used";
VAL_ 1402 LDW_SensibilityState 0 "Unavailable" 1 "Low sensibility" 2 "Middle sensibility" 3 "High sensibility";
VAL_ 1402 LDW_ActivationState_v3 0 "Unavailable" 1 "Activated" 2 "Deactivated" 3 "Not used";
VAL_ 1402 LDW_LaneDisplay 0 "No display" 1 "Right lane monitoring" 2 "Left lane monitoring" 3 "Right and left lane monitoring";
VAL_ 1402 ProPILOTtransitionRequest 0 "No request" 1 "Request";
VAL_ 1402 LDW_SoundAlert 0 "No lane departure detected" 1 "Lane departure to right side detected" 2 "Lane departure to left side detected" 3 "Not Used";
VAL_ 1402 LKA_StatusDisplay_v2 0 "No display" 1 "Not operational" 2 "Operational" 3 "Temporary failure" 4 "Permanent failure" 5 "OFF Value" 6 "Not Used" 7 "Not Used";
VAL_ 1402 EAP_StatusDisplay 0 "No display" 1 "Not operational" 2 "Operational" 3 "Not used";
VAL_ 1402 LDW_StatusDisplay_v2 0 "No display" 1 "Not operational" 2 "Operational" 3 "Temporary failure" 4 "Permanent failure" 5 "OFF Value" 6 "Not Used" 7 "Not Used";
VAL_ 1402 AssistanceFunctionStatusDisplay 0 "No request" 1 "Request";
VAL_ 1402 LCA_StatusDisplay_v2 0 "No display" 1 "Not operational" 2 "Operational" 3 "Temporary failure" 4 "Permanent failure" 5 "MRM active" 6 "Not Used" 7 "Not Used";
VAL_ 1402 ELKA_StatusDisplay_v2 0 "No display" 1 "ELKA OFF" 2 "Operational" 3 "Not operational" 4 "Temporary failure" 5 "Permanent failure" 6 "Not Used" 7 "Not Used";
VAL_ 1402 WDA_StatusDisplay 0 "No display" 1 "Not operational" 2 "Operational" 3 "Not used";
VAL_ 1402 DCA_StatusDisplay 0 "No display" 1 "Not operational" 2 "Operational" 3 "Not used";
VAL_ 1402 DCA_FailureDisplay 0 "No display" 1 "Temporary failure display" 2 "Permanent failure display" 3 "Not used";
VAL_ 1402 WDA_FailureDisplay 0 "No display" 1 "Temporary failure display" 2 "Permanent failure display" 3 "Not used";
VAL_ 1404 SSA_SwitchReleaseDisplayRequest 0 "No Request" 1 "Display Request";
VAL_ 1404 SSA_SteepSlopeWarning_Request 0 "No Request" 1 "Steep Slope Warning Request 1" 2 "Steep Slope Warning Request 2" 3 "Invalid";
VAL_ 1404 ePedal_NotImmobilizedAlertReq 0 "No Alert" 1 "Vehicle not immobilized alert";
VAL_ 1406 RefuelingDisplay2_v2 0 "No request" 1 "Refuel Ready" 2 "Close Lid" 3 "Not used" 4 "Not used" 5 "Not used" 6 "Not used" 7 "Refuel Sysytem Failure" 8 "Lid Open Status s0" 9 "Lid Open Status s1" 10 "Lid Open Status s2" 11 "Lid Open Status s3" 12 "Lid Open Status s4" 13 "Lid Open Status s5" 14 "Lid Open Status s6" 15 "Lid Open Status s7" 16 "Lid Open Status s8" 17 "Lid Open Status s9" 18 "Lid Open Status s10" 19 "Lid Open Status l0" 20 "Lid Open Status l1" 21 "Lid Open Status l2" 22 "Lid Open Status l3" 23 "Lid Open Status l4" 24 "Lid Open Status l5" 25 "Lid Open Status l6" 26 "Lid Open Status l7" 27 "Lid Open Status l8" 28 "Lid Open Status l9" 29 "Lid Open Status l10" 30 "Not used" 31 "Not used";
VAL_ 1412 ClimHVpowerLimitationDisplay 0 "No display" 1 "Thermal Comfort available" 2 "SOC decreasing warning" 3 "No Thermal Comfort available";
VAL_ 1415 PhoneBatteryLevelDisplay 0 "No display" 1 "Low Battery" 2 "Level 1" 3 "Level 2" 4 "Level 3" 5 "Level 4" 6 "Level 5" 7 "Level 6";
VAL_ 1415 DisplayActivation 0 "No display" 1 "Display";
VAL_ 1415 PhoneReceptionLevelDisplay 0 "No display" 1 "No reception" 2 "Level 1" 3 "Level 2" 4 "Level 3" 5 "Level 4" 6 "Level 5" 7 "Level 6";
VAL_ 1415 ClockSetStatus 0 "Clock set" 1 "Clock not set";
VAL_ 1421 MC_SCCM_Position 0 "Unavailable" 1 "MC position 1" 2 "MC position 2" 3 "MC position 3" 4 "MC position 4" 5 "MC position 5" 6 "MC position 6" 7 "MC position 7" 8 "MC position 8" 9 "MC position 9" 10 "MC position 10" 11 "MC position 11" 12 "MC position 12" 13 "MC position 13" 14 "MC position 14" 15 "Position Change On Going";
VAL_ 1421 SCCM_TelescopicMovDisplayReq 0 "No display request" 1 "Telescopic forward display request" 2 "Telescopic backward display request" 3 "Not used";
VAL_ 1421 SCCM_TiltMovDisplayReq 0 "No display request" 1 "Tilt up display request" 2 "Tilt down display request" 3 "Not used";
VAL_ 1421 LOBM_SCCM_PositionStatus 0 "Unavailable" 1 "LOB position 1" 2 "LOB position 2" 3 "LOB position 3" 4 "LOB position 4" 5 "LOB position 5" 6 "LOB position 6" 7 "Position Change on going";
VAL_ 1422 DriverBackBolsterDisplayReq 0 "No display request" 1 "Backrest bolster increase Display Request" 2 "Backrest bolster decrease Display Request" 3 "Not monitored";
VAL_ 1422 MC_MovementDisplayRequest 0 "No display requested" 1 "Display requested";
VAL_ 1422 MC_ActivationState 0 "Magic Cockpit OFF" 1 "Magic Cockpit ON";
VAL_ 1422 MC_PositionChangeStatus 0 "Unavailable" 1 "MC position 1" 2 "MC position 2" 3 "MC position 3" 4 "MC position 4" 5 "MC position 5" 6 "MC position 6" 7 "MC position 7" 8 "MC position 8" 9 "MC position 9" 10 "MC position 10" 11 "MC position 11" 12 "MC position 12" 13 "MC position 13" 14 "MC position 14" 15 "Position Change On Going";
VAL_ 1422 MCM_PositionSaveRequest 0 "No request" 1 "Save MC position 1" 2 "Save MC position 2" 3 "Save MC position 3" 4 "Save MC position 4" 5 "Save MC position 5" 6 "Save MC position 6" 7 "Save MC position 7" 8 "Save MC position 8" 9 "Save MC position 9" 10 "Save MC position 10" 11 "Save MC position 11" 12 "Save MC position 12" 13 "Save MC position 13" 14 "Save MC position 14" 15 "Unavailable";
VAL_ 1422 MCM_PositionRecallRequest 0 "No request" 1 "Recall MC position 1" 2 "Recall MC position 2" 3 "Recall MC position 3" 4 "Recall MC position 4" 5 "Recall MC position 5" 6 "Recall MC position 6" 7 "Recall MC position 7" 8 "Recall MC position 8" 9 "Recall MC position 9" 10 "Recall MC position 10" 11 "Recall MC position 11" 12 "Recall MC position 12" 13 "Recall MC position 13" 14 "Recall MC position 14" 15 "Reset Request";
VAL_ 1422 DrLumbarDisplayRequest_Z_Axis 0 "No display request" 1 "Z Axis Upward" 2 "Z Axis Downward" 3 "Not monitored";
VAL_ 1422 MCM_TutorialRequest 0 "No request" 1 "On Going";
VAL_ 1422 MC_TutorialState 0 "Not Done" 1 "Done";
VAL_ 1422 MCM_PositionCalculate 0 "No Request (default value)" 1 "Calculate position 1" 2 "Calculate position 2" 3 "Calculate position 3" 4 "Calculate position 4" 5 "Calculate position 5" 6 "Calculate position 6" 7 "Calculate position 7" 8 "Calculate position 8" 9 "Calculate position 9" 10 "Calculate position 10" 11 "Calculate position 11" 12 "Calculate position 12" 13 "Calculate position 13" 14 "Calculate position 14" 15 "Calculate MC all positions";
VAL_ 1422 DriverCLADisplayRequest 0 "No Display Request" 1 "CLA Forward Display Request" 2 "CLA Backward Display Request" 3 "Not Used";
VAL_ 1422 DriverCushionBolsterDisplayReq 0 "No display request" 1 "Cushion bolster increase Display Request" 2 "Cushion bolster decrease Display Request" 3 "Not monitored";
VAL_ 1422 DrLumbarDisplayRequest_X_Axis 0 "No display request" 1 "X Axis Frontward" 2 "X Axis Backward" 3 "Not monitored";
VAL_ 1422 DriverMassageCondition 0 "Function not available" 1 "Function available";
VAL_ 1422 DriverSeatMovingState 0 "Not moving" 1 "Seat manual moving" 2 "Seat auto moving" 3 "Anti pinch detection";
VAL_ 1422 DriverReclinerPosition 0 "Standard position" 1 "Not standard position";
VAL_ 1432 AutoEngShutOffMenuDispReq 0 "No Request" 1 "Notification Request in Long Term(System Active)" 2 "Notification Request in Short Term(System Active)" 3 "Reactivation confirmation Request(System Deactive)";
VAL_ 1434 CPDActivationState 0 "Unavailable" 1 "Permanent OFF" 2 "Temporary OFF" 3 "CPD ON";
VAL_ 1434 CPDDisplayRequest 0 "No Display Request" 1 "Display Request";
VAL_ 1434 CPD_tempActivationState 0 "No Display" 1 "ON" 2 "Temporary OFF" 3 "Unavailable";
VAL_ 1434 CPD_OFFWarningRequest 0 "No Display" 1 "OFF Warning Request";
VAL_ 1434 CPD_AlertNotificationRequest 0 "No Request" 1 "Activation Popup Request" 2 "Warning Notification Request" 3 "Disconnect Notification Request" 4 "Not Used" 5 "Not Used" 6 "Not Used" 7 "Not Used";
VAL_ 1434 CPD_TelltaleActivationStatus 0 "Telltale OFF" 1 "Telltale ON";
VAL_ 1434 CPDWarningRequest 0 "No Display Request" 1 "Display Request";
VAL_ 1444 HUD_EffectiveDeployment 0 "HUD not deployed" 1 "HUD deployed";
VAL_ 1444 HUD_TSRactivationState 0 "Unavailable" 1 "Activated" 2 "De-activated" 3 "Not used";
VAL_ 1444 HUD_PositionState 0 "Step 1" 1 "Step 2" 2 "Step 3" 3 "Step 4" 4 "Step 5" 5 "Step 6" 6 "Step 7" 7 "Step 8" 8 "Step 9" 9 "Step 10" 10 "Step 11" 11 "Step 12" 12 "Step 13" 13 "Step 14" 14 "Step 15" 15 "Step 16" 16 "Step 17" 17 "Step 18" 18 "Step 19" 19 "Step 20" 20 "Step 21" 21 "Not used" 22 "Not used" 23 "Not used" 24 "Not used" 25 "Not used" 26 "Not used" 27 "Not used" 28 "Not used" 29 "Not used" 30 "Not used" 31 "Not used";
VAL_ 1444 HUD_ActivationState 0 "Unavailable" 1 "HUD activated" 2 "HUD de-activated" 3 "Not used";
VAL_ 1444 HUD_ADASactivationState 0 "Unavailable" 1 "Activated" 2 "De-activated" 3 "Not used";
VAL_ 1444 HUD_TurnByTurnActivationState 0 "Unavailable" 1 "Activated" 2 "De-activated" 3 "Not used";
VAL_ 1444 HUD_ITactivationState 0 "Unavailable" 1 "Activated" 2 "De-activated" 3 "Not used";
VAL_ 1444 HUD_DayLuminosityState 0 "Step 1" 1 "Step 2" 2 "Step 3" 3 "Step 4" 4 "Step 5" 5 "Step 6" 6 "Step 7" 7 "Step 8" 8 "Step 9" 9 "Step 10" 10 "Step 11" 11 "Step 12" 12 "Step 13" 13 "Step 14" 14 "Step 15" 15 "Step 16" 16 "Step 17" 17 "Step 18" 18 "Step 19" 19 "Step 20" 20 "Step 21" 21 "Not used" 22 "Not used" 23 "Not used" 24 "Not used" 25 "Not used" 26 "Not used" 27 "Not used" 28 "Not used" 29 "Not used" 30 "Not used" 31 "Not used";
VAL_ 1444 HUD_TelSMSactivationState 0 "Activated" 1 "No activated";
VAL_ 1444 HUD_NightLuminosityState 0 "Step 1" 1 "Step 2" 2 "Step 3" 3 "Step 4" 4 "Step 5" 5 "Step 6" 6 "Step 7" 7 "Step 8" 8 "Step 9" 9 "Step 10" 10 "Step 11" 11 "Step 12" 12 "Step 13" 13 "Step 14" 14 "Step 15" 15 "Step 16" 16 "Step 17" 17 "Step 18" 18 "Step 19" 19 "Step 20" 20 "Step 21" 21 "Not used" 22 "Not used" 23 "Not used" 24 "Not used" 25 "Not used" 26 "Not used" 27 "Not used" 28 "Not used" 29 "Not used" 30 "Not used" 31 "Not used";
VAL_ 1454 AFS_FailureDisplay 0 "No Failure" 1 "Failure on AFS";
VAL_ 1454 LevellingLimitAlert 0 "No alert" 1 "Alert";
VAL_ 1454 ManualLevellingPosition 0 "Position 0" 1 "Position 1" 2 "Position 2" 3 "Position 3" 4 "Position 4" 5 "Not used" 6 "Not used" 7 "Unavailable";
VAL_ 1455 VirtualKey_LowBatteryDisplay 0 "No Request" 1 "Display Request";
VAL_ 1456 VehicleZEVAutonomyERPDisplayed 0 "ERP Autonomy is NOT Displayed" 1 "ERP Autonomy is Displayed";
VAL_ 1457 AmbientLightingArea3Status 0 "AmbientLighting Area 3 Desactivated" 1 "AmbientLighting Area 3 Activated";
VAL_ 1457 AmbientLightingArea2Status 0 "AmbientLighting Area 2 Desactivated" 1 "AmbientLighting Area 2 Activated";
VAL_ 1457 AmbientLightingActivationStatus 0 "Deactivation State" 1 "Activation State";
VAL_ 1457 AmbientLightingArea1Status 0 "AmbientLighting Area 1 Desactivated" 1 "AmbientLighting Area 1 Activated";
VAL_ 1457 LightingSystemFailureDisplay 0 "No failure" 1 "Failure detected";
VAL_ 1457 CombiSwitchesFailureDisplay 0 "No alert" 1 "Alert";
VAL_ 1457 AmbientLightDayIntensityStatus 31 "Unavailable";
VAL_ 1458 EcoModePWTcancelReq 0 "No display request" 1 "Eco mode PWT alert" 2 "Eco mode PWT deactivated" 3 "Not used";
VAL_ 1458 RST_Boost_Launch_Ctrl_Alert_MMI 0 "No display request" 1 "Launch Control unavailable - Powertrain limitation" 2 "Launch Control unavailable - Incorrect PWT mode" 3 "Launch Control available - Release brake" 4 "Launch Control available - Kick-down" 5 "Boost unavailable - Powertrain limitation" 6 "Boost unavailable - Incorrect PWT mode" 7 "Reserved" 8 "Reserved" 9 "Reserved" 10 "Reserved" 11 "Reserved" 12 "Reserved" 13 "Reserved" 14 "Reserved" 15 "Reserved";
VAL_ 1459 MOD_ActivationState 0 "Activated" 1 "Deactivated";
VAL_ 1459 MOD_SoundAlertRequest_METER 0 "Sound alert not requested" 1 "Sound alert requested";
VAL_ 1464 DriverMassageActivationReq 0 "No request" 1 "Activation request" 2 "Deactivation request" 3 "Reset request";
VAL_ 1464 DriverSeatMemoRecallReq 0 "No recall" 1 "Recall of memorization 1" 2 "Recall of memorization 2" 3 "Recall of memorization 3" 4 "Recall of memorization 4" 5 "Recall of memorization 5" 6 "Recall of memorization 6" 7 "Reset Request";
VAL_ 1464 DriverSeatMemoRequest 0 "No request of memorization" 1 "Request of memorization 1" 2 "Request of memorization 2" 3 "Request of memorization 3" 4 "Request of memorization 4" 5 "Request of memorization 5" 6 "Request of memorization 6" 7 "Reset Request";
VAL_ 1464 DriverEasyAccessRequest2 0 "No request" 1 "Easy access activation requested" 2 "Easy access de-activation requested" 3 "Reset Request";
VAL_ 1464 DriverMassageIntensityReq 0 "No request" 1 "Intensity 1 requested" 2 "Intensity 2 requested" 3 "Intensity 3 requested" 4 "Intensity 4 requested" 5 "Intensity 5 requested" 6 "Not used" 7 "Reset request";
VAL_ 1464 PassengerMassageActivationReq 0 "No request" 1 "Activation request" 2 "Deactivation request" 3 "Reset request";
VAL_ 1464 DriverMassageVelocityReq 0 "No request" 1 "Velocity 1 requested" 2 "Velocity 2 requested" 3 "Velocity 3 requested" 4 "Velocity 4 requested" 5 "Velocity 5 requested" 6 "Not Used" 7 "Reset request";
VAL_ 1464 PassengerEasyAccessRequest 0 "No request" 1 "Easy access activation requested" 2 "Easy access de-activation requested" 3 "Reset Request";
VAL_ 1464 PassengerMassageVelocityReq 0 "No request" 1 "Velocity 1 requested" 2 "Velocity 2 requested" 3 "Velocity 3 requested" 4 "Velocity 4 requested" 5 "Velocity 5 requested" 6 "Not Used" 7 "Reset Request";
VAL_ 1464 PassengerMassageIntensityReq 0 "No request" 1 "Intensity 1 requested" 2 "Intensity 2 requested" 3 "Intensity 3 requested" 4 "Intensity 4 requested" 5 "Intensity 5 requested" 6 "Not used" 7 "Reset Request";
VAL_ 1466 TPMS_SetSupport 0 "No support" 1 "Support";
VAL_ 1466 EcoAdviceTirePressureRR 0 "No Advice" 1 "Advice";
VAL_ 1466 EcoAdviceTirePressureRL 0 "No Advice" 1 "Advice";
VAL_ 1466 EcoAdviceTirePressureFR 0 "No Advice" 1 "Advice";
VAL_ 1466 EcoAdviceTirePressureFL 0 "No Advice" 1 "Advice";
VAL_ 1468 DriverMassageVelocityState 0 "No velocity" 1 "velocity 1" 2 "velocity 2" 3 "velocity 3" 4 "velocity 4" 5 "velocity 5" 6 "Not Used" 7 "Not Used";
VAL_ 1468 DriverMassageIntensityState 0 "No intensity" 1 "Intensity 1" 2 "Intensity 2" 3 "Intensity 3" 4 "Intensity 4" 5 "Intensity 5" 6 "Not Used" 7 "Not Used";
VAL_ 1468 DriverSeatMemoStatus 0 "Seat Position 1" 1 "Seat Position 2" 2 "Seat Position 3" 3 "Seat Position 4" 4 "Seat Position 5" 5 "Seat Position 6" 6 "No Memorized Position" 7 "Not used";
VAL_ 1468 DriverReclinerDisplayRequest 0 "No Display Request" 1 "Recliner Moving Forward Display Request" 2 "Recliner Moving Backward Display Request" 3 "Not monitored";
VAL_ 1468 DriverFrontHeightDisplayRequest 0 "No Display Request" 1 "Raise Display Request" 2 "Descent Display Request" 3 "Not monitored";
VAL_ 1468 SeatSettingsDisplayRequest 0 "No Display Request" 1 "Seat Settings Display Request";
VAL_ 1468 DriverEasyAccessState 0 "Unavailable" 1 "Easy access activated" 2 "Easy access not activated" 3 "Not used";
VAL_ 1468 DriverBackHeightDisplayRequest 0 "No Display Request" 1 "Raise Display Request" 2 "Descent Display Request" 3 "Not monitored";
VAL_ 1468 DriverMassageActivationState 0 "Massage OFF" 1 "Massage ON";
VAL_ 1468 DriverSlidingDisplayRequest 0 "No Display Request" 1 "Sliding Forward Display Request" 2 "Sliding Backward Display Request" 3 "Not monitored";
VAL_ 1468 MirrorPositionMemoRequest 0 "No Request" 1 "Memorize Position 1 Request" 2 "Memorize Position 2 Request" 3 "Memorize Position 3 Request" 4 "Memorize Position 4 Request" 5 "Memorize Position 5 Request" 6 "Memorize Position 6 Request" 7 "Not used";
VAL_ 1468 MirrorPositionMemoRecall 0 "No Request" 1 "Position 1 Recall" 2 "Position 2 Recall" 3 "Position 3 Recall" 4 "Position 4 Recall" 5 "Position 5 Recall" 6 "Position 6 Recall" 7 "Not used";
VAL_ 1469 MeterVolumeRequest 0 "No request" 1 "Volume 1" 2 "Volume 2" 3 "Volume 3" 4 "Not used" 5 "Not used" 6 "Not used" 7 "Reset request";
VAL_ 1469 UnitDistanceDisplayRequest 0 "No request" 1 "display unit in km request" 2 "display unit in mph request" 3 "Reset request";
VAL_ 1469 DimmingReq 0 "No request" 1 "Step 1" 2 "Step 2" 3 "Step 3" 4 "Step 4" 5 "Step 5" 6 "Step 6" 7 "Step 7" 8 "Step 8" 9 "Step 9" 10 "Step 10" 11 "Step 11" 12 "Step 12" 13 "Step 13" 14 "Step 14" 15 "Step 15" 16 "Step 16" 17 "Step 17" 18 "Step 18" 19 "Step 19" 20 "Step 20" 21 "Step 21" 22 "Not used" 23 "Not used" 24 "Not used" 25 "Not used" 26 "Not used" 27 "Not used" 28 "Not used" 29 "Not used" 30 "Not used" 31 "Reset request";
VAL_ 1469 CockpitLanguageRequest 0 "No Language Request" 1 "Language 01h to FEh" 255 "Reset request";
VAL_ 1471 PassengerBackHeightDisplayReq 0 "No Display Request" 1 "Raise Display Request" 2 "Descent Display Request" 3 "Not monitored";
VAL_ 1471 PassengerSlidingDisplayRequest 0 "No Display Request" 1 "Sliding Forward Display Request" 2 "Sliding Backward Display Request" 3 "Not monitored";
VAL_ 1471 PassengerEasyAccessState 0 "Unavailable" 1 "Easy access activated" 2 "Easy access not activated" 3 "Not used";
VAL_ 1471 PassengerFrontHeightDisplayReq 0 "No Display Request" 1 "Raise Display Request" 2 "Descent Display Request" 3 "Not monitored";
VAL_ 1471 PassengerMassageIntensityState 0 "No intensity" 1 "Intensity 1" 2 "Intensity 2" 3 "Intensity 3" 4 "Intensity 4" 5 "Intensity 5" 6 "Not Used" 7 "Not Used";
VAL_ 1471 PassengerMassageVelocityState 0 "No velocity" 1 "velocity 1" 2 "velocity 2" 3 "velocity 3" 4 "velocity 4" 5 "velocity 5" 6 "Not Used" 7 "Not Used";
VAL_ 1471 PassengerMassageActivationState 0 "Massage OFF" 1 "Massage ON";
VAL_ 1471 PassengerSeatMMIRequest 0 "Multimedia Seat Settings Not Requested" 1 "Multimedia Seat Settings Requested";
VAL_ 1471 PassengerReclinerDisplayRequest 0 "No Display Request" 1 "Recliner Moving Forward Display Request" 2 "Recliner Moving Backward Display Request" 3 "Not monitored";
VAL_ 1479 MC_TutorialRequest_V2 0 "No Request" 1 "On going" 2 "Tuto well done" 3 "Not Used";
VAL_ 1480 ChargeRemainTimeEVSEconstraint 0 "No Display";
VAL_ 1480 ChargeSOCtargetEVSEconstraint 254 "No Display";
VAL_ 1480 ChargeTimeDisplayAtAPrct 0 "No Display";
VAL_ 1480 ChargeTimeDisplayAtBPrct 0 "No Display";
VAL_ 1480 ChargeTimeDisplayAtCPrct 0 "No Display";
VAL_ 1480 ChargeTimeDisplayAtDPrct 0 "No Display";
VAL_ 1486 ChargeAutonomyDisplayAtAPrct 0 "No Display";
VAL_ 1486 ChargeAutonomyDisplayAtBPrct 0 "No Display";
VAL_ 1486 ChargeAutonomyDisplayAtCPrct 0 "No Display";
VAL_ 1486 ChargeAutonomyDisplayAtDPrct 0 "No Display";
VAL_ 1486 ChargePowerEstimateDisplay 0 "No Display";
VAL_ 1486 ChargeAutonomyDisplayAtEPrct 0 "No Display";
VAL_ 1488 OffsetSpeedunit 0 "km/h" 1 "mile/h";
VAL_ 1488 OffsetActivation_State 0 "Deactivated" 1 "Activated" 2 "Not used" 3 "Unavailable";
VAL_ 1488 LCA_SteeringWheelTakeOverAlert 0 "No alert" 1 "Alert level 1" 2 "Alert level 2" 3 "Alert level 3" 4 "Alert level 4" 5 "Alert level 5" 6 "Alert level 6" 7 "Alert level 7";
VAL_ 1488 DetectedTargetDisplayRequest 0 "No detected target display requested" 1 "Detected FAR target display requested" 2 "Detected NEAR target display requested" 3 "Detected CLOSE1 target display requested" 4 "Detected CLOSE2 target display requested" 5 "Detected CLOSE3 target display requested" 6 "Not Used" 7 "Not Used";
VAL_ 1488 BSI_FailureDisplay 0 "No display" 1 "Temporary failure display" 2 "Permanent failure display" 3 "Not used";
VAL_ 1488 DW_StatusDisplay 0 "No display" 1 "Not operational" 2 "Operational" 3 "Not used";
VAL_ 1488 LDP_CameraCancelReason 0 "No display" 1 "Front Camera is blocked" 2 "Front Camera is overheat  (High Temperature)" 3 "Camera permanent failure" 4 "Reserved" 5 "Not used" 6 "Not used" 7 "Not used";
VAL_ 1488 DW_FollowUpTimeAlert 0 "No alert" 1 "Alert";
VAL_ 1488 OffsetValue_State 0 "Unavailable" 1 "-10" 2 "-9" 3 "-8" 4 "-7" 5 "-6" 6 "-5" 7 "-4" 8 "-3" 9 "-2" 10 "-1" 11 "0" 12 "1" 13 "2" 14 "3" 15 "4" 16 "5" 17 "6" 18 "7" 19 "8" 20 "9" 21 "10" 22 "Not used" 23 "Not used" 24 "Not used" 25 "Not used" 26 "Not used" 27 "Not used" 28 "Not used" 29 "Not used" 30 "Not used" 31 "Not used";
VAL_ 1488 BSI_CameraCancelReason 0 "No display" 1 "Front Camera is blocked" 2 "Front Camera is overheat  (High Temperature)" 3 "Camera permanent failure" 4 "Reserved" 5 "Not used" 6 "Not used" 7 "Not used";
VAL_ 1488 ACC_StatusDisplay_v2 0 "No display request" 1 "ACC waiting" 2 "ACC suspended" 3 "ACC activated" 4 "Temporary failure" 5 "Permanent failure" 6 "ACC override" 7 "Not Used";
VAL_ 1489 AntiUndertake_TargetVehicle_v2 0 "Table Value430653";
VAL_ 1490 HUD_RotationPositionState 0 "Step 1" 1 "Step 2" 2 "Step 3" 3 "Step 4" 4 "Step 5" 5 "Step 6" 6 "Step 7" 7 "Step 8" 8 "Step 9" 9 "Step 10" 10 "Step 11" 11 "Step 12" 12 "Step 13" 13 "Step 14" 14 "Step 15" 15 "Step 16" 16 "Step 17" 17 "Step 18" 18 "Step 19" 19 "Step 20" 20 "Step 21" 21 "Not used" 22 "Not used" 23 "Not used" 24 "Not used" 25 "Not used" 26 "Not used" 27 "Not used" 28 "Not used" 29 "Not used" 30 "Not used" 31 "Not used";
VAL_ 1490 HUD_SonaractivationState 0 "Activated" 1 "De-activated" 2 "Not Used" 3 "Unavailable";
VAL_ 1490 HUD_SSAActivationState 0 "Activated" 1 "De-activated" 2 "Not Used" 3 "Unavailable";
VAL_ 1490 HUD_ShiftActivationState 0 "Activated" 1 "De-activated" 2 "Not Used" 3 "Unavailable";
VAL_ 1491 AutoFrontWiperActivationRequest 0 "No automatic front wiper activation deactivation request" 1 "Automatic Front wiper activation requested" 2 "Automatic Front wiper de-activation requested" 3 "Automatic Front wiper Reset requested";
VAL_ 1491 AHL_ActivationRequest 0 "No Request" 1 "Automatic High Low beam activation requested" 2 "Automatic High Low beam de-activation requested" 3 "Reset Request";
VAL_ 1491 ParkAssistVolumeRequest 0 "No request " 1 "Level 0 (off)" 2 "Level 1" 3 "Level 2" 4 "Level 3" 5 "Level 4" 6 "Level 5" 7 "Reset request";
VAL_ 1491 IKeyAccessActivationRequest 0 "No Request" 1 "iKey Access Activation request" 2 "iKey Access Desactivation request" 3 "Reset Request";
VAL_ 1491 FrontRearWiperDropRequest 0 "No drop wiper activation de-activation request" 1 "Drop wiper activation requested" 2 "Drop wiper de-activation requested" 3 "Drop wiper reset requested";
VAL_ 1491 FrontParkAssistActivationReq 0 "No request" 1 "Front parking assistance activation requested" 2 "Front parking assistance de-activation requested" 3 "Reset Request";
VAL_ 1491 AutoRearWiperActivationRequest 0 "No automatic rear wiper activation de-activation request" 1 "Automatic Rear wiper activation requested" 2 "Automatic Rear wiper de-activation requested" 3 "Reset request";
VAL_ 1491 WGSactivationRequest 0 "No request" 1 "Activation" 2 "Deactivation" 3 "Reset request";
VAL_ 1491 SingleDoorOpeningActivationReq 0 "No single door opening request" 1 "Single door opening activation requested" 2 "Single door opening de-activation requested" 3 "Reset Request";
VAL_ 1491 RearParkAssistActivationReq 0 "No request" 1 "Rear parking assistance activation requested" 2 "Rear parking assistance de-activation requested" 3 "Reset Request";
VAL_ 1491 AutoLightSensitivityRequest 0 "No request" 1 "Configuration 1" 2 "Configuration 2" 3 "Configuration 3" 4 "Configuration 4" 5 "Not used" 6 "Not used" 7 "Reset request";
VAL_ 1491 AutoReLockActivationReq 0 "No Request" 1 "Auto ReLock ON request" 2 "Auto ReLock OFF request" 3 "Reset Value Request";
VAL_ 1491 MotorwayFlashersNumberRequest 0 "No request" 1 "1 flash per CSW mode request" 2 "3 flash per CSW mode request" 3 "5 flash per CSW mode request" 4 "Not used" 5 "Not used" 6 "Not used" 7 "Reset request";
VAL_ 1491 AutoFMHactivationRequest 0 "No request" 1 "Activation" 2 "Deactivation" 3 "Reset request";
VAL_ 1491 SilentModeActivationRequest 0 "No Request" 1 "Silent Mode Activation Request" 2 "Silent mode Deactivation Request" 3 "Reset Request";
VAL_ 1491 AutoLockActivationReq 0 "No request" 1 "Auto Lock with Speed Activation request" 2 "Auto Lock with Park-out Activation request" 3 "No Auto Lock" 4 "Not used" 5 "Not used" 6 "Not used" 7 "Reset Request";
VAL_ 1491 AutoUnLockActivationReq 0 "No Request" 1 "Auto UnLock with IGN OFF request" 2 "Auto UnLock with Park request" 3 "No Auto UnLock" 4 "Not used" 5 "Not used" 6 "Not used" 7 "Reset Request";
VAL_ 1491 ParkAssistSensitivityRequest 0 "No Request " 1 "Far Range Detection " 2 "Middle Range Detection" 3 "Near Range Detection" 4 "Not used" 5 "Not used " 6 "Not used" 7 "Reset Request";
VAL_ 1491 AutoFoldingActivationRequest 0 "No request" 1 "Disable" 2 "IGN Unfold" 3 "Unlock + IGN Unfold" 4 "Not used" 5 "Not used" 6 "Not used" 7 "Reset request";
VAL_ 1491 PredictiveShiftActivationRequest 0 "No request" 1 "Activation request" 2 "Deactivation request" 3 "Reset request";
VAL_ 1491 AirCondEcoActivationRequest 0 "No request" 1 "Eco activation request" 2 "Eco deactivation request" 3 "Reset request";
VAL_ 1491 CruiseEcoActivationRequest 0 "No request" 1 "Activation (Eco) request" 2 "De-activation (Normal) request" 3 "Reset request";
VAL_ 1491 AutoFMHdurationRequest 0 "No request" 1 "30 sec" 2 "45 sec" 3 "60 sec" 4 "90 sec" 5 "120 sec" 6 "150 sec" 7 "180 sec" 8 "Not used" 9 "Not used" 10 "Not used" 11 "Not used" 12 "Not used" 13 "Not used" 14 "Not used" 15 "Reset request";
VAL_ 1491 ISS_EcoActivationRequest 0 "No request" 1 "Eco activation request" 2 "Eco deactivation request" 3 "Reset request";
VAL_ 1498 AD_DistanceDuration 0 "No Display" 1023 "Unavailable Value";
VAL_ 1498 AD_TimeDuration 0 "No Display";
VAL_ 1498 AD_RouteAssist_Request 0 "No Request" 1 "Suggestion Request";
VAL_ 1498 SET_DMC_SensitivityState 0 "Unavailable" 1 "Low sensitivity" 2 "Middle sensitivity" 3 "High sensitivity";
VAL_ 1498 SET_ADL3_ChoiceState 0 "Invalid" 1 "OFF" 2 "ON" 3 "Not used";
VAL_ 1498 GTLN_ActivationState 0 "Unavailable" 1 "Activated" 2 "Deactivated" 3 "Not used";
VAL_ 1498 SET_RouteAssist_State 0 "Invalid" 1 "OFF" 2 "ON" 3 "Not used";
VAL_ 1501 TSR_OSP_SubsignAdditional_Zone3 0 "No Display" 1 "TIME area" 2 "SCHOOL area" 3 "Not Used";
VAL_ 1501 TSR_OSP_SubsignAdditional_Zone2 0 "No Display" 1 "TIME area" 2 "SCHOOL area" 3 "Not Used";
VAL_ 1501 TSR_OSP_SubsignAdditional_Zone1 0 "No Display" 1 "TIME area" 2 "SCHOOL area" 3 "Not Used";
VAL_ 1501 OverspeedAlertStatusDisplay 0 "No display" 1 "Activated" 2 "Deactivated" 3 "Failure";
VAL_ 1503 PassengerBackBolsterDisplayReq 0 "No display request" 1 "Backrest bolster increase Display Request" 2 "Backrest bolster decrease Display Request" 3 "Not monitored";
VAL_ 1503 PSCU_RefuseToSleep 0 "reserved" 1 "PSCU refuse to sleep" 2 "PSCU ready to sleep" 3 "reserved";
VAL_ 1503 PassengerSeatMemoAlertRequest 0 "No alert" 1 "Alert request";
VAL_ 1503 PassengerSeatMemoState 0 "Seat Position 1" 1 "Seat Position 2" 2 "Seat Position 3" 3 "Seat Position 4" 4 "Seat Position 5" 5 "Seat Position 6" 6 "Seat in No Position memorized" 7 "Not used";
VAL_ 1503 PassengerSwitchMassageRequest 0 "No massage request" 1 "Massage Request";
VAL_ 1503 PsgerCushionBolsterDisplayReq 0 "No display request" 1 "Cushion bolster increase Display Request" 2 "Cushion bolster decrease Display Request" 3 "Not monitored";
VAL_ 1503 PsLumbarDisplayRequest_Z_Axis 0 "No display request" 1 "Z Axis Upward" 2 "Z Axis Downward" 3 "Not monitored";
VAL_ 1503 PsLumbarDisplayRequest_X_Axis 0 "No display request" 1 "X Axis Frontward" 2 "X Axis Backward" 3 "Not monitored";
VAL_ 1503 PassengerReclinerPosition 0 "Standard position" 1 "Not standard position";
VAL_ 1503 PassengerCLADisplayRequest 0 "No Display Request" 1 "CLA Forward Display Request" 2 "CLA Backward Display Request" 3 "Not Used";
VAL_ 1503 PassengerOttomanMotorErrorState 0 "Normal" 1 "Motor position lost";
VAL_ 1503 PsMassagePopUpActivationState 0 "OFF" 1 "ON";
VAL_ 1503 PsMassageExecuteState 0 "No request" 1 "Massage execute failed" 2 "Massage execute forbid" 3 "Massage execute forbid for Ready OFF" 4 "Massage stop for Ready OFF" 5 "Not used" 6 "Not used" 7 "Not used";
VAL_ 1503 PassengerMassageCondition 0 "Function not available" 1 "Function available";
VAL_ 1503 PassengerSeatMovingState 0 "Not moving" 1 "Seat manual moving" 2 "Seat auto moving" 3 "Anti pinch detection";
VAL_ 1503 PassengerLifterMotorErrorState 0 "Normal" 1 "Motor position lost";
VAL_ 1503 PassengerReclinerMotorErrorState 0 "Normal" 1 "Motor position lost" 2 "Anti-pinch" 3 "Not used";
VAL_ 1503 PassengerMemoryPopUpReq 0 "No request" 1 "Display request";
VAL_ 1503 PassengerMemorySetState 0 "No request" 1 "Memory set forbid";
VAL_ 1503 PassengerMemoryRecallState 0 "No request" 1 "Seat execute failed" 2 "Seat execute forbid" 3 "Seat executing" 4 "Seat execute forbid for not in P mode" 5 "Stop for not in P mode" 6 "Not used" 7 "Not used";
VAL_ 1503 PassengerSlideMotorErrorState 0 "Normal" 1 "Motor position lost" 2 "Anti-pinch" 3 "Not used";
VAL_ 1506 RES_Switcher_Position_Status 0 "10min of RES" 1 "20min of RES" 2 "Reserved" 3 "Reserved";
VAL_ 1508 RESPreSoak_ProgStatus 0 "No programmed" 1 "1 time only (RES or Presoak)" 2 "Every two hours (5 times max)" 3 "Not used";
VAL_ 1508 RearSeatAlertActivationState 0 "Unavailable" 1 "Alert Message Activated" 2 "Alert Message and Horn Activated" 3 "Alert Deactivated";
VAL_ 1508 FrontWiperIntAutoSpeedStatus 0 "Unavailable" 1 "Level 1" 2 "Level 2" 3 "Level 3" 4 "Level 4" 5 "Level 5" 6 "Level 6" 7 "Level 7";
VAL_ 1508 RearWiperSwitchStatus 0 "Off" 1 "Intermittent" 2 "Continuous" 3 "Not used";
VAL_ 1508 LightSwitchStatus 0 "Off" 1 "Position lamps" 2 "Low beam" 3 "Auto";
VAL_ 1508 RearSeatAlertDisplayRequest 0 "No Display Request" 1 "Display Request";
VAL_ 1508 RearSeatAlertWarningRequest 0 "No Display Request" 1 "Display Request";
VAL_ 1508 FrontWiperSwitchStatus 0 "Off" 1 "Intermittent or auto" 2 "Low speed" 3 "High speed" 4 "Mist" 5 "Not used" 6 "Not used" 7 "Not used";
VAL_ 1508 InternalLightingIntensityState 0 "OFF" 1 "Level 1" 2 "Level 2" 3 "Level 3" 4 "Level 4" 5 "Level 5" 6 "Not used" 7 "Not used";
VAL_ 1508 CSW_Inconsistency_Ligthing_Alert 0 "No Display" 1 "Alert display" 2 "Reemission" 3 "Not used";
VAL_ 1508 AutoLowbeamReminder 0 "No display" 1 "Auto lowbeam reminder";
VAL_ 1508 DriverLightingRequestRefused 0 "No display" 1 "driver manual lighting request refused";
VAL_ 1508 AutoLightSystemStatusDisplay 0 "No display" 1 "ALS activation display";
VAL_ 1508 DriverManualWipingReqRefused 0 "No display" 1 "Driver Manual Wiping Request Refused";
VAL_ 1508 FrontWiperModeStatus 0 "Off" 1 "Auto" 2 "Low speed" 3 "High speed" 4 "Mist" 5 "Intermittent" 6 "Service position" 7 "Not Used";
VAL_ 1508 CSW_Inconsistency_Wiping_Alert 0 "No Display" 1 "Alert display" 2 "Reemission" 3 "Not used";
VAL_ 1510 FixedMaintenanceRange 254 "Fixed maintenance requested within one month" 255 "Fixed maintenance requested (time over)";
VAL_ 1510 AlertMinBeforeOverhaul 0 "No Alert " 1 "Time Prealert" 2 "Distance Prealert" 3 "Overhaul Alert";
VAL_ 1510 RES_Switcher_Position_Request 0 "No Request" 1 "10min of RES" 2 "20min of RES" 3 "Reserved" 4 "Reserved" 5 "Not Used" 6 "Not Used" 7 "Not Used";
VAL_ 1510 ExternalTempFaultFlag_v2 0 "No fault" 1 "High fault (short circuit to Bat, open load)" 2 "Low fault (short circuit to ground)" 3 "Out of range";
VAL_ 1510 MiniWashinglevelStatus 0 "No alert" 1 "Alert" 2 "Not used" 3 "Unavailable";
VAL_ 1510 PBDRadarActivationRequest 0 "No Request" 1 "Radar Measurement Inhibition Request" 2 "Radar Measurement Authorization Request" 3 "Reset request";
VAL_ 1510 HandleEjectionByApproach_Request 0 "No request" 1 "handle ejection by Approach  activation request" 2 "handle ejection by Approach deactivation request" 3 "Reset to factory value Request";
VAL_ 1510 ClusterSkinState_v2 0 "Skin1" 1 "Skin2" 2 "Skin3" 3 "Skin4" 4 "Skin5" 5 "Skin6" 6 "Skin7" 7 "Skin8" 8 "Skin9" 9 "Skin10" 10 "Skin11" 11 "Not used" 12 "Not used" 13 "Not used" 14 "Not used" 15 "Not used";
VAL_ 1511 ShippingModeFR 0 "No alert" 1 "Alert";
VAL_ 1511 ShippingModeFL 0 "No alert" 1 "Alert";
VAL_ 1511 ShippingModeRR 0 "No alert" 1 "Alert";
VAL_ 1511 ShippingModeRL 0 "No alert" 1 "Alert";
VAL_ 1511 TPMS_ActivationMode 0 "TPMS function ON" 1 "Without TPMS" 2 "TPMS function OFF" 3 "Unavailable";
VAL_ 1511 TPMS_LearningDone 0 "Default value or initial value ID not registed" 1 "ID learning by diag during transmitter ID learning" 2 "ID Learning is done - general state of status" 3 "Not used";
VAL_ 1511 WheelStateRL 0 "Pressure ok and no failure" 1 "Failure" 2 "Underinflation" 3 "Underinflation and failure" 4 "Puncture" 5 "Puncture and failure" 6 "Puncture and underinflation" 7 "Puncture and underinflation and failure";
VAL_ 1511 WheelStateRR 0 "Pressure ok and no failure" 1 "Failure" 2 "Underinflation" 3 "Underinflation and failure" 4 "Puncture" 5 "Puncture and failure" 6 "Puncture and underinflation" 7 "Puncture and underinflation and failure";
VAL_ 1511 TPMS_AckResetDriver 0 "Unvailable Value" 1 "Reset driver NOT  taken into account" 2 "Reset driver taken into account" 3 "Not Used";
VAL_ 1511 WheelStateFL 0 "Pressure ok and no failure" 1 "Failure" 2 "Underinflation" 3 "Underinflation and failure" 4 "Puncture" 5 "Puncture and failure" 6 "Puncture and underinflation" 7 "Puncture and underinflation and failure";
VAL_ 1511 WheelStateFR 0 "Pressure ok and no failure" 1 "Failure" 2 "Underinflation" 3 "Underinflation and failure" 4 "Puncture" 5 "Puncture and failure" 6 "Puncture and underinflation" 7 "Puncture and underinflation and failure";
VAL_ 1511 OldPressureFL 0 "Pressure up to date" 1 "Pressure not up to date";
VAL_ 1511 OldPressureFR 0 "Pressure up to date" 1 "Pressure not up to date";
VAL_ 1511 OldPressureRL 0 "Pressure up to date" 1 "Pressure not up to date";
VAL_ 1511 OldPressureRR 0 "Pressure up to date" 1 "Pressure not up to date";
VAL_ 1511 TPMS_AutoLocStatus 0 "init phase - or autolocation not avaliable (not present)" 1 "Autolocation is active" 2 "Autolocation finished OK" 3 "autolocation not OK";
VAL_ 1516 TSR_OSPActivationRequest 0 "No request" 1 "TSR/OSP ON request" 2 "TSR/OSP OFF request" 3 "Reset Requested";
VAL_ 1516 TPMS_PressureFrontAxleRequest 0 "No request" 63 "Reset request";
VAL_ 1516 TPMS_PressureRearAxleRequest 0 "No request" 63 "Reset request";
VAL_ 1516 LDW_ActivationRequest 0 "No request" 1 "LDW activation request" 2 "LDW de-activation request" 3 "Reset request";
VAL_ 1516 LDW_VibrationIntensityReq 0 "No request" 1 "Low intensity request" 2 "Middle intensity request" 3 "High intensity request" 4 "Not used" 5 "Not used" 6 "Not used" 7 "Reset request";
VAL_ 1516 LDW_SoundLevelRequest_v2 0 "No request" 1 "Level 0" 2 "Level 1" 3 "Level 2" 4 "Level 3" 5 "Level 4" 6 "Level 5" 7 "Reset request";
VAL_ 1516 SailingStopActivationRequest 0 "No Request" 1 "Sailing stop requested" 2 "Sailing stop not requested" 3 "Reset request";
VAL_ 1516 AEB_FCWactivationRequest 0 "No request" 1 "AEB OFF / FCW OFF" 2 "AEB OFF / FCW ON" 3 "AEB ON / FCW OFF" 4 "AEB ON / FCW ON" 5 "Not used" 6 "Not used" 7 "Reset request";
VAL_ 1516 LDW_SensibilityRequest 0 "No request" 1 "Low sensibility request" 2 "Middle sensibility request" 3 "High sensibility request" 4 "Not Used" 5 "Not Used" 6 "Not Used" 7 "Reset request";
VAL_ 1516 FKP_ActivationRequest 0 "No Request" 1 "Flank Protection NOT requested" 2 "Flank Protection Requested" 3 "Reset Request";
VAL_ 1516 MOD_ActivationRequest 0 "No request" 1 "Activation request" 2 "Deactivation request" 3 "Reset request";
VAL_ 1516 SonarAutoDisplayRequest 0 "No request" 1 "Auto Display Activated" 2 "Auto Display Deactivated" 3 "Reset request";
VAL_ 1516 DW_ActivationRequest 0 "No request" 1 "DW Activation request" 2 "DW Deactivation request" 3 "Reset request";
VAL_ 1516 BSWrad_ActivationRequest 0 "No request" 1 "Activation request" 2 "Deactivation request" 3 "Reset requested";
VAL_ 1516 HFP_DefaultManeuverTypeRequest 0 "no request" 1 "park in / parallel" 2 "park in / perpendicular" 3 "park in / angled" 4 "park out" 5 "Not used" 6 "Not used" 7 "Reset Request";
VAL_ 1516 LDP_ActivationRequest 0 "No request" 1 "Activation" 2 "Deactivation" 3 "Reset request";
VAL_ 1516 LKA_ActivationRequest 0 "No request" 1 "Activation" 2 "Deactivation" 3 "Reset request";
VAL_ 1516 SailingIdleActivationReq 0 "No request" 1 "Sailing idle activation Requested" 2 "Sailing idle deactivation Requested" 3 "Reset request";
VAL_ 1516 UTA_AlertActivationRequest 0 "No Request" 1 "UTA Alert activation Request" 2 "UTA Alert desactivation Request" 3 "Reset Request";
VAL_ 1516 BSI_ActivationRequest 0 "No resquest" 1 "Activation request" 2 "Deactivation request" 3 "Reset request";
VAL_ 1516 CTA_ActivationRequest 0 "No request" 1 "Activation" 2 "Deactivation" 3 "Reset request";
VAL_ 1516 AFS_ActivationRequest 0 "No request" 1 "Activation" 2 "Deactivation" 3 "Reset request";
VAL_ 1516 LCA_ActivationRequest 0 "No request" 1 "Activation" 2 "Deactivation" 3 "Reset request";
VAL_ 1519 UserSettingCopySource 0 "Not copy" 1 "Guest" 2 "User1" 3 "User2" 4 "User3" 5 "User4" 6 "User5" 7 "Not used";
VAL_ 1519 UserSettingCopyTarget 0 "Not copy" 1 "Guest" 2 "User1" 3 "User2" 4 "User3" 5 "User4" 6 "User5" 7 "Not used";
VAL_ 1519 User5_RegistrationState 0 "Not Registered" 1 "Registered";
VAL_ 1519 User4_RegistrationState 0 "Not Registered" 1 "Registered";
VAL_ 1519 KeyLinkInitializationState 0 "Initialization in progress" 1 "Initialization completed";
VAL_ 1519 KeyLinkActivationState 0 "Activate" 1 "Deactivate";
VAL_ 1519 User3_RegistrationState 0 "Not Registered" 1 "Registered";
VAL_ 1519 User2_RegistrationState 0 "Not Registered" 1 "Registered";
VAL_ 1519 User1_RegistrationState 0 "Not Registered" 1 "Registered";
VAL_ 1519 UserSettingCopyRequest 0 "No request" 1 "Request";
VAL_ 1519 CurrentUserState_v2 0 "Guest" 1 "User 1" 2 "User 2" 3 "User 3" 4 "User 4" 5 "User 5" 6 "Not used" 7 "Unavailable";
VAL_ 1519 UserProfileResetRequest 0 "No Request" 1 "Reset Profile 1" 2 "Reset Profile 2" 3 "Reset Profile 3" 4 "Reset Profile 4" 5 "Reset Profile 5" 6 "Reset Guest" 7 "Not used";
VAL_ 1519 MC_ActivationRequest 0 "No request" 1 "Magic Cockpit ON request" 2 "Magic Cockpit OFF request" 3 "Not used";
VAL_ 1519 MC_PositionRecallRequest 0 "No request" 1 "Recall MC position 1" 2 "Recall MC position 2" 3 "Recall MC position 3" 4 "Recall MC position 4" 5 "Recall MC position 5" 6 "Recall MC position 6" 7 "Recall MC position 7" 8 "Recall MC position 8" 9 "Recall MC position 9" 10 "Recall MC position 10" 11 "Recall MC position 11" 12 "Recall MC position 12" 13 "Recall MC position 13" 14 "Recall MC position 14" 15 "Reset Request";
VAL_ 1519 MC_PositionCalculate 0 "No Request (default value)" 1 "Calculate position 1" 2 "Calculate position 2" 3 "Calculate position 3" 4 "Calculate position 4" 5 "Calculate position 5" 6 "Calculate position 6" 7 "Calculate position 7" 8 "Calculate position 8" 9 "Calculate position 9" 10 "Calculate position 10" 11 "Calculate position 11" 12 "Calculate position 12" 13 "Calculate position 13" 14 "Calculate position 14" 15 "Calculate MC all positions";
VAL_ 1519 MC_PositionSaveRequest 0 "No request" 1 "Save MC position 1" 2 "Save MC position 2" 3 "Save MC position 3" 4 "Save MC position 4" 5 "Save MC position 5" 6 "Save MC position 6" 7 "Save MC position 7" 8 "Save MC position 8" 9 "Save MC position 9" 10 "Save MC position 10" 11 "Save MC position 11" 12 "Save MC position 12" 13 "Save MC position 13" 14 "Save MC position 14" 15 "Unavailable";
VAL_ 1523 HVchargeDisplay 0 "No request" 1 "Charge Meter HMI request";
